VERSION ""

NS_ :

BS_:

BU_: WRCS SRS LECM1 ECUspare6 CIOM CCM

BO_ 2566356800 CIOM_Cab_25S: 13 CIOM
 SG_ PHTimerTGWEvCmd_Timer3Recur_ISig : 28|4@1+ (1,0) [0|0] ""  CCM
 SG_ PHTimerTGWEvCmd_PhTimer1_cmd_ISi : 5|3@1+ (1,0) [0|0] ""  CCM
 SG_ PHTimerTGWEvCmd_Timer2Minutes_IS : 72|8@1+ (1,0) [0|255] "min"  CCM
 SG_ PHTimerTGWEvCmd_Timer2Hours_ISig : 48|8@1+ (1,0) [0|255] "h"  CCM
 SG_ PHTimerTGWEvCmd_Timer1Hours_ISig : 56|8@1+ (1,0) [0|255] "h"  CCM
 SG_ PHTimerTGWEvCmd_Timer3StartDay_I : 40|4@1+ (1,0) [0|0] ""  CCM
 SG_ PHTimerTGWEvCmd_Timer1Temp_ISig_ : 8|5@1+ (1,0) [0|0] ""  CCM
 SG_ PHTimerTGWEvCmd_Timer1Minutes_IS : 80|8@1+ (1,0) [0|255] "min"  CCM
 SG_ PHTimerTGWEvCmd_Timer2StartDay_I : 36|4@1+ (1,0) [0|0] ""  CCM
 SG_ PHTimerTGWEvCmd_PhTimer2_cmd_ISi : 21|3@1+ (1,0) [0|0] ""  CCM
 SG_ PHTimerTGWEvCmd_Timer2Temp_ISig_ : 16|5@1+ (1,0) [0|0] ""  CCM
 SG_ PHTimerTGWEvCmd_Timer1Duration_I : 96|7@1+ (1,0) [0|127] "min"  CCM
 SG_ PHTimerTGWEvCmd_Timer3Minutes_IS : 64|8@1+ (1,0) [0|255] "min"  CCM
 SG_ PHTimerTGWEvCmd_Timer1StartDay_I : 32|4@1+ (1,0) [0|0] ""  CCM
 SG_ PHTimerTGWEvCmd_Timer1Recur_ISig : 24|4@1+ (1,0) [0|0] ""  CCM
 SG_ PHTimerTGWEvCmd_Timer2Recur_ISig : 44|4@1+ (1,0) [0|0] ""  CCM
 SG_ PHTimerTGWEvCmd_PhTimer3_cmd_ISi : 13|3@1+ (1,0) [0|0] ""  CCM
 SG_ PHTimerTGWEvCmd_Timer3Temp_ISig_ : 0|5@1+ (1,0) [0|0] ""  CCM
 SG_ PHTimerTGWEvCmd_Timer3Hours_ISig : 88|8@1+ (1,0) [0|255] "h"  CCM

BO_ 2516128064 CIOM_Cab_24P: 8 CIOM
 SG_ Trailer1LiftAxles_LiftAxle2Id_IS : 4|4@1+ (1,0) [0|15] "ID"  WRCS
 SG_ Trailer4LiftAxles_LiftAxle1Pos_I : 44|2@1+ (1,0) [0|0] ""  WRCS
 SG_ Trailer2LiftAxles_LiftAxle1Pos_I : 20|2@1+ (1,0) [0|0] ""  WRCS
 SG_ Trailer2LiftAxles_LiftAxle2Id_IS : 16|4@1+ (1,0) [0|15] "ID"  WRCS
 SG_ Trailer2LiftAxles_LiftAxle2Pos_I : 22|2@1+ (1,0) [0|0] ""  WRCS
 SG_ Trailer4LiftAxles_LiftAxle2Pos_I : 46|2@1+ (1,0) [0|0] ""  WRCS
 SG_ Trailer5LiftAxles_LiftAxle2Id_IS : 52|4@1+ (1,0) [0|15] "ID"  WRCS
 SG_ Trailer4LiftAxles_LiftAxle1Id_IS : 36|4@1+ (1,0) [0|15] "ID"  WRCS
 SG_ Trailer3LiftAxles_LiftAxle2Id_IS : 28|4@1+ (1,0) [0|15] "ID"  WRCS
 SG_ Trailer2LiftAxles_LiftAxle1Id_IS : 12|4@1+ (1,0) [0|15] "ID"  WRCS
 SG_ Trailer5LiftAxles_LiftAxle1Pos_I : 56|2@1+ (1,0) [0|0] ""  WRCS
 SG_ Trailer1LiftAxles_LiftAxle1Id_IS : 0|4@1+ (1,0) [0|15] "ID"  WRCS
 SG_ Trailer3LiftAxles_LiftAxle1Pos_I : 32|2@1+ (1,0) [0|0] ""  WRCS
 SG_ Trailer5LiftAxles_LiftAxle1Id_IS : 48|4@1+ (1,0) [0|15] "ID"  WRCS
 SG_ Trailer1LiftAxles_LiftAxle2Pos_I : 10|2@1+ (1,0) [0|0] ""  WRCS
 SG_ Trailer5LiftAxles_LiftAxle2Pos_I : 58|2@1+ (1,0) [0|0] ""  WRCS
 SG_ Trailer3LiftAxles_LiftAxle1Id_IS : 24|4@1+ (1,0) [0|15] "ID"  WRCS
 SG_ Trailer1LiftAxles_LiftAxle1Pos_I : 8|2@1+ (1,0) [0|0] ""  WRCS
 SG_ Trailer3LiftAxles_LiftAxle2Pos_I : 34|2@1+ (1,0) [0|0] ""  WRCS
 SG_ Trailer4LiftAxles_LiftAxle2Id_IS : 40|4@1+ (1,0) [0|15] "ID"  WRCS

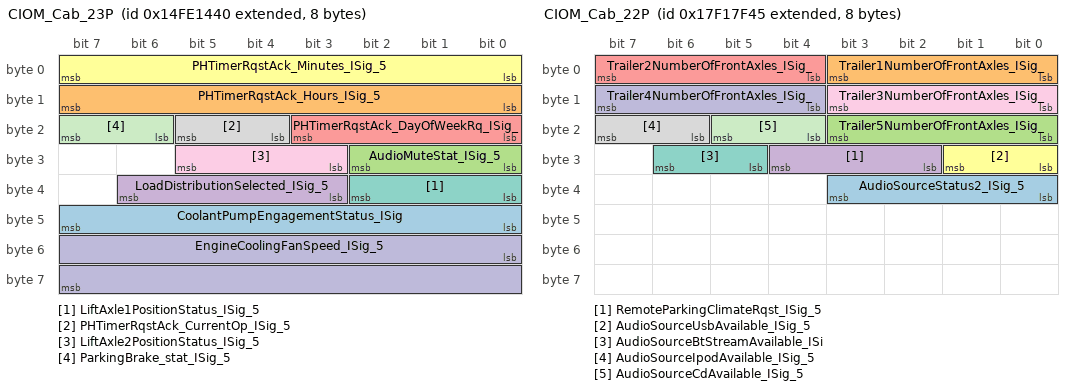
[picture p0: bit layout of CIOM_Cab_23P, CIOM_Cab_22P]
BO_ 2499679296 CIOM_Cab_23P: 8 CIOM
 SG_ CoolantPumpEngagementStatus_ISig : 40|8@1+ (0.4,0) [0|102] "Percent"  CCM
 SG_ PHTimerRqstAck_Hours_ISig_5 : 8|8@1+ (1,0) [0|255] "h"  CCM
 SG_ AudioMuteStat_ISig_5 : 24|3@1+ (1,0) [0|0] ""  LECM1
 SG_ LoadDistributionSelected_ISig_5 : 35|4@1+ (1,0) [0|0] ""  WRCS
 SG_ PHTimerRqstAck_DayOfWeekRq_ISig_ : 16|4@1+ (1,0) [0|0] ""  CCM
 SG_ PHTimerRqstAck_Minutes_ISig_5 : 0|8@1+ (1,0) [0|255] "min"  CCM
 SG_ LiftAxle1PositionStatus_ISig_5 : 32|3@1+ (1,0) [0|0] ""  WRCS
 SG_ PHTimerRqstAck_CurrentOp_ISig_5 : 20|2@1+ (1,0) [0|0] ""  CCM
 SG_ LiftAxle2PositionStatus_ISig_5 : 27|3@1+ (1,0) [0|0] ""  WRCS
 SG_ EngineCoolingFanSpeed_ISig_5 : 48|16@1+ (1,0) [0|65535] "rpm"  CCM
 SG_ ParkingBrake_stat_ISig_5 : 22|2@1+ (1,0) [0|0] ""  WRCS

BO_ 2549186373 CIOM_Cab_22P: 8 CIOM
 SG_ AudioSourceStatus2_ISig_5 : 32|4@1+ (1,0) [0|0] ""  LECM1
 SG_ Trailer1NumberOfFrontAxles_ISig_ : 0|4@1+ (1,0) [0|15] "NotApplicable"  WRCS
 SG_ Trailer5NumberOfFrontAxles_ISig_ : 16|4@1+ (1,0) [0|15] "NotApplicable"  WRCS
 SG_ RemoteParkingClimateRqst_ISig_5 : 26|3@1+ (1,0) [0|0] ""  CCM
 SG_ Trailer2NumberOfFrontAxles_ISig_ : 4|4@1+ (1,0) [0|15] "NotApplicable"  WRCS
 SG_ AudioSourceUsbAvailable_ISig_5 : 24|2@1+ (1,0) [0|0] ""  LECM1
 SG_ AudioSourceBtStreamAvailable_ISi : 29|2@1+ (1,0) [0|0] ""  LECM1
 SG_ AudioSourceIpodAvailable_ISig_5 : 22|2@1+ (1,0) [0|0] ""  LECM1
 SG_ Trailer3NumberOfFrontAxles_ISig_ : 8|4@1+ (1,0) [0|15] "NotApplicable"  WRCS
 SG_ Trailer4NumberOfFrontAxles_ISig_ : 12|4@1+ (1,0) [0|15] "NotApplicable"  WRCS
 SG_ AudioSourceCdAvailable_ISig_5 : 20|2@1+ (1,0) [0|0] ""  LECM1

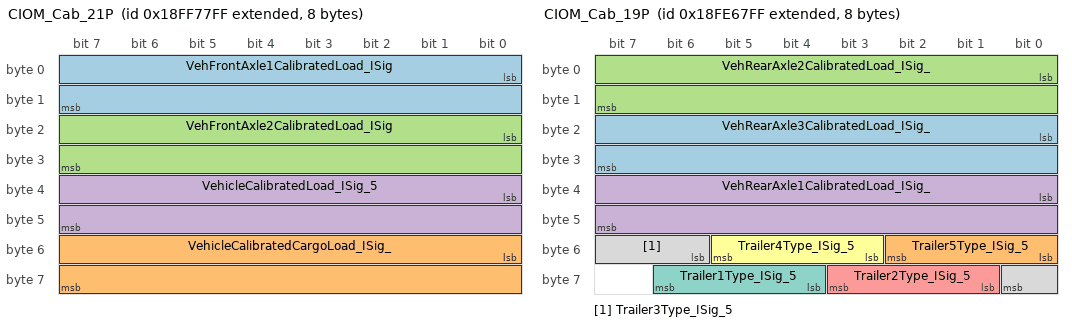
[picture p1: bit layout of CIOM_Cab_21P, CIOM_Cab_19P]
BO_ 2566879231 CIOM_Cab_21P: 8 CIOM
 SG_ VehFrontAxle1CalibratedLoad_ISig : 0|16@1+ (0.5,0) [0|32767.5] "kg"  WRCS
 SG_ VehicleCalibratedCargoLoad_ISig_ : 48|16@1+ (2,0) [0|131070] "kg"  WRCS
 SG_ VehFrontAxle2CalibratedLoad_ISig : 16|16@1+ (0.5,0) [0|32767.5] "kg"  WRCS
 SG_ VehicleCalibratedLoad_ISig_5 : 32|16@1+ (2,0) [0|131070] "kg"  WRCS

BO_ 2566864832 CIOM_Cab_20S_FCM: 8 LECM1
 SG_ CIOM_Cab_20S_FCS : 0|64@1+ (1,0) [0|0] ""  CIOM

BO_ 2566864831 CIOM_Cab_20S: 36 CIOM
 SG_ DisplayText_stat_ISig_5 : 0|288@1+ (1,0) [0|0] ""  LECM1

BO_ 2566809599 CIOM_Cab_19P: 8 CIOM
 SG_ VehRearAxle3CalibratedLoad_ISig_ : 16|16@1+ (0.5,0) [0|32767.5] "kg"  WRCS
 SG_ Trailer5Type_ISig_5 : 48|3@1+ (1,0) [0|0] ""  WRCS
 SG_ VehRearAxle2CalibratedLoad_ISig_ : 0|16@1+ (0.5,0) [0|32767.5] "kg"  WRCS
 SG_ VehRearAxle1CalibratedLoad_ISig_ : 32|16@1+ (0.5,0) [0|32767.5] "kg"  WRCS
 SG_ Trailer2Type_ISig_5 : 57|3@1+ (1,0) [0|0] ""  WRCS
 SG_ Trailer4Type_ISig_5 : 51|3@1+ (1,0) [0|0] ""  WRCS
 SG_ Trailer1Type_ISig_5 : 60|3@1+ (1,0) [0|0] ""  WRCS
 SG_ Trailer3Type_ISig_5 : 54|3@1+ (1,0) [0|0] ""  WRCS

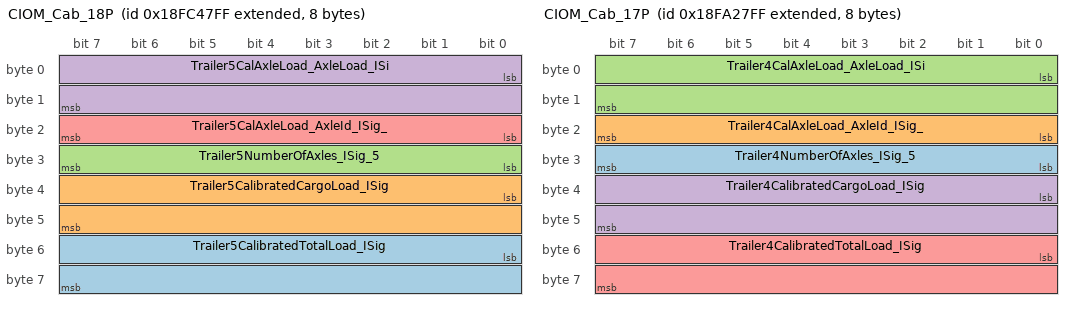
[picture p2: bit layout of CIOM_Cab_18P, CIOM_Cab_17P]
BO_ 2566670335 CIOM_Cab_18P: 8 CIOM
 SG_ Trailer5CalibratedTotalLoad_ISig : 48|16@1+ (2,0) [0|131070] "kg"  WRCS
 SG_ Trailer5CalibratedCargoLoad_ISig : 32|16@1+ (2,0) [0|131070] "kg"  WRCS
 SG_ Trailer5NumberOfAxles_ISig_5 : 24|8@1+ (1,0) [0|255] "NotApplicable"  WRCS
 SG_ Trailer5CalAxleLoad_AxleLoad_ISi : 0|16@1+ (0.5,0) [0|32767.5] "kg"  WRCS
 SG_ Trailer5CalAxleLoad_AxleId_ISig_ : 16|8@1+ (1,0) [0|255] "NotApplicable"  WRCS

BO_ 2566531071 CIOM_Cab_17P: 8 CIOM
 SG_ Trailer4NumberOfAxles_ISig_5 : 24|8@1+ (1,0) [0|255] "NotApplicable"  WRCS
 SG_ Trailer4CalAxleLoad_AxleId_ISig_ : 16|8@1+ (1,0) [0|255] "NotApplicable"  WRCS
 SG_ Trailer4CalAxleLoad_AxleLoad_ISi : 0|16@1+ (0.5,0) [0|32767.5] "kg"  WRCS
 SG_ Trailer4CalibratedCargoLoad_ISig : 32|16@1+ (2,0) [0|131070] "kg"  WRCS
 SG_ Trailer4CalibratedTotalLoad_ISig : 48|16@1+ (2,0) [0|131070] "kg"  WRCS

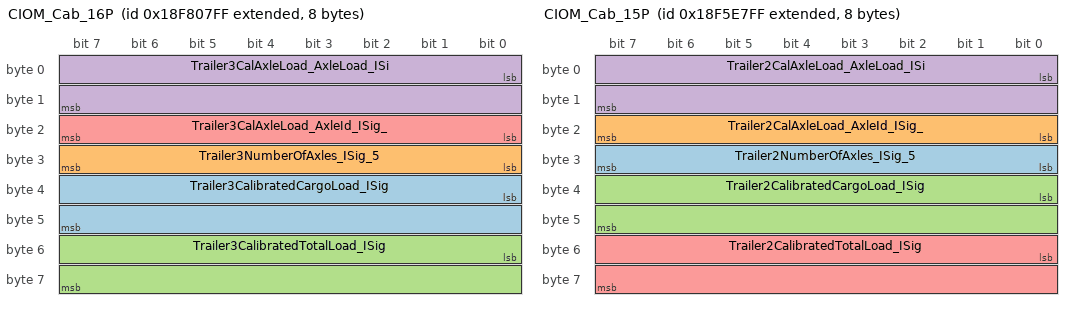
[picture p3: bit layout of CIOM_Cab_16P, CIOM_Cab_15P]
BO_ 2566391807 CIOM_Cab_16P: 8 CIOM
 SG_ Trailer3CalibratedCargoLoad_ISig : 32|16@1+ (2,0) [0|131070] "kg"  WRCS
 SG_ Trailer3NumberOfAxles_ISig_5 : 24|8@1+ (1,0) [0|255] "NotApplicable"  WRCS
 SG_ Trailer3CalibratedTotalLoad_ISig : 48|16@1+ (2,0) [0|131070] "kg"  WRCS
 SG_ Trailer3CalAxleLoad_AxleLoad_ISi : 0|16@1+ (0.5,0) [0|32767.5] "kg"  WRCS
 SG_ Trailer3CalAxleLoad_AxleId_ISig_ : 16|8@1+ (1,0) [0|255] "NotApplicable"  WRCS

BO_ 2566252543 CIOM_Cab_15P: 8 CIOM
 SG_ Trailer2NumberOfAxles_ISig_5 : 24|8@1+ (1,0) [0|255] "NotApplicable"  WRCS
 SG_ Trailer2CalAxleLoad_AxleId_ISig_ : 16|8@1+ (1,0) [0|255] "NotApplicable"  WRCS
 SG_ Trailer2CalibratedCargoLoad_ISig : 32|16@1+ (2,0) [0|131070] "kg"  WRCS
 SG_ Trailer2CalAxleLoad_AxleLoad_ISi : 0|16@1+ (0.5,0) [0|32767.5] "kg"  WRCS
 SG_ Trailer2CalibratedTotalLoad_ISig : 48|16@1+ (2,0) [0|131070] "kg"  WRCS

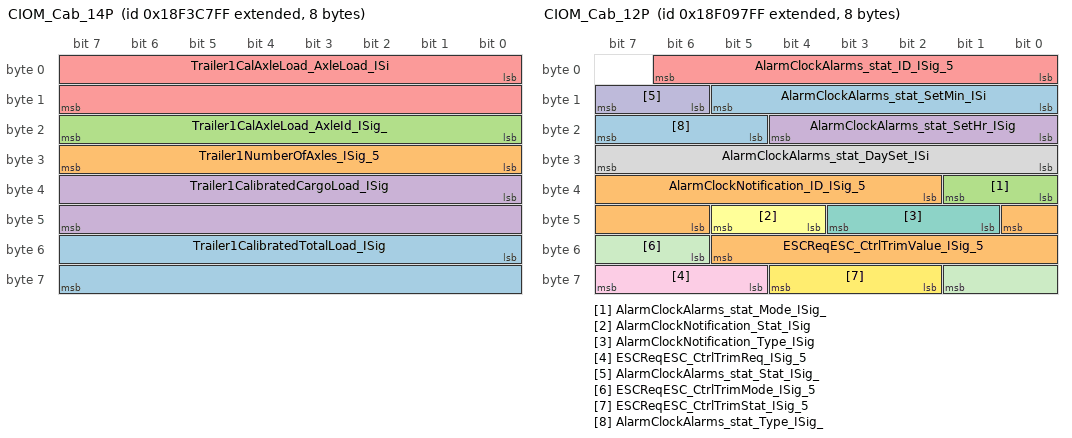
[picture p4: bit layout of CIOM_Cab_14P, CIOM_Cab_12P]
BO_ 2566113279 CIOM_Cab_14P: 8 CIOM
 SG_ Trailer1CalibratedTotalLoad_ISig : 48|16@1+ (2,0) [0|131070] "kg"  WRCS
 SG_ Trailer1NumberOfAxles_ISig_5 : 24|8@1+ (1,0) [0|255] "NotApplicable"  WRCS
 SG_ Trailer1CalAxleLoad_AxleId_ISig_ : 16|8@1+ (1,0) [0|255] "NotApplicable"  WRCS
 SG_ Trailer1CalibratedCargoLoad_ISig : 32|16@1+ (2,0) [0|131070] "kg"  WRCS
 SG_ Trailer1CalAxleLoad_AxleLoad_ISi : 0|16@1+ (0.5,0) [0|32767.5] "kg"  WRCS

BO_ 2565974016 CIOM_Cab_13S_FCM: 8 WRCS
 SG_ CIOM_Cab_13S_FCS : 0|64@1+ (1,0) [0|0] ""  CIOM

BO_ 2565974015 CIOM_Cab_13S: 128 CIOM
 SG_ FdEquipmentFreeText_ISig_5 : 0|1024@1+ (1,0) [0|0] ""  WRCS

BO_ 2565904383 CIOM_Cab_12P: 8 CIOM
 SG_ AlarmClockAlarms_stat_SetMin_ISi : 8|6@1+ (1,0) [0|63] "min"  LECM1
 SG_ ESCReqESC_CtrlTrimValue_ISig_5 : 46|8@1+ (10,0) [0|2550] ""  WRCS
 SG_ AlarmClockAlarms_stat_Mode_ISig_ : 32|2@1+ (1,0) [0|0] ""  LECM1
 SG_ AlarmClockAlarms_stat_SetHr_ISig : 16|5@1+ (1,0) [0|31] "h"  LECM1
 SG_ AlarmClockAlarms_stat_ID_ISig_5 : 0|7@1+ (1,0) [0|0] ""  LECM1
 SG_ AlarmClockNotification_Stat_ISig : 44|2@1+ (1,0) [0|0] ""  LECM1
 SG_ AlarmClockNotification_Type_ISig : 41|3@1+ (1,0) [0|0] ""  LECM1
 SG_ AlarmClockAlarms_stat_DaySet_ISi : 24|8@1+ (1,0) [0|255] ""  LECM1
 SG_ ESCReqESC_CtrlTrimReq_ISig_5 : 61|3@1+ (1,0) [0|0] ""  WRCS
 SG_ AlarmClockAlarms_stat_Stat_ISig_ : 14|2@1+ (1,0) [0|0] ""  LECM1
 SG_ ESCReqESC_CtrlTrimMode_ISig_5 : 54|4@1+ (1,0) [0|0] ""  WRCS
 SG_ ESCReqESC_CtrlTrimStat_ISig_5 : 58|3@1+ (1,0) [0|0] ""  WRCS
 SG_ AlarmClockAlarms_stat_Type_ISig_ : 21|3@1+ (1,0) [0|0] ""  LECM1
 SG_ AlarmClockNotification_ID_ISig_5 : 34|7@1+ (1,0) [0|0] ""  LECM1

BO_ 2565834752 CIOM_Cab_11S_FCM: 8 SRS
 SG_ CIOM_Cab_11S_FCS : 0|64@1+ (1,0) [0|0] ""  CIOM

BO_ 2565834751 CIOM_Cab_11S: 11 CIOM
 SG_ ECUVIN_stat : 0|88@1+ (1,0) [0|0] ""  SRS

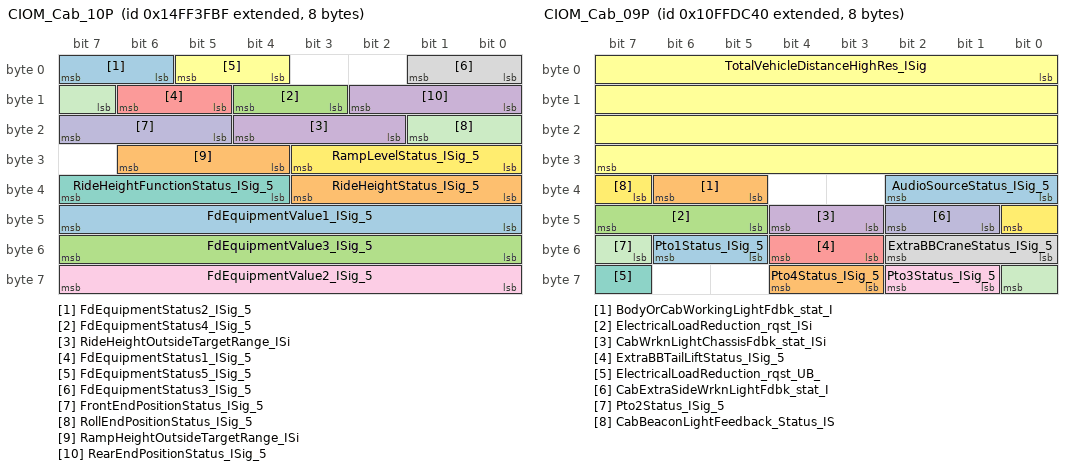
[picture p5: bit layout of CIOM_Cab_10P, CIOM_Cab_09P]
BO_ 2499755967 CIOM_Cab_10P: 8 CIOM
 SG_ FdEquipmentStatus2_ISig_5 : 6|2@1+ (1,0) [0|0] ""  WRCS
 SG_ RideHeightStatus_ISig_5 : 32|4@1+ (1,0) [0|0] ""  WRCS
 SG_ FdEquipmentStatus4_ISig_5 : 11|2@1+ (1,0) [0|0] ""  WRCS
 SG_ RideHeightOutsideTargetRange_ISi : 18|3@1+ (1,0) [0|0] ""  WRCS
 SG_ FdEquipmentStatus1_ISig_5 : 13|2@1+ (1,0) [0|0] ""  WRCS
 SG_ FdEquipmentStatus5_ISig_5 : 4|2@1+ (1,0) [0|0] ""  WRCS
 SG_ RideHeightFunctionStatus_ISig_5 : 36|4@1+ (1,0) [0|0] ""  WRCS
 SG_ FdEquipmentStatus3_ISig_5 : 0|2@1+ (1,0) [0|0] ""  WRCS
 SG_ FdEquipmentValue2_ISig_5 : 56|8@1+ (0.5,0) [0|127.5] "Percent"  WRCS
 SG_ FrontEndPositionStatus_ISig_5 : 21|3@1+ (1,0) [0|0] ""  WRCS
 SG_ RollEndPositionStatus_ISig_5 : 15|3@1+ (1,0) [0|0] ""  WRCS
 SG_ RampLevelStatus_ISig_5 : 24|4@1+ (1,0) [0|0] ""  WRCS
 SG_ FdEquipmentValue1_ISig_5 : 40|8@1+ (0.5,0) [0|127.5] "Percent"  WRCS
 SG_ RampHeightOutsideTargetRange_ISi : 28|3@1+ (1,0) [0|0] ""  WRCS
 SG_ FdEquipmentValue3_ISig_5 : 48|8@1+ (0.5,0) [0|127.5] "Percent"  WRCS
 SG_ RearEndPositionStatus_ISig_5 : 8|3@1+ (1,0) [0|0] ""  WRCS

BO_ 2432687168 CIOM_Cab_09P: 8 CIOM
 SG_ Pto1Status_ISig_5 : 53|2@1+ (1,0) [0|0] ""  WRCS
 SG_ BodyOrCabWorkingLightFdbk_stat_I : 37|2@1+ (1,0) [0|0] ""  WRCS
 SG_ ElectricalLoadReduction_rqst_ISi : 45|3@1+ (1,0) [0|0] ""  CCM,WRCS
 SG_ CabWrknLightChassisFdbk_stat_ISi : 43|2@1+ (1,0) [0|0] ""  WRCS
 SG_ ExtraBBTailLiftStatus_ISig_5 : 51|2@1+ (1,0) [0|0] ""  WRCS
 SG_ TotalVehicleDistanceHighRes_ISig : 0|32@1+ (5,0) [0|21474836475] "m"  SRS,LECM1,WRCS,CCM
 SG_ ElectricalLoadReduction_rqst_UB_ : 63|1@1+ (1,0) [0|0] ""  CCM,WRCS
 SG_ ExtraBBCraneStatus_ISig_5 : 48|3@1+ (1,0) [0|0] ""  WRCS
 SG_ Pto3Status_ISig_5 : 57|2@1+ (1,0) [0|0] ""  WRCS
 SG_ CabExtraSideWrknLightFdbk_stat_I : 41|2@1+ (1,0) [0|0] ""  WRCS
 SG_ Pto2Status_ISig_5 : 55|2@1+ (1,0) [0|0] ""  WRCS
 SG_ CabBeaconLightFeedback_Status_IS : 39|2@1+ (1,0) [0|0] ""  WRCS
 SG_ AudioSourceStatus_ISig_5 : 32|3@1+ (1,0) [0|0] ""  LECM1
 SG_ Pto4Status_ISig_5 : 59|2@1+ (1,0) [0|0] ""  WRCS

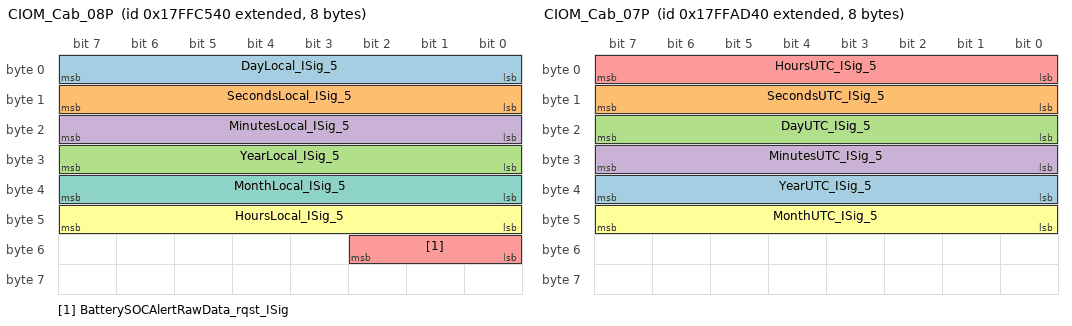
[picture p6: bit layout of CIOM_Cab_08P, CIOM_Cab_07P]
BO_ 2550121792 CIOM_Cab_08P: 8 CIOM
 SG_ DayLocal_ISig_5 : 0|8@1+ (0.25,0) [0|63.75] "Days"  CCM
 SG_ SecondsLocal_ISig_5 : 8|8@1+ (0.25,0) [0|63.75] "s"  CCM
 SG_ YearLocal_ISig_5 : 24|8@1+ (1,1985) [1985|2240] "Years"  CCM
 SG_ MinutesLocal_ISig_5 : 16|8@1+ (1,0) [0|255] "min"  CCM,LECM1
 SG_ BatterySOCAlertRawData_rqst_ISig : 48|3@1+ (1,0) [0|0] ""  CCM
 SG_ HoursLocal_ISig_5 : 40|8@1+ (1,0) [0|255] "h"  CCM,LECM1
 SG_ MonthLocal_ISig_5 : 32|8@1+ (1,0) [0|255] "Months"  CCM

BO_ 2550115648 CIOM_Cab_07P: 8 CIOM
 SG_ YearUTC_ISig_5 : 32|8@1+ (1,1985) [1985|2240] "Years"  LECM1,WRCS,SRS,CCM
 SG_ SecondsUTC_ISig_5 : 8|8@1+ (0.25,0) [0|63.75] "s"  LECM1,WRCS,CCM,SRS
 SG_ DayUTC_ISig_5 : 16|8@1+ (0.25,0) [0|63.75] "Days"  WRCS,SRS,LECM1,CCM
 SG_ MinutesUTC_ISig_5 : 24|8@1+ (1,0) [0|255] "min"  LECM1,CCM,WRCS,SRS
 SG_ HoursUTC_ISig_5 : 0|8@1+ (1,0) [0|255] "h"  LECM1,WRCS,SRS,CCM
 SG_ MonthUTC_ISig_5 : 40|8@1+ (1,0) [0|255] "Months"  WRCS,SRS,CCM,LECM1

BO_ 2432669248 CIOM_Cab_06P: 8 CIOM
 SG_ AuxSwitchBbLoad2_Status_ISig_5 : 22|2@1+ (1,0) [0|0] ""  WRCS
 SG_ DoorLock_stat_ISig_5 : 24|4@1+ (1,0) [0|0] ""  LECM1,WRCS
 SG_ MirrorHeatNormalModeInd_cmd_2_IS : 61|2@1+ (1,0) [0|0] ""  CCM
 SG_ PSWindowPosition_ISig_5 : 8|3@1+ (1,0) [0|0] ""  CCM
 SG_ AuxSwitchBbLoad1_Status_ISig_5 : 14|2@1+ (1,0) [0|0] ""  WRCS
 SG_ ReducedLoadMode_stat_ISig_5 : 0|2@1+ (1,0) [0|0] ""  CCM
 SG_ TrailersConnected_ISig_5 : 58|3@1+ (1,0) [0|7] "Count"  WRCS
 SG_ DriverDoorAjar_stat_ISig_5 : 4|3@1+ (1,0) [0|0] ""  CCM
 SG_ AuxSwitchBbLoad6_Status_ISig_5 : 56|2@1+ (1,0) [0|0] ""  WRCS
 SG_ BunkBacklightCmd_ISig_5 : 32|5@1+ (1,0) [0|0] ""  LECM1
 SG_ AuxSwitchBbLoad4_Status_ISig_5 : 46|2@1+ (1,0) [0|0] ""  WRCS
 SG_ DSWindowPosition_ISig_5 : 11|3@1+ (1,0) [0|0] ""  CCM
 SG_ SelectedLanguage_stat_ISig_5 : 40|6@1+ (1,0) [0|0] ""  LECM1,WRCS
 SG_ PassengerDoorAjar_stat_ISig_5 : 19|3@1+ (1,0) [0|0] ""  CCM
 SG_ BunkB1ParkHeaterTempSw_stat : 16|3@1+ (1,0) [0|0] ""  CCM
 SG_ AuxSwitchBbLoad5_Status_ISig_5 : 54|2@1+ (1,0) [0|0] ""  WRCS
 SG_ AudioVolumeIndicationCmd_ISig_5 : 48|6@1+ (1,0) [0|63] "Step"  LECM1
 SG_ AuxSwitchBbLoad3_Status_ISig_5 : 37|2@1+ (1,0) [0|0] ""  WRCS
 SG_ BunkH2TempInc_ButtonStatus : 2|2@1+ (1,0) [0|0] ""  CCM
 SG_ DayOfWeek_stat_ISig_5 : 28|4@1+ (1,0) [0|0] ""  CCM,LECM1

CM_ SG_ 2566356800 PHTimerTGWEvCmd_Timer2Minutes_IS "254 Error ; 255 Not available";
CM_ SG_ 2566356800 PHTimerTGWEvCmd_Timer2Hours_ISig "254 Error ; 255 Not available";
CM_ SG_ 2566356800 PHTimerTGWEvCmd_Timer1Hours_ISig "254 Error ; 255 Not available";
CM_ SG_ 2566356800 PHTimerTGWEvCmd_Timer1Minutes_IS "254 Error ; 255 Not available";
CM_ SG_ 2566356800 PHTimerTGWEvCmd_Timer1Duration_I "126 Error ; 127 Not available";
CM_ SG_ 2566356800 PHTimerTGWEvCmd_Timer3Minutes_IS "254 Error ; 255 Not available";
CM_ SG_ 2566356800 PHTimerTGWEvCmd_Timer3Hours_ISig "254 Error ; 255 Not available";
CM_ SG_ 2566879231 VehFrontAxle1CalibratedLoad_ISig "65024 - 65279 Error ; 65280 - 65535 Not available";
CM_ SG_ 2566879231 VehicleCalibratedCargoLoad_ISig_ "65024 - 65279 Error ; 65280 - 65535 Not Available";
CM_ SG_ 2566879231 VehFrontAxle2CalibratedLoad_ISig "65024 - 65279 Error ; 65280 - 65535 Not available";
CM_ SG_ 2566879231 VehicleCalibratedLoad_ISig_5 "65024 - 65279 Error ; 65280 - 65535 Not Available";
CM_ SG_ 2566809599 VehRearAxle3CalibratedLoad_ISig_ "65024 - 65279 Error ; 65280 - 65535 Not available";
CM_ SG_ 2566809599 VehRearAxle2CalibratedLoad_ISig_ "65024 - 65279 Error ; 65280 - 65535 Not available";
CM_ SG_ 2566809599 VehRearAxle1CalibratedLoad_ISig_ "65024 - 65279 Error ; 65280 - 65535 Not available";
CM_ SG_ 2566670335 Trailer5CalibratedTotalLoad_ISig "65024 - 65279 Error ; 65280 - 65535 Not Available";
CM_ SG_ 2566670335 Trailer5CalibratedCargoLoad_ISig "65024 - 65279 Error ; 65280 - 65535 Not Available";
CM_ SG_ 2566670335 Trailer5NumberOfAxles_ISig_5 "254 Error ; 255 Not Available";
CM_ SG_ 2566670335 Trailer5CalAxleLoad_AxleLoad_ISi "65024 - 65279 Error ; 65280 - 65535 Not available";
CM_ SG_ 2566531071 Trailer4NumberOfAxles_ISig_5 "254 Error ; 255 Not Available";
CM_ SG_ 2566531071 Trailer4CalAxleLoad_AxleLoad_ISi "65024 - 65279 Error ; 65280 - 65535 Not available";
CM_ SG_ 2566531071 Trailer4CalibratedCargoLoad_ISig "65024 - 65279 Error ; 65280 - 65535 Not Available";
CM_ SG_ 2566531071 Trailer4CalibratedTotalLoad_ISig "65024 - 65279 Error ; 65280 - 65535 Not Available";
CM_ SG_ 2566391807 Trailer3CalibratedCargoLoad_ISig "65024 - 65279 Error ; 65280 - 65535 Not Available";
CM_ SG_ 2566391807 Trailer3NumberOfAxles_ISig_5 "254 Error ; 255 Not Available";
CM_ SG_ 2566391807 Trailer3CalibratedTotalLoad_ISig "65024 - 65279 Error ; 65280 - 65535 Not Available";
CM_ SG_ 2566391807 Trailer3CalAxleLoad_AxleLoad_ISi "65024 - 65279 Error ; 65280 - 65535 Not available";
CM_ SG_ 2566252543 Trailer2NumberOfAxles_ISig_5 "254 Error ; 255 Not Available";
CM_ SG_ 2566252543 Trailer2CalibratedCargoLoad_ISig "65024 - 65279 Error ; 65280 - 65535 Not Available";
CM_ SG_ 2566252543 Trailer2CalAxleLoad_AxleLoad_ISi "65024 - 65279 Error ; 65280 - 65535 Not available";
CM_ SG_ 2566252543 Trailer2CalibratedTotalLoad_ISig "65024 - 65279 Error ; 65280 - 65535 Not Available";
CM_ SG_ 2566113279 Trailer1CalibratedTotalLoad_ISig "65024 - 65279 Error ; 65280 - 65535 Not Available";
CM_ SG_ 2566113279 Trailer1NumberOfAxles_ISig_5 "254 Error ; 255 Not Available";
CM_ SG_ 2566113279 Trailer1CalibratedCargoLoad_ISig "65024 - 65279 Error ; 65280 - 65535 Not Available";
CM_ SG_ 2566113279 Trailer1CalAxleLoad_AxleLoad_ISi "65024 - 65279 Error ; 65280 - 65535 Not available";
CM_ SG_ 2565904383 AlarmClockAlarms_stat_SetMin_ISi "62 Error ; 63 Not Available";
CM_ SG_ 2565904383 ESCReqESC_CtrlTrimValue_ISig_5 "254 Error ; 255 Not available";
CM_ SG_ 2565904383 AlarmClockAlarms_stat_SetHr_ISig "30 Error ; 31 Not Available";
CM_ SG_ 2499755967 FdEquipmentValue2_ISig_5 "254 Error ; 255 Not available";
CM_ SG_ 2499755967 FdEquipmentValue1_ISig_5 "254 Error ; 255 Not available";
CM_ SG_ 2499755967 FdEquipmentValue3_ISig_5 "254 Error ; 255 Not available";
CM_ SG_ 2432687168 TotalVehicleDistanceHighRes_ISig "4261412864 - 4278190079 Error ; 4278190080 - 4294967295 Not available";
CM_ SG_ 2550121792 DayLocal_ISig_5 "254 Error ; 255 Not available";
CM_ SG_ 2550121792 SecondsLocal_ISig_5 "254 Error ; 255 Not available";
CM_ SG_ 2550121792 YearLocal_ISig_5 "254 Error ; 255 Not available";
CM_ SG_ 2550121792 MinutesLocal_ISig_5 "254 Error ; 255 Not available";
CM_ SG_ 2550121792 HoursLocal_ISig_5 "254 Error ; 255 Not available";
CM_ SG_ 2550121792 MonthLocal_ISig_5 "254 Error ; 255 Not available";
CM_ SG_ 2550115648 YearUTC_ISig_5 "254 Error ; 255 Not available";
CM_ SG_ 2550115648 SecondsUTC_ISig_5 "254 Error ; 255 Not available";
CM_ SG_ 2550115648 DayUTC_ISig_5 "254 Error ; 255 Not available";
CM_ SG_ 2550115648 MinutesUTC_ISig_5 "254 Error ; 255 Not available";
CM_ SG_ 2550115648 HoursUTC_ISig_5 "254 Error ; 255 Not available";
CM_ SG_ 2550115648 MonthUTC_ISig_5 "254 Error ; 255 Not available";
CM_ SG_ 2432669248 TrailersConnected_ISig_5 "6 Error ; 7 Not available";
BA_DEF_ BO_  "GenMsgStartDelayTime" INT 0 0;
BA_DEF_ BO_  "GenMsgDelayTime" INT 0 0;
BA_DEF_ BO_  "GenMsgCycleTime" INT 0 0;
BA_DEF_ BO_  "GenMsgSendType" ENUM  "Cyclic","NotUsed","NotUsed","NotUsed","NotUsed","NotUsed","NotUsed","IfActive","NoMsgSendType","NotUsed";
BA_DEF_ SG_  "GenSigStartValue" INT 0 0;
BA_DEF_ SG_  "GenSigCycleTimeActive" INT 0 0;
BA_DEF_ SG_  "GenSigCycleTime" INT 0 0;
BA_DEF_ SG_  "GenSigSendType" ENUM  "Cyclic","OnWrite","OnWriteWithRepetition","OnChange","OnChangeWithRepetition","IfActive","IfActiveWithRepetition","NoSigSendType","NotUsed","NotUsed","NotUsed","NotUsed","NotUsed";
BA_DEF_ BO_  "VFrameFormat" ENUM  "StandardCAN","ExtendedCAN","reserved","J1939PG";
BA_DEF_ SG_  "SigType" ENUM  "Default","Range","RangeSigned","ASCII","Discrete","Control","ReferencePGN","DTC","StringDelimiter","StringLength","StringLengthControl";
BA_DEF_ SG_  "SeToolVersion_SIGNAL" STRING ;
BA_DEF_ SG_  "SeToolUniqueID_SIGNAL" STRING ;
BA_DEF_ SG_  "SeToolOwnerSigGroup_SIGNAL" STRING ;
BA_DEF_ SG_  "SeToolOwnerSigGroupID_SIGNAL" STRING ;
BA_DEF_ SG_  "SeToolName_SIGNAL" STRING ;
BA_DEF_ SG_  "SeToolItemID_SIGNAL" STRING ;
BA_DEF_ SG_  "SeToolAncestorID_SIGNAL" STRING ;
BA_DEF_ BO_  "NmAsrMessage" ENUM  "No","Yes";
BA_DEF_ SG_  "NeedsUpdateBit" ENUM  "No","Yes";
BA_DEF_ SG_  "MmAnSignal" ENUM  "No","Yes";
BA_DEF_ SG_  "GenSigMaxLatency" INT 0 65535;
BA_DEF_ SG_  "GenSigILSupport" ENUM  "Yes","No";
BA_DEF_ BO_  "GenMsgRequestable" INT 0 1;
BA_DEF_ BO_  "GenMsgILSupport" ENUM  "No","Yes";
BA_DEF_ BO_  "DiagUUDTResponse" ENUM  "No","Yes";
BA_DEF_ BO_  "DiagState" ENUM  "No","Yes";
BA_DEF_ BO_  "DiagResponse" ENUM  "No","Yes";
BA_DEF_ BO_  "DiagRequest" ENUM  "No","Yes";
BA_DEF_ BO_  "DiagConnection" HEX 0 65535;
BA_DEF_ BO_  "CanTpSTmin" INT 0 255;
BA_DEF_ BO_  "CanTpFcFrameId" HEX 0 2147483647;
BA_DEF_ BO_  "CanTpBs" INT 0 255;
BA_DEF_ SG_  "SystemSignalLongSymbol" STRING ;
BA_DEF_REL_ BU_SG_REL_  "GenSigTimeoutTime" INT 0 65535;
BA_DEF_REL_ BU_SG_REL_  "GenSigFirstTimeoutTime" INT 0 65535;
BA_DEF_DEF_  "GenMsgStartDelayTime" 0;
BA_DEF_DEF_  "GenMsgDelayTime" 0;
BA_DEF_DEF_  "GenMsgCycleTime" 0;
BA_DEF_DEF_  "GenMsgSendType" "Cyclic";
BA_DEF_DEF_  "GenSigStartValue" 0;
BA_DEF_DEF_  "GenSigCycleTimeActive" 0;
BA_DEF_DEF_  "GenSigCycleTime" 0;
BA_DEF_DEF_  "GenSigSendType" "Cyclic";
BA_DEF_DEF_  "VFrameFormat" "ExtendedCAN";
BA_DEF_DEF_  "SigType" "Default";
BA_DEF_DEF_  "SeToolVersion_SIGNAL" "";
BA_DEF_DEF_  "SeToolUniqueID_SIGNAL" "";
BA_DEF_DEF_  "SeToolOwnerSigGroup_SIGNAL" "";
BA_DEF_DEF_  "SeToolOwnerSigGroupID_SIGNAL" "";
BA_DEF_DEF_  "SeToolName_SIGNAL" "";
BA_DEF_DEF_  "SeToolItemID_SIGNAL" "";
BA_DEF_DEF_  "SeToolAncestorID_SIGNAL" "";
BA_DEF_DEF_  "NmAsrMessage" "No";
BA_DEF_DEF_  "NeedsUpdateBit" "No";
BA_DEF_DEF_  "MmAnSignal" "No";
BA_DEF_DEF_  "GenSigMaxLatency" 0;
BA_DEF_DEF_  "GenSigILSupport" "Yes";
BA_DEF_DEF_  "GenMsgRequestable" 1;
BA_DEF_DEF_  "GenMsgILSupport" "Yes";
BA_DEF_DEF_  "DiagUUDTResponse" "No";
BA_DEF_DEF_  "DiagState" "No";
BA_DEF_DEF_  "DiagResponse" "No";
BA_DEF_DEF_  "DiagRequest" "No";
BA_DEF_DEF_  "DiagConnection" 0;
BA_DEF_DEF_  "CanTpSTmin" 0;
BA_DEF_DEF_  "CanTpFcFrameId" 2147483647;
BA_DEF_DEF_  "CanTpBs" 255;
BA_DEF_DEF_REL_ "GenSigTimeoutTime" 0;
BA_DEF_DEF_REL_ "GenSigFirstTimeoutTime" 0;
BA_DEF_DEF_  "SystemSignalLongSymbol" "";
BA_ "CanTpFcFrameId" BO_ 2566356800 418873153;
BA_ "GenMsgSendType" BO_ 2566356800 8;
BA_ "GenMsgDelayTime" BO_ 2566356800 130;
BA_ "GenMsgCycleTime" BO_ 2516128064 100;
BA_ "GenMsgCycleTime" BO_ 2499679296 50;
BA_ "GenMsgCycleTime" BO_ 2549186373 150;
BA_ "GenMsgStartDelayTime" BO_ 2549186373 15;
BA_ "GenMsgCycleTime" BO_ 2566879231 500;
BA_ "GenMsgStartDelayTime" BO_ 2566879231 155;
BA_ "GenMsgILSupport" BO_ 2566864832 0;
BA_ "GenMsgSendType" BO_ 2566864832 8;
BA_ "CanTpFcFrameId" BO_ 2566864831 419381184;
BA_ "GenMsgSendType" BO_ 2566864831 8;
BA_ "GenMsgDelayTime" BO_ 2566864831 200;
BA_ "GenMsgStartDelayTime" BO_ 2566864831 50;
BA_ "GenMsgCycleTime" BO_ 2566809599 500;
BA_ "GenMsgStartDelayTime" BO_ 2566809599 260;
BA_ "GenMsgCycleTime" BO_ 2566670335 500;
BA_ "GenMsgStartDelayTime" BO_ 2566670335 365;
BA_ "GenMsgCycleTime" BO_ 2566531071 500;
BA_ "GenMsgStartDelayTime" BO_ 2566531071 470;
BA_ "GenMsgCycleTime" BO_ 2566391807 500;
BA_ "GenMsgStartDelayTime" BO_ 2566391807 75;
BA_ "GenMsgCycleTime" BO_ 2566252543 500;
BA_ "GenMsgStartDelayTime" BO_ 2566252543 120;
BA_ "GenMsgCycleTime" BO_ 2566113279 500;
BA_ "GenMsgStartDelayTime" BO_ 2566113279 175;
BA_ "GenMsgILSupport" BO_ 2565974016 0;
BA_ "GenMsgSendType" BO_ 2565974016 8;
BA_ "CanTpFcFrameId" BO_ 2565974015 418490368;
BA_ "GenMsgSendType" BO_ 2565974015 8;
BA_ "GenMsgDelayTime" BO_ 2565974015 200;
BA_ "GenMsgStartDelayTime" BO_ 2565974015 50;
BA_ "GenMsgCycleTime" BO_ 2565904383 150;
BA_ "GenMsgStartDelayTime" BO_ 2565904383 75;
BA_ "CanTpSTmin" BO_ 2565834752 1;
BA_ "GenMsgILSupport" BO_ 2565834752 0;
BA_ "GenMsgSendType" BO_ 2565834752 8;
BA_ "CanTpFcFrameId" BO_ 2565834751 418351104;
BA_ "CanTpSTmin" BO_ 2565834751 5;
BA_ "GenMsgSendType" BO_ 2565834751 8;
BA_ "GenMsgDelayTime" BO_ 2565834751 100;
BA_ "GenMsgCycleTime" BO_ 2499755967 50;
BA_ "GenMsgStartDelayTime" BO_ 2499755967 5;
BA_ "GenMsgCycleTime" BO_ 2432687168 20;
BA_ "GenMsgStartDelayTime" BO_ 2432687168 5;
BA_ "GenMsgCycleTime" BO_ 2550121792 250;
BA_ "GenMsgStartDelayTime" BO_ 2550121792 25;
BA_ "GenMsgCycleTime" BO_ 2550115648 250;
BA_ "GenMsgStartDelayTime" BO_ 2550115648 50;
BA_ "GenMsgCycleTime" BO_ 2432669248 20;
BA_ "GenMsgStartDelayTime" BO_ 2432669248 10;
BA_ "GenSigSendType" SG_ 2566356800 PHTimerTGWEvCmd_Timer3Recur_ISig 1;
BA_ "GenSigStartValue" SG_ 2566356800 PHTimerTGWEvCmd_Timer3Recur_ISig 15;
BA_ "GenSigMaxLatency" SG_ 2566356800 PHTimerTGWEvCmd_Timer3Recur_ISig 150;
BA_ "SystemSignalLongSymbol" SG_ 2566356800 PHTimerTGWEvCmd_Timer3Recur_ISig "PHTimerTGWEvCmd_Timer3Recur_ISig_5";
BA_ "GenSigSendType" SG_ 2566356800 PHTimerTGWEvCmd_PhTimer1_cmd_ISi 1;
BA_ "GenSigStartValue" SG_ 2566356800 PHTimerTGWEvCmd_PhTimer1_cmd_ISi 7;
BA_ "GenSigMaxLatency" SG_ 2566356800 PHTimerTGWEvCmd_PhTimer1_cmd_ISi 150;
BA_ "SystemSignalLongSymbol" SG_ 2566356800 PHTimerTGWEvCmd_PhTimer1_cmd_ISi "PHTimerTGWEvCmd_PhTimer1_cmd_ISig_5";
BA_ "GenSigSendType" SG_ 2566356800 PHTimerTGWEvCmd_Timer2Minutes_IS 1;
BA_ "GenSigStartValue" SG_ 2566356800 PHTimerTGWEvCmd_Timer2Minutes_IS 255;
BA_ "GenSigMaxLatency" SG_ 2566356800 PHTimerTGWEvCmd_Timer2Minutes_IS 150;
BA_ "SystemSignalLongSymbol" SG_ 2566356800 PHTimerTGWEvCmd_Timer2Minutes_IS "PHTimerTGWEvCmd_Timer2Minutes_ISig_5";
BA_ "GenSigSendType" SG_ 2566356800 PHTimerTGWEvCmd_Timer2Hours_ISig 1;
BA_ "GenSigStartValue" SG_ 2566356800 PHTimerTGWEvCmd_Timer2Hours_ISig 255;
BA_ "GenSigMaxLatency" SG_ 2566356800 PHTimerTGWEvCmd_Timer2Hours_ISig 150;
BA_ "SystemSignalLongSymbol" SG_ 2566356800 PHTimerTGWEvCmd_Timer2Hours_ISig "PHTimerTGWEvCmd_Timer2Hours_ISig_5";
BA_ "GenSigSendType" SG_ 2566356800 PHTimerTGWEvCmd_Timer1Hours_ISig 1;
BA_ "GenSigStartValue" SG_ 2566356800 PHTimerTGWEvCmd_Timer1Hours_ISig 255;
BA_ "GenSigMaxLatency" SG_ 2566356800 PHTimerTGWEvCmd_Timer1Hours_ISig 150;
BA_ "SystemSignalLongSymbol" SG_ 2566356800 PHTimerTGWEvCmd_Timer1Hours_ISig "PHTimerTGWEvCmd_Timer1Hours_ISig_5";
BA_ "GenSigSendType" SG_ 2566356800 PHTimerTGWEvCmd_Timer3StartDay_I 1;
BA_ "GenSigStartValue" SG_ 2566356800 PHTimerTGWEvCmd_Timer3StartDay_I 15;
BA_ "GenSigMaxLatency" SG_ 2566356800 PHTimerTGWEvCmd_Timer3StartDay_I 150;
BA_ "SystemSignalLongSymbol" SG_ 2566356800 PHTimerTGWEvCmd_Timer3StartDay_I "PHTimerTGWEvCmd_Timer3StartDay_ISig_5";
BA_ "GenSigSendType" SG_ 2566356800 PHTimerTGWEvCmd_Timer1Temp_ISig_ 1;
BA_ "GenSigStartValue" SG_ 2566356800 PHTimerTGWEvCmd_Timer1Temp_ISig_ 31;
BA_ "GenSigMaxLatency" SG_ 2566356800 PHTimerTGWEvCmd_Timer1Temp_ISig_ 150;
BA_ "SystemSignalLongSymbol" SG_ 2566356800 PHTimerTGWEvCmd_Timer1Temp_ISig_ "PHTimerTGWEvCmd_Timer1Temp_ISig_5";
BA_ "GenSigSendType" SG_ 2566356800 PHTimerTGWEvCmd_Timer1Minutes_IS 1;
BA_ "GenSigStartValue" SG_ 2566356800 PHTimerTGWEvCmd_Timer1Minutes_IS 255;
BA_ "GenSigMaxLatency" SG_ 2566356800 PHTimerTGWEvCmd_Timer1Minutes_IS 150;
BA_ "SystemSignalLongSymbol" SG_ 2566356800 PHTimerTGWEvCmd_Timer1Minutes_IS "PHTimerTGWEvCmd_Timer1Minutes_ISig_5";
BA_ "GenSigSendType" SG_ 2566356800 PHTimerTGWEvCmd_Timer2StartDay_I 1;
BA_ "GenSigStartValue" SG_ 2566356800 PHTimerTGWEvCmd_Timer2StartDay_I 15;
BA_ "GenSigMaxLatency" SG_ 2566356800 PHTimerTGWEvCmd_Timer2StartDay_I 150;
BA_ "SystemSignalLongSymbol" SG_ 2566356800 PHTimerTGWEvCmd_Timer2StartDay_I "PHTimerTGWEvCmd_Timer2StartDay_ISig_5";
BA_ "GenSigSendType" SG_ 2566356800 PHTimerTGWEvCmd_PhTimer2_cmd_ISi 1;
BA_ "GenSigStartValue" SG_ 2566356800 PHTimerTGWEvCmd_PhTimer2_cmd_ISi 7;
BA_ "GenSigMaxLatency" SG_ 2566356800 PHTimerTGWEvCmd_PhTimer2_cmd_ISi 150;
BA_ "SystemSignalLongSymbol" SG_ 2566356800 PHTimerTGWEvCmd_PhTimer2_cmd_ISi "PHTimerTGWEvCmd_PhTimer2_cmd_ISig_5";
BA_ "GenSigSendType" SG_ 2566356800 PHTimerTGWEvCmd_Timer2Temp_ISig_ 1;
BA_ "GenSigStartValue" SG_ 2566356800 PHTimerTGWEvCmd_Timer2Temp_ISig_ 31;
BA_ "GenSigMaxLatency" SG_ 2566356800 PHTimerTGWEvCmd_Timer2Temp_ISig_ 150;
BA_ "SystemSignalLongSymbol" SG_ 2566356800 PHTimerTGWEvCmd_Timer2Temp_ISig_ "PHTimerTGWEvCmd_Timer2Temp_ISig_5";
BA_ "GenSigSendType" SG_ 2566356800 PHTimerTGWEvCmd_Timer1Duration_I 1;
BA_ "GenSigStartValue" SG_ 2566356800 PHTimerTGWEvCmd_Timer1Duration_I 127;
BA_ "GenSigMaxLatency" SG_ 2566356800 PHTimerTGWEvCmd_Timer1Duration_I 150;
BA_ "SystemSignalLongSymbol" SG_ 2566356800 PHTimerTGWEvCmd_Timer1Duration_I "PHTimerTGWEvCmd_Timer1Duration_ISig_5";
BA_ "GenSigSendType" SG_ 2566356800 PHTimerTGWEvCmd_Timer3Minutes_IS 1;
BA_ "GenSigStartValue" SG_ 2566356800 PHTimerTGWEvCmd_Timer3Minutes_IS 255;
BA_ "GenSigMaxLatency" SG_ 2566356800 PHTimerTGWEvCmd_Timer3Minutes_IS 150;
BA_ "SystemSignalLongSymbol" SG_ 2566356800 PHTimerTGWEvCmd_Timer3Minutes_IS "PHTimerTGWEvCmd_Timer3Minutes_ISig_5";
BA_ "GenSigSendType" SG_ 2566356800 PHTimerTGWEvCmd_Timer1StartDay_I 1;
BA_ "GenSigStartValue" SG_ 2566356800 PHTimerTGWEvCmd_Timer1StartDay_I 15;
BA_ "GenSigMaxLatency" SG_ 2566356800 PHTimerTGWEvCmd_Timer1StartDay_I 150;
BA_ "SystemSignalLongSymbol" SG_ 2566356800 PHTimerTGWEvCmd_Timer1StartDay_I "PHTimerTGWEvCmd_Timer1StartDay_ISig_5";
BA_ "GenSigSendType" SG_ 2566356800 PHTimerTGWEvCmd_Timer1Recur_ISig 1;
BA_ "GenSigStartValue" SG_ 2566356800 PHTimerTGWEvCmd_Timer1Recur_ISig 15;
BA_ "GenSigMaxLatency" SG_ 2566356800 PHTimerTGWEvCmd_Timer1Recur_ISig 150;
BA_ "SystemSignalLongSymbol" SG_ 2566356800 PHTimerTGWEvCmd_Timer1Recur_ISig "PHTimerTGWEvCmd_Timer1Recur_ISig_5";
BA_ "GenSigSendType" SG_ 2566356800 PHTimerTGWEvCmd_Timer2Recur_ISig 1;
BA_ "GenSigStartValue" SG_ 2566356800 PHTimerTGWEvCmd_Timer2Recur_ISig 15;
BA_ "GenSigMaxLatency" SG_ 2566356800 PHTimerTGWEvCmd_Timer2Recur_ISig 150;
BA_ "SystemSignalLongSymbol" SG_ 2566356800 PHTimerTGWEvCmd_Timer2Recur_ISig "PHTimerTGWEvCmd_Timer2Recur_ISig_5";
BA_ "GenSigSendType" SG_ 2566356800 PHTimerTGWEvCmd_PhTimer3_cmd_ISi 1;
BA_ "GenSigStartValue" SG_ 2566356800 PHTimerTGWEvCmd_PhTimer3_cmd_ISi 7;
BA_ "GenSigMaxLatency" SG_ 2566356800 PHTimerTGWEvCmd_PhTimer3_cmd_ISi 150;
BA_ "SystemSignalLongSymbol" SG_ 2566356800 PHTimerTGWEvCmd_PhTimer3_cmd_ISi "PHTimerTGWEvCmd_PhTimer3_cmd_ISig_5";
BA_ "GenSigSendType" SG_ 2566356800 PHTimerTGWEvCmd_Timer3Temp_ISig_ 1;
BA_ "GenSigStartValue" SG_ 2566356800 PHTimerTGWEvCmd_Timer3Temp_ISig_ 31;
BA_ "GenSigMaxLatency" SG_ 2566356800 PHTimerTGWEvCmd_Timer3Temp_ISig_ 150;
BA_ "SystemSignalLongSymbol" SG_ 2566356800 PHTimerTGWEvCmd_Timer3Temp_ISig_ "PHTimerTGWEvCmd_Timer3Temp_ISig_5";
BA_ "GenSigSendType" SG_ 2566356800 PHTimerTGWEvCmd_Timer3Hours_ISig 1;
BA_ "GenSigStartValue" SG_ 2566356800 PHTimerTGWEvCmd_Timer3Hours_ISig 255;
BA_ "GenSigMaxLatency" SG_ 2566356800 PHTimerTGWEvCmd_Timer3Hours_ISig 150;
BA_ "SystemSignalLongSymbol" SG_ 2566356800 PHTimerTGWEvCmd_Timer3Hours_ISig "PHTimerTGWEvCmd_Timer3Hours_ISig_5";
BA_ "GenSigCycleTime" SG_ 2516128064 Trailer1LiftAxles_LiftAxle2Id_IS 100;
BA_ "GenSigCycleTimeActive" SG_ 2516128064 Trailer1LiftAxles_LiftAxle2Id_IS 100;
BA_ "GenSigStartValue" SG_ 2516128064 Trailer1LiftAxles_LiftAxle2Id_IS 15;
BA_ "SystemSignalLongSymbol" SG_ 2516128064 Trailer1LiftAxles_LiftAxle2Id_IS "Trailer1LiftAxles_LiftAxle2Id_ISig_5";
BA_ "GenSigCycleTime" SG_ 2516128064 Trailer4LiftAxles_LiftAxle1Pos_I 100;
BA_ "GenSigCycleTimeActive" SG_ 2516128064 Trailer4LiftAxles_LiftAxle1Pos_I 100;
BA_ "GenSigStartValue" SG_ 2516128064 Trailer4LiftAxles_LiftAxle1Pos_I 3;
BA_ "SystemSignalLongSymbol" SG_ 2516128064 Trailer4LiftAxles_LiftAxle1Pos_I "Trailer4LiftAxles_LiftAxle1Pos_ISig_5";
BA_ "GenSigCycleTime" SG_ 2516128064 Trailer2LiftAxles_LiftAxle1Pos_I 100;
BA_ "GenSigCycleTimeActive" SG_ 2516128064 Trailer2LiftAxles_LiftAxle1Pos_I 100;
BA_ "GenSigStartValue" SG_ 2516128064 Trailer2LiftAxles_LiftAxle1Pos_I 3;
BA_ "SystemSignalLongSymbol" SG_ 2516128064 Trailer2LiftAxles_LiftAxle1Pos_I "Trailer2LiftAxles_LiftAxle1Pos_ISig_5";
BA_ "GenSigCycleTime" SG_ 2516128064 Trailer2LiftAxles_LiftAxle2Id_IS 100;
BA_ "GenSigCycleTimeActive" SG_ 2516128064 Trailer2LiftAxles_LiftAxle2Id_IS 100;
BA_ "GenSigStartValue" SG_ 2516128064 Trailer2LiftAxles_LiftAxle2Id_IS 15;
BA_ "SystemSignalLongSymbol" SG_ 2516128064 Trailer2LiftAxles_LiftAxle2Id_IS "Trailer2LiftAxles_LiftAxle2Id_ISig_5";
BA_ "GenSigCycleTime" SG_ 2516128064 Trailer2LiftAxles_LiftAxle2Pos_I 100;
BA_ "GenSigCycleTimeActive" SG_ 2516128064 Trailer2LiftAxles_LiftAxle2Pos_I 100;
BA_ "GenSigStartValue" SG_ 2516128064 Trailer2LiftAxles_LiftAxle2Pos_I 3;
BA_ "SystemSignalLongSymbol" SG_ 2516128064 Trailer2LiftAxles_LiftAxle2Pos_I "Trailer2LiftAxles_LiftAxle2Pos_ISig_5";
BA_ "GenSigCycleTime" SG_ 2516128064 Trailer4LiftAxles_LiftAxle2Pos_I 100;
BA_ "GenSigCycleTimeActive" SG_ 2516128064 Trailer4LiftAxles_LiftAxle2Pos_I 100;
BA_ "GenSigStartValue" SG_ 2516128064 Trailer4LiftAxles_LiftAxle2Pos_I 3;
BA_ "SystemSignalLongSymbol" SG_ 2516128064 Trailer4LiftAxles_LiftAxle2Pos_I "Trailer4LiftAxles_LiftAxle2Pos_ISig_5";
BA_ "GenSigCycleTime" SG_ 2516128064 Trailer5LiftAxles_LiftAxle2Id_IS 100;
BA_ "GenSigCycleTimeActive" SG_ 2516128064 Trailer5LiftAxles_LiftAxle2Id_IS 100;
BA_ "GenSigStartValue" SG_ 2516128064 Trailer5LiftAxles_LiftAxle2Id_IS 15;
BA_ "SystemSignalLongSymbol" SG_ 2516128064 Trailer5LiftAxles_LiftAxle2Id_IS "Trailer5LiftAxles_LiftAxle2Id_ISig_5";
BA_ "GenSigCycleTime" SG_ 2516128064 Trailer4LiftAxles_LiftAxle1Id_IS 100;
BA_ "GenSigCycleTimeActive" SG_ 2516128064 Trailer4LiftAxles_LiftAxle1Id_IS 100;
BA_ "GenSigStartValue" SG_ 2516128064 Trailer4LiftAxles_LiftAxle1Id_IS 15;
BA_ "SystemSignalLongSymbol" SG_ 2516128064 Trailer4LiftAxles_LiftAxle1Id_IS "Trailer4LiftAxles_LiftAxle1Id_ISig_5";
BA_ "GenSigCycleTime" SG_ 2516128064 Trailer3LiftAxles_LiftAxle2Id_IS 100;
BA_ "GenSigCycleTimeActive" SG_ 2516128064 Trailer3LiftAxles_LiftAxle2Id_IS 100;
BA_ "GenSigStartValue" SG_ 2516128064 Trailer3LiftAxles_LiftAxle2Id_IS 15;
BA_ "SystemSignalLongSymbol" SG_ 2516128064 Trailer3LiftAxles_LiftAxle2Id_IS "Trailer3LiftAxles_LiftAxle2Id_ISig_5";
BA_ "GenSigCycleTime" SG_ 2516128064 Trailer2LiftAxles_LiftAxle1Id_IS 100;
BA_ "GenSigCycleTimeActive" SG_ 2516128064 Trailer2LiftAxles_LiftAxle1Id_IS 100;
BA_ "GenSigStartValue" SG_ 2516128064 Trailer2LiftAxles_LiftAxle1Id_IS 15;
BA_ "SystemSignalLongSymbol" SG_ 2516128064 Trailer2LiftAxles_LiftAxle1Id_IS "Trailer2LiftAxles_LiftAxle1Id_ISig_5";
BA_ "GenSigCycleTime" SG_ 2516128064 Trailer5LiftAxles_LiftAxle1Pos_I 100;
BA_ "GenSigCycleTimeActive" SG_ 2516128064 Trailer5LiftAxles_LiftAxle1Pos_I 100;
BA_ "GenSigStartValue" SG_ 2516128064 Trailer5LiftAxles_LiftAxle1Pos_I 3;
BA_ "SystemSignalLongSymbol" SG_ 2516128064 Trailer5LiftAxles_LiftAxle1Pos_I "Trailer5LiftAxles_LiftAxle1Pos_ISig_5";
BA_ "GenSigCycleTime" SG_ 2516128064 Trailer1LiftAxles_LiftAxle1Id_IS 100;
BA_ "GenSigCycleTimeActive" SG_ 2516128064 Trailer1LiftAxles_LiftAxle1Id_IS 100;
BA_ "GenSigStartValue" SG_ 2516128064 Trailer1LiftAxles_LiftAxle1Id_IS 15;
BA_ "SystemSignalLongSymbol" SG_ 2516128064 Trailer1LiftAxles_LiftAxle1Id_IS "Trailer1LiftAxles_LiftAxle1Id_ISig_5";
BA_ "GenSigCycleTime" SG_ 2516128064 Trailer3LiftAxles_LiftAxle1Pos_I 100;
BA_ "GenSigCycleTimeActive" SG_ 2516128064 Trailer3LiftAxles_LiftAxle1Pos_I 100;
BA_ "GenSigStartValue" SG_ 2516128064 Trailer3LiftAxles_LiftAxle1Pos_I 3;
BA_ "SystemSignalLongSymbol" SG_ 2516128064 Trailer3LiftAxles_LiftAxle1Pos_I "Trailer3LiftAxles_LiftAxle1Pos_ISig_5";
BA_ "GenSigCycleTime" SG_ 2516128064 Trailer5LiftAxles_LiftAxle1Id_IS 100;
BA_ "GenSigCycleTimeActive" SG_ 2516128064 Trailer5LiftAxles_LiftAxle1Id_IS 100;
BA_ "GenSigStartValue" SG_ 2516128064 Trailer5LiftAxles_LiftAxle1Id_IS 15;
BA_ "SystemSignalLongSymbol" SG_ 2516128064 Trailer5LiftAxles_LiftAxle1Id_IS "Trailer5LiftAxles_LiftAxle1Id_ISig_5";
BA_ "GenSigCycleTime" SG_ 2516128064 Trailer1LiftAxles_LiftAxle2Pos_I 100;
BA_ "GenSigCycleTimeActive" SG_ 2516128064 Trailer1LiftAxles_LiftAxle2Pos_I 100;
BA_ "GenSigStartValue" SG_ 2516128064 Trailer1LiftAxles_LiftAxle2Pos_I 3;
BA_ "SystemSignalLongSymbol" SG_ 2516128064 Trailer1LiftAxles_LiftAxle2Pos_I "Trailer1LiftAxles_LiftAxle2Pos_ISig_5";
BA_ "GenSigCycleTime" SG_ 2516128064 Trailer5LiftAxles_LiftAxle2Pos_I 100;
BA_ "GenSigCycleTimeActive" SG_ 2516128064 Trailer5LiftAxles_LiftAxle2Pos_I 100;
BA_ "GenSigStartValue" SG_ 2516128064 Trailer5LiftAxles_LiftAxle2Pos_I 3;
BA_ "SystemSignalLongSymbol" SG_ 2516128064 Trailer5LiftAxles_LiftAxle2Pos_I "Trailer5LiftAxles_LiftAxle2Pos_ISig_5";
BA_ "GenSigCycleTime" SG_ 2516128064 Trailer3LiftAxles_LiftAxle1Id_IS 100;
BA_ "GenSigCycleTimeActive" SG_ 2516128064 Trailer3LiftAxles_LiftAxle1Id_IS 100;
BA_ "GenSigStartValue" SG_ 2516128064 Trailer3LiftAxles_LiftAxle1Id_IS 15;
BA_ "SystemSignalLongSymbol" SG_ 2516128064 Trailer3LiftAxles_LiftAxle1Id_IS "Trailer3LiftAxles_LiftAxle1Id_ISig_5";
BA_ "GenSigCycleTime" SG_ 2516128064 Trailer1LiftAxles_LiftAxle1Pos_I 100;
BA_ "GenSigCycleTimeActive" SG_ 2516128064 Trailer1LiftAxles_LiftAxle1Pos_I 100;
BA_ "GenSigStartValue" SG_ 2516128064 Trailer1LiftAxles_LiftAxle1Pos_I 3;
BA_ "SystemSignalLongSymbol" SG_ 2516128064 Trailer1LiftAxles_LiftAxle1Pos_I "Trailer1LiftAxles_LiftAxle1Pos_ISig_5";
BA_ "GenSigCycleTime" SG_ 2516128064 Trailer3LiftAxles_LiftAxle2Pos_I 100;
BA_ "GenSigCycleTimeActive" SG_ 2516128064 Trailer3LiftAxles_LiftAxle2Pos_I 100;
BA_ "GenSigStartValue" SG_ 2516128064 Trailer3LiftAxles_LiftAxle2Pos_I 3;
BA_ "SystemSignalLongSymbol" SG_ 2516128064 Trailer3LiftAxles_LiftAxle2Pos_I "Trailer3LiftAxles_LiftAxle2Pos_ISig_5";
BA_ "GenSigCycleTime" SG_ 2516128064 Trailer4LiftAxles_LiftAxle2Id_IS 100;
BA_ "GenSigCycleTimeActive" SG_ 2516128064 Trailer4LiftAxles_LiftAxle2Id_IS 100;
BA_ "GenSigStartValue" SG_ 2516128064 Trailer4LiftAxles_LiftAxle2Id_IS 15;
BA_ "SystemSignalLongSymbol" SG_ 2516128064 Trailer4LiftAxles_LiftAxle2Id_IS "Trailer4LiftAxles_LiftAxle2Id_ISig_5";
BA_ "GenSigCycleTime" SG_ 2499679296 CoolantPumpEngagementStatus_ISig 100;
BA_ "GenSigCycleTimeActive" SG_ 2499679296 CoolantPumpEngagementStatus_ISig 100;
BA_ "GenSigStartValue" SG_ 2499679296 CoolantPumpEngagementStatus_ISig 255;
BA_ "SystemSignalLongSymbol" SG_ 2499679296 CoolantPumpEngagementStatus_ISig "CoolantPumpEngagementStatus_ISig_5";
BA_ "GenSigCycleTime" SG_ 2499679296 PHTimerRqstAck_Hours_ISig_5 100;
BA_ "GenSigCycleTimeActive" SG_ 2499679296 PHTimerRqstAck_Hours_ISig_5 100;
BA_ "GenSigStartValue" SG_ 2499679296 PHTimerRqstAck_Hours_ISig_5 255;
BA_ "GenSigCycleTime" SG_ 2499679296 AudioMuteStat_ISig_5 100;
BA_ "GenSigCycleTimeActive" SG_ 2499679296 AudioMuteStat_ISig_5 100;
BA_ "GenSigStartValue" SG_ 2499679296 AudioMuteStat_ISig_5 7;
BA_ "SeToolAncestorID_SIGNAL" SG_ 2499679296 AudioMuteStat_ISig_5 "x0000001D043278F0";
BA_ "SeToolItemID_SIGNAL" SG_ 2499679296 AudioMuteStat_ISig_5 "x0000001D043278F0";
BA_ "SeToolName_SIGNAL" SG_ 2499679296 AudioMuteStat_ISig_5 "AudioMuteStat";
BA_ "SeToolVersion_SIGNAL" SG_ 2499679296 AudioMuteStat_ISig_5 "1";
BA_ "GenSigCycleTime" SG_ 2499679296 LoadDistributionSelected_ISig_5 100;
BA_ "GenSigCycleTimeActive" SG_ 2499679296 LoadDistributionSelected_ISig_5 100;
BA_ "GenSigStartValue" SG_ 2499679296 LoadDistributionSelected_ISig_5 15;
BA_ "GenSigCycleTime" SG_ 2499679296 PHTimerRqstAck_DayOfWeekRq_ISig_ 100;
BA_ "GenSigCycleTimeActive" SG_ 2499679296 PHTimerRqstAck_DayOfWeekRq_ISig_ 100;
BA_ "GenSigStartValue" SG_ 2499679296 PHTimerRqstAck_DayOfWeekRq_ISig_ 15;
BA_ "SystemSignalLongSymbol" SG_ 2499679296 PHTimerRqstAck_DayOfWeekRq_ISig_ "PHTimerRqstAck_DayOfWeekRq_ISig_5";
BA_ "GenSigCycleTime" SG_ 2499679296 PHTimerRqstAck_Minutes_ISig_5 100;
BA_ "GenSigCycleTimeActive" SG_ 2499679296 PHTimerRqstAck_Minutes_ISig_5 100;
BA_ "GenSigStartValue" SG_ 2499679296 PHTimerRqstAck_Minutes_ISig_5 255;
BA_ "GenSigCycleTime" SG_ 2499679296 LiftAxle1PositionStatus_ISig_5 100;
BA_ "GenSigCycleTimeActive" SG_ 2499679296 LiftAxle1PositionStatus_ISig_5 100;
BA_ "GenSigStartValue" SG_ 2499679296 LiftAxle1PositionStatus_ISig_5 7;
BA_ "SeToolAncestorID_SIGNAL" SG_ 2499679296 LiftAxle1PositionStatus_ISig_5 "x0000001D04131A08";
BA_ "SeToolItemID_SIGNAL" SG_ 2499679296 LiftAxle1PositionStatus_ISig_5 "x0000001D0423C412";
BA_ "SeToolName_SIGNAL" SG_ 2499679296 LiftAxle1PositionStatus_ISig_5 "LiftAxle1PositionStatus";
BA_ "SeToolVersion_SIGNAL" SG_ 2499679296 LiftAxle1PositionStatus_ISig_5 "2";
BA_ "GenSigCycleTime" SG_ 2499679296 PHTimerRqstAck_CurrentOp_ISig_5 100;
BA_ "GenSigCycleTimeActive" SG_ 2499679296 PHTimerRqstAck_CurrentOp_ISig_5 100;
BA_ "GenSigStartValue" SG_ 2499679296 PHTimerRqstAck_CurrentOp_ISig_5 3;
BA_ "GenSigCycleTime" SG_ 2499679296 LiftAxle2PositionStatus_ISig_5 100;
BA_ "GenSigCycleTimeActive" SG_ 2499679296 LiftAxle2PositionStatus_ISig_5 100;
BA_ "GenSigStartValue" SG_ 2499679296 LiftAxle2PositionStatus_ISig_5 7;
BA_ "SeToolAncestorID_SIGNAL" SG_ 2499679296 LiftAxle2PositionStatus_ISig_5 "x0000001D04131A0A";
BA_ "SeToolItemID_SIGNAL" SG_ 2499679296 LiftAxle2PositionStatus_ISig_5 "x0000001D04295880";
BA_ "SeToolName_SIGNAL" SG_ 2499679296 LiftAxle2PositionStatus_ISig_5 "LiftAxle2PositionStatus";
BA_ "SeToolVersion_SIGNAL" SG_ 2499679296 LiftAxle2PositionStatus_ISig_5 "3";
BA_ "GenSigCycleTime" SG_ 2499679296 EngineCoolingFanSpeed_ISig_5 100;
BA_ "GenSigCycleTimeActive" SG_ 2499679296 EngineCoolingFanSpeed_ISig_5 100;
BA_ "GenSigStartValue" SG_ 2499679296 EngineCoolingFanSpeed_ISig_5 65535;
BA_ "GenSigCycleTime" SG_ 2499679296 ParkingBrake_stat_ISig_5 100;
BA_ "GenSigCycleTimeActive" SG_ 2499679296 ParkingBrake_stat_ISig_5 100;
BA_ "GenSigStartValue" SG_ 2499679296 ParkingBrake_stat_ISig_5 3;
BA_ "GenSigCycleTime" SG_ 2549186373 AudioSourceStatus2_ISig_5 100;
BA_ "GenSigCycleTimeActive" SG_ 2549186373 AudioSourceStatus2_ISig_5 100;
BA_ "GenSigStartValue" SG_ 2549186373 AudioSourceStatus2_ISig_5 15;
BA_ "GenSigCycleTime" SG_ 2549186373 Trailer1NumberOfFrontAxles_ISig_ 100;
BA_ "GenSigCycleTimeActive" SG_ 2549186373 Trailer1NumberOfFrontAxles_ISig_ 100;
BA_ "GenSigStartValue" SG_ 2549186373 Trailer1NumberOfFrontAxles_ISig_ 15;
BA_ "SystemSignalLongSymbol" SG_ 2549186373 Trailer1NumberOfFrontAxles_ISig_ "Trailer1NumberOfFrontAxles_ISig_5";
BA_ "GenSigCycleTime" SG_ 2549186373 Trailer5NumberOfFrontAxles_ISig_ 100;
BA_ "GenSigCycleTimeActive" SG_ 2549186373 Trailer5NumberOfFrontAxles_ISig_ 100;
BA_ "GenSigStartValue" SG_ 2549186373 Trailer5NumberOfFrontAxles_ISig_ 15;
BA_ "SystemSignalLongSymbol" SG_ 2549186373 Trailer5NumberOfFrontAxles_ISig_ "Trailer5NumberOfFrontAxles_ISig_5";
BA_ "GenSigCycleTime" SG_ 2549186373 RemoteParkingClimateRqst_ISig_5 100;
BA_ "GenSigCycleTimeActive" SG_ 2549186373 RemoteParkingClimateRqst_ISig_5 100;
BA_ "GenSigStartValue" SG_ 2549186373 RemoteParkingClimateRqst_ISig_5 7;
BA_ "GenSigCycleTime" SG_ 2549186373 Trailer2NumberOfFrontAxles_ISig_ 100;
BA_ "GenSigCycleTimeActive" SG_ 2549186373 Trailer2NumberOfFrontAxles_ISig_ 100;
BA_ "GenSigStartValue" SG_ 2549186373 Trailer2NumberOfFrontAxles_ISig_ 15;
BA_ "SystemSignalLongSymbol" SG_ 2549186373 Trailer2NumberOfFrontAxles_ISig_ "Trailer2NumberOfFrontAxles_ISig_5";
BA_ "GenSigCycleTime" SG_ 2549186373 AudioSourceUsbAvailable_ISig_5 100;
BA_ "GenSigCycleTimeActive" SG_ 2549186373 AudioSourceUsbAvailable_ISig_5 100;
BA_ "GenSigStartValue" SG_ 2549186373 AudioSourceUsbAvailable_ISig_5 3;
BA_ "GenSigCycleTime" SG_ 2549186373 AudioSourceBtStreamAvailable_ISi 100;
BA_ "GenSigCycleTimeActive" SG_ 2549186373 AudioSourceBtStreamAvailable_ISi 100;
BA_ "GenSigStartValue" SG_ 2549186373 AudioSourceBtStreamAvailable_ISi 3;
BA_ "SystemSignalLongSymbol" SG_ 2549186373 AudioSourceBtStreamAvailable_ISi "AudioSourceBtStreamAvailable_ISig_5";
BA_ "GenSigCycleTime" SG_ 2549186373 AudioSourceIpodAvailable_ISig_5 100;
BA_ "GenSigCycleTimeActive" SG_ 2549186373 AudioSourceIpodAvailable_ISig_5 100;
BA_ "GenSigStartValue" SG_ 2549186373 AudioSourceIpodAvailable_ISig_5 3;
BA_ "GenSigCycleTime" SG_ 2549186373 Trailer3NumberOfFrontAxles_ISig_ 100;
BA_ "GenSigCycleTimeActive" SG_ 2549186373 Trailer3NumberOfFrontAxles_ISig_ 100;
BA_ "GenSigStartValue" SG_ 2549186373 Trailer3NumberOfFrontAxles_ISig_ 15;
BA_ "SystemSignalLongSymbol" SG_ 2549186373 Trailer3NumberOfFrontAxles_ISig_ "Trailer3NumberOfFrontAxles_ISig_5";
BA_ "GenSigCycleTime" SG_ 2549186373 Trailer4NumberOfFrontAxles_ISig_ 100;
BA_ "GenSigCycleTimeActive" SG_ 2549186373 Trailer4NumberOfFrontAxles_ISig_ 100;
BA_ "GenSigStartValue" SG_ 2549186373 Trailer4NumberOfFrontAxles_ISig_ 15;
BA_ "SystemSignalLongSymbol" SG_ 2549186373 Trailer4NumberOfFrontAxles_ISig_ "Trailer4NumberOfFrontAxles_ISig_5";
BA_ "GenSigCycleTime" SG_ 2549186373 AudioSourceCdAvailable_ISig_5 100;
BA_ "GenSigCycleTimeActive" SG_ 2549186373 AudioSourceCdAvailable_ISig_5 100;
BA_ "GenSigStartValue" SG_ 2549186373 AudioSourceCdAvailable_ISig_5 3;
BA_ "GenSigCycleTime" SG_ 2566879231 VehFrontAxle1CalibratedLoad_ISig 100;
BA_ "GenSigCycleTimeActive" SG_ 2566879231 VehFrontAxle1CalibratedLoad_ISig 100;
BA_ "GenSigStartValue" SG_ 2566879231 VehFrontAxle1CalibratedLoad_ISig 65535;
BA_ "GenSigMaxLatency" SG_ 2566879231 VehFrontAxle1CalibratedLoad_ISig 590;
BA_ "SystemSignalLongSymbol" SG_ 2566879231 VehFrontAxle1CalibratedLoad_ISig "VehFrontAxle1CalibratedLoad_ISig_5";
BA_ "GenSigCycleTime" SG_ 2566879231 VehicleCalibratedCargoLoad_ISig_ 100;
BA_ "GenSigCycleTimeActive" SG_ 2566879231 VehicleCalibratedCargoLoad_ISig_ 100;
BA_ "GenSigStartValue" SG_ 2566879231 VehicleCalibratedCargoLoad_ISig_ 65535;
BA_ "GenSigMaxLatency" SG_ 2566879231 VehicleCalibratedCargoLoad_ISig_ 590;
BA_ "SystemSignalLongSymbol" SG_ 2566879231 VehicleCalibratedCargoLoad_ISig_ "VehicleCalibratedCargoLoad_ISig_5";
BA_ "GenSigCycleTime" SG_ 2566879231 VehFrontAxle2CalibratedLoad_ISig 100;
BA_ "GenSigCycleTimeActive" SG_ 2566879231 VehFrontAxle2CalibratedLoad_ISig 100;
BA_ "GenSigStartValue" SG_ 2566879231 VehFrontAxle2CalibratedLoad_ISig 65535;
BA_ "GenSigMaxLatency" SG_ 2566879231 VehFrontAxle2CalibratedLoad_ISig 590;
BA_ "SystemSignalLongSymbol" SG_ 2566879231 VehFrontAxle2CalibratedLoad_ISig "VehFrontAxle2CalibratedLoad_ISig_5";
BA_ "GenSigCycleTime" SG_ 2566879231 VehicleCalibratedLoad_ISig_5 100;
BA_ "GenSigCycleTimeActive" SG_ 2566879231 VehicleCalibratedLoad_ISig_5 100;
BA_ "GenSigStartValue" SG_ 2566879231 VehicleCalibratedLoad_ISig_5 65535;
BA_ "GenSigMaxLatency" SG_ 2566879231 VehicleCalibratedLoad_ISig_5 590;
BA_ "GenSigSendType" SG_ 2566864832 CIOM_Cab_20S_FCS 7;
BA_ "GenSigSendType" SG_ 2566864831 DisplayText_stat_ISig_5 1;
BA_ "GenSigCycleTime" SG_ 2566864831 DisplayText_stat_ISig_5 100;
BA_ "GenSigCycleTimeActive" SG_ 2566864831 DisplayText_stat_ISig_5 100;
BA_ "GenSigMaxLatency" SG_ 2566864831 DisplayText_stat_ISig_5 26;
BA_ "GenSigCycleTime" SG_ 2566809599 VehRearAxle3CalibratedLoad_ISig_ 100;
BA_ "GenSigCycleTimeActive" SG_ 2566809599 VehRearAxle3CalibratedLoad_ISig_ 100;
BA_ "GenSigStartValue" SG_ 2566809599 VehRearAxle3CalibratedLoad_ISig_ 65535;
BA_ "GenSigMaxLatency" SG_ 2566809599 VehRearAxle3CalibratedLoad_ISig_ 580;
BA_ "SystemSignalLongSymbol" SG_ 2566809599 VehRearAxle3CalibratedLoad_ISig_ "VehRearAxle3CalibratedLoad_ISig_5";
BA_ "GenSigCycleTime" SG_ 2566809599 Trailer5Type_ISig_5 100;
BA_ "GenSigCycleTimeActive" SG_ 2566809599 Trailer5Type_ISig_5 100;
BA_ "GenSigStartValue" SG_ 2566809599 Trailer5Type_ISig_5 7;
BA_ "GenSigMaxLatency" SG_ 2566809599 Trailer5Type_ISig_5 550;
BA_ "GenSigCycleTime" SG_ 2566809599 VehRearAxle2CalibratedLoad_ISig_ 100;
BA_ "GenSigCycleTimeActive" SG_ 2566809599 VehRearAxle2CalibratedLoad_ISig_ 100;
BA_ "GenSigStartValue" SG_ 2566809599 VehRearAxle2CalibratedLoad_ISig_ 65535;
BA_ "GenSigMaxLatency" SG_ 2566809599 VehRearAxle2CalibratedLoad_ISig_ 580;
BA_ "SystemSignalLongSymbol" SG_ 2566809599 VehRearAxle2CalibratedLoad_ISig_ "VehRearAxle2CalibratedLoad_ISig_5";
BA_ "GenSigCycleTime" SG_ 2566809599 VehRearAxle1CalibratedLoad_ISig_ 100;
BA_ "GenSigCycleTimeActive" SG_ 2566809599 VehRearAxle1CalibratedLoad_ISig_ 100;
BA_ "GenSigStartValue" SG_ 2566809599 VehRearAxle1CalibratedLoad_ISig_ 65535;
BA_ "GenSigMaxLatency" SG_ 2566809599 VehRearAxle1CalibratedLoad_ISig_ 580;
BA_ "SystemSignalLongSymbol" SG_ 2566809599 VehRearAxle1CalibratedLoad_ISig_ "VehRearAxle1CalibratedLoad_ISig_5";
BA_ "GenSigCycleTime" SG_ 2566809599 Trailer2Type_ISig_5 100;
BA_ "GenSigCycleTimeActive" SG_ 2566809599 Trailer2Type_ISig_5 100;
BA_ "GenSigStartValue" SG_ 2566809599 Trailer2Type_ISig_5 7;
BA_ "GenSigMaxLatency" SG_ 2566809599 Trailer2Type_ISig_5 520;
BA_ "GenSigCycleTime" SG_ 2566809599 Trailer4Type_ISig_5 100;
BA_ "GenSigCycleTimeActive" SG_ 2566809599 Trailer4Type_ISig_5 100;
BA_ "GenSigStartValue" SG_ 2566809599 Trailer4Type_ISig_5 7;
BA_ "GenSigMaxLatency" SG_ 2566809599 Trailer4Type_ISig_5 540;
BA_ "GenSigCycleTime" SG_ 2566809599 Trailer1Type_ISig_5 100;
BA_ "GenSigCycleTimeActive" SG_ 2566809599 Trailer1Type_ISig_5 100;
BA_ "GenSigStartValue" SG_ 2566809599 Trailer1Type_ISig_5 7;
BA_ "GenSigMaxLatency" SG_ 2566809599 Trailer1Type_ISig_5 510;
BA_ "GenSigCycleTime" SG_ 2566809599 Trailer3Type_ISig_5 100;
BA_ "GenSigCycleTimeActive" SG_ 2566809599 Trailer3Type_ISig_5 100;
BA_ "GenSigStartValue" SG_ 2566809599 Trailer3Type_ISig_5 7;
BA_ "GenSigMaxLatency" SG_ 2566809599 Trailer3Type_ISig_5 530;
BA_ "GenSigCycleTime" SG_ 2566670335 Trailer5CalibratedTotalLoad_ISig 100;
BA_ "GenSigCycleTimeActive" SG_ 2566670335 Trailer5CalibratedTotalLoad_ISig 100;
BA_ "GenSigStartValue" SG_ 2566670335 Trailer5CalibratedTotalLoad_ISig 65535;
BA_ "GenSigMaxLatency" SG_ 2566670335 Trailer5CalibratedTotalLoad_ISig 550;
BA_ "SystemSignalLongSymbol" SG_ 2566670335 Trailer5CalibratedTotalLoad_ISig "Trailer5CalibratedTotalLoad_ISig_5";
BA_ "GenSigCycleTime" SG_ 2566670335 Trailer5CalibratedCargoLoad_ISig 100;
BA_ "GenSigCycleTimeActive" SG_ 2566670335 Trailer5CalibratedCargoLoad_ISig 100;
BA_ "GenSigStartValue" SG_ 2566670335 Trailer5CalibratedCargoLoad_ISig 65535;
BA_ "GenSigMaxLatency" SG_ 2566670335 Trailer5CalibratedCargoLoad_ISig 550;
BA_ "SystemSignalLongSymbol" SG_ 2566670335 Trailer5CalibratedCargoLoad_ISig "Trailer5CalibratedCargoLoad_ISig_5";
BA_ "GenSigCycleTime" SG_ 2566670335 Trailer5NumberOfAxles_ISig_5 100;
BA_ "GenSigCycleTimeActive" SG_ 2566670335 Trailer5NumberOfAxles_ISig_5 100;
BA_ "GenSigStartValue" SG_ 2566670335 Trailer5NumberOfAxles_ISig_5 255;
BA_ "GenSigMaxLatency" SG_ 2566670335 Trailer5NumberOfAxles_ISig_5 550;
BA_ "GenSigCycleTime" SG_ 2566670335 Trailer5CalAxleLoad_AxleLoad_ISi 100;
BA_ "GenSigCycleTimeActive" SG_ 2566670335 Trailer5CalAxleLoad_AxleLoad_ISi 100;
BA_ "GenSigStartValue" SG_ 2566670335 Trailer5CalAxleLoad_AxleLoad_ISi 65535;
BA_ "GenSigMaxLatency" SG_ 2566670335 Trailer5CalAxleLoad_AxleLoad_ISi 550;
BA_ "SystemSignalLongSymbol" SG_ 2566670335 Trailer5CalAxleLoad_AxleLoad_ISi "Trailer5CalAxleLoad_AxleLoad_ISig_5";
BA_ "GenSigCycleTime" SG_ 2566670335 Trailer5CalAxleLoad_AxleId_ISig_ 100;
BA_ "GenSigCycleTimeActive" SG_ 2566670335 Trailer5CalAxleLoad_AxleId_ISig_ 100;
BA_ "GenSigMaxLatency" SG_ 2566670335 Trailer5CalAxleLoad_AxleId_ISig_ 550;
BA_ "SystemSignalLongSymbol" SG_ 2566670335 Trailer5CalAxleLoad_AxleId_ISig_ "Trailer5CalAxleLoad_AxleId_ISig_5";
BA_ "GenSigCycleTime" SG_ 2566531071 Trailer4NumberOfAxles_ISig_5 100;
BA_ "GenSigCycleTimeActive" SG_ 2566531071 Trailer4NumberOfAxles_ISig_5 100;
BA_ "GenSigStartValue" SG_ 2566531071 Trailer4NumberOfAxles_ISig_5 255;
BA_ "GenSigMaxLatency" SG_ 2566531071 Trailer4NumberOfAxles_ISig_5 540;
BA_ "GenSigCycleTime" SG_ 2566531071 Trailer4CalAxleLoad_AxleId_ISig_ 100;
BA_ "GenSigCycleTimeActive" SG_ 2566531071 Trailer4CalAxleLoad_AxleId_ISig_ 100;
BA_ "GenSigMaxLatency" SG_ 2566531071 Trailer4CalAxleLoad_AxleId_ISig_ 540;
BA_ "SystemSignalLongSymbol" SG_ 2566531071 Trailer4CalAxleLoad_AxleId_ISig_ "Trailer4CalAxleLoad_AxleId_ISig_5";
BA_ "GenSigCycleTime" SG_ 2566531071 Trailer4CalAxleLoad_AxleLoad_ISi 100;
BA_ "GenSigCycleTimeActive" SG_ 2566531071 Trailer4CalAxleLoad_AxleLoad_ISi 100;
BA_ "GenSigStartValue" SG_ 2566531071 Trailer4CalAxleLoad_AxleLoad_ISi 65535;
BA_ "GenSigMaxLatency" SG_ 2566531071 Trailer4CalAxleLoad_AxleLoad_ISi 540;
BA_ "SystemSignalLongSymbol" SG_ 2566531071 Trailer4CalAxleLoad_AxleLoad_ISi "Trailer4CalAxleLoad_AxleLoad_ISig_5";
BA_ "GenSigCycleTime" SG_ 2566531071 Trailer4CalibratedCargoLoad_ISig 100;
BA_ "GenSigCycleTimeActive" SG_ 2566531071 Trailer4CalibratedCargoLoad_ISig 100;
BA_ "GenSigStartValue" SG_ 2566531071 Trailer4CalibratedCargoLoad_ISig 65535;
BA_ "GenSigMaxLatency" SG_ 2566531071 Trailer4CalibratedCargoLoad_ISig 540;
BA_ "SystemSignalLongSymbol" SG_ 2566531071 Trailer4CalibratedCargoLoad_ISig "Trailer4CalibratedCargoLoad_ISig_5";
BA_ "GenSigCycleTime" SG_ 2566531071 Trailer4CalibratedTotalLoad_ISig 100;
BA_ "GenSigCycleTimeActive" SG_ 2566531071 Trailer4CalibratedTotalLoad_ISig 100;
BA_ "GenSigStartValue" SG_ 2566531071 Trailer4CalibratedTotalLoad_ISig 65535;
BA_ "GenSigMaxLatency" SG_ 2566531071 Trailer4CalibratedTotalLoad_ISig 540;
BA_ "SystemSignalLongSymbol" SG_ 2566531071 Trailer4CalibratedTotalLoad_ISig "Trailer4CalibratedTotalLoad_ISig_5";
BA_ "GenSigCycleTime" SG_ 2566391807 Trailer3CalibratedCargoLoad_ISig 100;
BA_ "GenSigCycleTimeActive" SG_ 2566391807 Trailer3CalibratedCargoLoad_ISig 100;
BA_ "GenSigStartValue" SG_ 2566391807 Trailer3CalibratedCargoLoad_ISig 65535;
BA_ "GenSigMaxLatency" SG_ 2566391807 Trailer3CalibratedCargoLoad_ISig 530;
BA_ "SystemSignalLongSymbol" SG_ 2566391807 Trailer3CalibratedCargoLoad_ISig "Trailer3CalibratedCargoLoad_ISig_5";
BA_ "GenSigCycleTime" SG_ 2566391807 Trailer3NumberOfAxles_ISig_5 100;
BA_ "GenSigCycleTimeActive" SG_ 2566391807 Trailer3NumberOfAxles_ISig_5 100;
BA_ "GenSigStartValue" SG_ 2566391807 Trailer3NumberOfAxles_ISig_5 255;
BA_ "GenSigMaxLatency" SG_ 2566391807 Trailer3NumberOfAxles_ISig_5 530;
BA_ "GenSigCycleTime" SG_ 2566391807 Trailer3CalibratedTotalLoad_ISig 100;
BA_ "GenSigCycleTimeActive" SG_ 2566391807 Trailer3CalibratedTotalLoad_ISig 100;
BA_ "GenSigStartValue" SG_ 2566391807 Trailer3CalibratedTotalLoad_ISig 65535;
BA_ "GenSigMaxLatency" SG_ 2566391807 Trailer3CalibratedTotalLoad_ISig 530;
BA_ "SystemSignalLongSymbol" SG_ 2566391807 Trailer3CalibratedTotalLoad_ISig "Trailer3CalibratedTotalLoad_ISig_5";
BA_ "GenSigCycleTime" SG_ 2566391807 Trailer3CalAxleLoad_AxleLoad_ISi 100;
BA_ "GenSigCycleTimeActive" SG_ 2566391807 Trailer3CalAxleLoad_AxleLoad_ISi 100;
BA_ "GenSigStartValue" SG_ 2566391807 Trailer3CalAxleLoad_AxleLoad_ISi 65535;
BA_ "GenSigMaxLatency" SG_ 2566391807 Trailer3CalAxleLoad_AxleLoad_ISi 530;
BA_ "SystemSignalLongSymbol" SG_ 2566391807 Trailer3CalAxleLoad_AxleLoad_ISi "Trailer3CalAxleLoad_AxleLoad_ISig_5";
BA_ "GenSigCycleTime" SG_ 2566391807 Trailer3CalAxleLoad_AxleId_ISig_ 100;
BA_ "GenSigCycleTimeActive" SG_ 2566391807 Trailer3CalAxleLoad_AxleId_ISig_ 100;
BA_ "GenSigMaxLatency" SG_ 2566391807 Trailer3CalAxleLoad_AxleId_ISig_ 530;
BA_ "SystemSignalLongSymbol" SG_ 2566391807 Trailer3CalAxleLoad_AxleId_ISig_ "Trailer3CalAxleLoad_AxleId_ISig_5";
BA_ "GenSigCycleTime" SG_ 2566252543 Trailer2NumberOfAxles_ISig_5 100;
BA_ "GenSigCycleTimeActive" SG_ 2566252543 Trailer2NumberOfAxles_ISig_5 100;
BA_ "GenSigStartValue" SG_ 2566252543 Trailer2NumberOfAxles_ISig_5 255;
BA_ "GenSigMaxLatency" SG_ 2566252543 Trailer2NumberOfAxles_ISig_5 520;
BA_ "GenSigCycleTime" SG_ 2566252543 Trailer2CalAxleLoad_AxleId_ISig_ 100;
BA_ "GenSigCycleTimeActive" SG_ 2566252543 Trailer2CalAxleLoad_AxleId_ISig_ 100;
BA_ "GenSigMaxLatency" SG_ 2566252543 Trailer2CalAxleLoad_AxleId_ISig_ 520;
BA_ "SystemSignalLongSymbol" SG_ 2566252543 Trailer2CalAxleLoad_AxleId_ISig_ "Trailer2CalAxleLoad_AxleId_ISig_5";
BA_ "GenSigCycleTime" SG_ 2566252543 Trailer2CalibratedCargoLoad_ISig 100;
BA_ "GenSigCycleTimeActive" SG_ 2566252543 Trailer2CalibratedCargoLoad_ISig 100;
BA_ "GenSigStartValue" SG_ 2566252543 Trailer2CalibratedCargoLoad_ISig 65535;
BA_ "GenSigMaxLatency" SG_ 2566252543 Trailer2CalibratedCargoLoad_ISig 520;
BA_ "SystemSignalLongSymbol" SG_ 2566252543 Trailer2CalibratedCargoLoad_ISig "Trailer2CalibratedCargoLoad_ISig_5";
BA_ "GenSigCycleTime" SG_ 2566252543 Trailer2CalAxleLoad_AxleLoad_ISi 100;
BA_ "GenSigCycleTimeActive" SG_ 2566252543 Trailer2CalAxleLoad_AxleLoad_ISi 100;
BA_ "GenSigStartValue" SG_ 2566252543 Trailer2CalAxleLoad_AxleLoad_ISi 65535;
BA_ "GenSigMaxLatency" SG_ 2566252543 Trailer2CalAxleLoad_AxleLoad_ISi 520;
BA_ "SystemSignalLongSymbol" SG_ 2566252543 Trailer2CalAxleLoad_AxleLoad_ISi "Trailer2CalAxleLoad_AxleLoad_ISig_5";
BA_ "GenSigCycleTime" SG_ 2566252543 Trailer2CalibratedTotalLoad_ISig 100;
BA_ "GenSigCycleTimeActive" SG_ 2566252543 Trailer2CalibratedTotalLoad_ISig 100;
BA_ "GenSigStartValue" SG_ 2566252543 Trailer2CalibratedTotalLoad_ISig 65535;
BA_ "GenSigMaxLatency" SG_ 2566252543 Trailer2CalibratedTotalLoad_ISig 520;
BA_ "SystemSignalLongSymbol" SG_ 2566252543 Trailer2CalibratedTotalLoad_ISig "Trailer2CalibratedTotalLoad_ISig_5";
BA_ "GenSigCycleTime" SG_ 2566113279 Trailer1CalibratedTotalLoad_ISig 100;
BA_ "GenSigCycleTimeActive" SG_ 2566113279 Trailer1CalibratedTotalLoad_ISig 100;
BA_ "GenSigStartValue" SG_ 2566113279 Trailer1CalibratedTotalLoad_ISig 65535;
BA_ "GenSigMaxLatency" SG_ 2566113279 Trailer1CalibratedTotalLoad_ISig 510;
BA_ "SystemSignalLongSymbol" SG_ 2566113279 Trailer1CalibratedTotalLoad_ISig "Trailer1CalibratedTotalLoad_ISig_5";
BA_ "GenSigCycleTime" SG_ 2566113279 Trailer1NumberOfAxles_ISig_5 100;
BA_ "GenSigCycleTimeActive" SG_ 2566113279 Trailer1NumberOfAxles_ISig_5 100;
BA_ "GenSigStartValue" SG_ 2566113279 Trailer1NumberOfAxles_ISig_5 255;
BA_ "GenSigMaxLatency" SG_ 2566113279 Trailer1NumberOfAxles_ISig_5 510;
BA_ "GenSigCycleTime" SG_ 2566113279 Trailer1CalAxleLoad_AxleId_ISig_ 100;
BA_ "GenSigCycleTimeActive" SG_ 2566113279 Trailer1CalAxleLoad_AxleId_ISig_ 100;
BA_ "GenSigMaxLatency" SG_ 2566113279 Trailer1CalAxleLoad_AxleId_ISig_ 510;
BA_ "SystemSignalLongSymbol" SG_ 2566113279 Trailer1CalAxleLoad_AxleId_ISig_ "Trailer1CalAxleLoad_AxleId_ISig_5";
BA_ "GenSigCycleTime" SG_ 2566113279 Trailer1CalibratedCargoLoad_ISig 100;
BA_ "GenSigCycleTimeActive" SG_ 2566113279 Trailer1CalibratedCargoLoad_ISig 100;
BA_ "GenSigStartValue" SG_ 2566113279 Trailer1CalibratedCargoLoad_ISig 65535;
BA_ "GenSigMaxLatency" SG_ 2566113279 Trailer1CalibratedCargoLoad_ISig 510;
BA_ "SystemSignalLongSymbol" SG_ 2566113279 Trailer1CalibratedCargoLoad_ISig "Trailer1CalibratedCargoLoad_ISig_5";
BA_ "GenSigCycleTime" SG_ 2566113279 Trailer1CalAxleLoad_AxleLoad_ISi 100;
BA_ "GenSigCycleTimeActive" SG_ 2566113279 Trailer1CalAxleLoad_AxleLoad_ISi 100;
BA_ "GenSigStartValue" SG_ 2566113279 Trailer1CalAxleLoad_AxleLoad_ISi 65535;
BA_ "GenSigMaxLatency" SG_ 2566113279 Trailer1CalAxleLoad_AxleLoad_ISi 510;
BA_ "SystemSignalLongSymbol" SG_ 2566113279 Trailer1CalAxleLoad_AxleLoad_ISi "Trailer1CalAxleLoad_AxleLoad_ISig_5";
BA_ "GenSigSendType" SG_ 2565974016 CIOM_Cab_13S_FCS 7;
BA_ "GenSigSendType" SG_ 2565974015 FdEquipmentFreeText_ISig_5 1;
BA_ "GenSigCycleTime" SG_ 2565974015 FdEquipmentFreeText_ISig_5 100;
BA_ "GenSigCycleTimeActive" SG_ 2565974015 FdEquipmentFreeText_ISig_5 100;
BA_ "GenSigMaxLatency" SG_ 2565974015 FdEquipmentFreeText_ISig_5 200;
BA_ "SeToolAncestorID_SIGNAL" SG_ 2565974015 FdEquipmentFreeText_ISig_5 "x0000001D04171318";
BA_ "SeToolItemID_SIGNAL" SG_ 2565974015 FdEquipmentFreeText_ISig_5 "x0000001D04171318";
BA_ "SeToolName_SIGNAL" SG_ 2565974015 FdEquipmentFreeText_ISig_5 "FdEquipmentFreeText";
BA_ "SeToolVersion_SIGNAL" SG_ 2565974015 FdEquipmentFreeText_ISig_5 "1";
BA_ "GenSigCycleTime" SG_ 2565904383 AlarmClockAlarms_stat_SetMin_ISi 100;
BA_ "GenSigCycleTimeActive" SG_ 2565904383 AlarmClockAlarms_stat_SetMin_ISi 100;
BA_ "GenSigStartValue" SG_ 2565904383 AlarmClockAlarms_stat_SetMin_ISi 63;
BA_ "GenSigMaxLatency" SG_ 2565904383 AlarmClockAlarms_stat_SetMin_ISi 140;
BA_ "SystemSignalLongSymbol" SG_ 2565904383 AlarmClockAlarms_stat_SetMin_ISi "AlarmClockAlarms_stat_SetMin_ISig_5";
BA_ "GenSigCycleTime" SG_ 2565904383 ESCReqESC_CtrlTrimValue_ISig_5 100;
BA_ "GenSigCycleTimeActive" SG_ 2565904383 ESCReqESC_CtrlTrimValue_ISig_5 100;
BA_ "GenSigStartValue" SG_ 2565904383 ESCReqESC_CtrlTrimValue_ISig_5 255;
BA_ "GenSigMaxLatency" SG_ 2565904383 ESCReqESC_CtrlTrimValue_ISig_5 140;
BA_ "SeToolAncestorID_SIGNAL" SG_ 2565904383 ESCReqESC_CtrlTrimValue_ISig_5 "x0000001D042A7114";
BA_ "SeToolItemID_SIGNAL" SG_ 2565904383 ESCReqESC_CtrlTrimValue_ISig_5 "x0000001D042A7114";
BA_ "SeToolName_SIGNAL" SG_ 2565904383 ESCReqESC_CtrlTrimValue_ISig_5 "CtrlTrimValue";
BA_ "SeToolOwnerSigGroupID_SIGNAL" SG_ 2565904383 ESCReqESC_CtrlTrimValue_ISig_5 "x0000001D043D5DD2";
BA_ "SeToolOwnerSigGroup_SIGNAL" SG_ 2565904383 ESCReqESC_CtrlTrimValue_ISig_5 "ESCReqESC";
BA_ "SeToolVersion_SIGNAL" SG_ 2565904383 ESCReqESC_CtrlTrimValue_ISig_5 "1";
BA_ "GenSigCycleTime" SG_ 2565904383 AlarmClockAlarms_stat_Mode_ISig_ 100;
BA_ "GenSigCycleTimeActive" SG_ 2565904383 AlarmClockAlarms_stat_Mode_ISig_ 100;
BA_ "GenSigMaxLatency" SG_ 2565904383 AlarmClockAlarms_stat_Mode_ISig_ 140;
BA_ "SystemSignalLongSymbol" SG_ 2565904383 AlarmClockAlarms_stat_Mode_ISig_ "AlarmClockAlarms_stat_Mode_ISig_5";
BA_ "GenSigCycleTime" SG_ 2565904383 AlarmClockAlarms_stat_SetHr_ISig 100;
BA_ "GenSigCycleTimeActive" SG_ 2565904383 AlarmClockAlarms_stat_SetHr_ISig 100;
BA_ "GenSigStartValue" SG_ 2565904383 AlarmClockAlarms_stat_SetHr_ISig 31;
BA_ "GenSigMaxLatency" SG_ 2565904383 AlarmClockAlarms_stat_SetHr_ISig 140;
BA_ "SystemSignalLongSymbol" SG_ 2565904383 AlarmClockAlarms_stat_SetHr_ISig "AlarmClockAlarms_stat_SetHr_ISig_5";
BA_ "GenSigCycleTime" SG_ 2565904383 AlarmClockAlarms_stat_ID_ISig_5 100;
BA_ "GenSigCycleTimeActive" SG_ 2565904383 AlarmClockAlarms_stat_ID_ISig_5 100;
BA_ "GenSigStartValue" SG_ 2565904383 AlarmClockAlarms_stat_ID_ISig_5 127;
BA_ "GenSigMaxLatency" SG_ 2565904383 AlarmClockAlarms_stat_ID_ISig_5 140;
BA_ "GenSigCycleTime" SG_ 2565904383 AlarmClockNotification_Stat_ISig 100;
BA_ "GenSigCycleTimeActive" SG_ 2565904383 AlarmClockNotification_Stat_ISig 100;
BA_ "GenSigMaxLatency" SG_ 2565904383 AlarmClockNotification_Stat_ISig 140;
BA_ "SystemSignalLongSymbol" SG_ 2565904383 AlarmClockNotification_Stat_ISig "AlarmClockNotification_Stat_ISig_5";
BA_ "GenSigCycleTime" SG_ 2565904383 AlarmClockNotification_Type_ISig 100;
BA_ "GenSigCycleTimeActive" SG_ 2565904383 AlarmClockNotification_Type_ISig 100;
BA_ "GenSigStartValue" SG_ 2565904383 AlarmClockNotification_Type_ISig 7;
BA_ "GenSigMaxLatency" SG_ 2565904383 AlarmClockNotification_Type_ISig 140;
BA_ "SystemSignalLongSymbol" SG_ 2565904383 AlarmClockNotification_Type_ISig "AlarmClockNotification_Type_ISig_5";
BA_ "GenSigCycleTime" SG_ 2565904383 AlarmClockAlarms_stat_DaySet_ISi 100;
BA_ "GenSigCycleTimeActive" SG_ 2565904383 AlarmClockAlarms_stat_DaySet_ISi 100;
BA_ "GenSigMaxLatency" SG_ 2565904383 AlarmClockAlarms_stat_DaySet_ISi 140;
BA_ "SystemSignalLongSymbol" SG_ 2565904383 AlarmClockAlarms_stat_DaySet_ISi "AlarmClockAlarms_stat_DaySet_ISig_5";
BA_ "GenSigCycleTime" SG_ 2565904383 ESCReqESC_CtrlTrimReq_ISig_5 100;
BA_ "GenSigCycleTimeActive" SG_ 2565904383 ESCReqESC_CtrlTrimReq_ISig_5 100;
BA_ "GenSigStartValue" SG_ 2565904383 ESCReqESC_CtrlTrimReq_ISig_5 7;
BA_ "GenSigMaxLatency" SG_ 2565904383 ESCReqESC_CtrlTrimReq_ISig_5 140;
BA_ "SeToolAncestorID_SIGNAL" SG_ 2565904383 ESCReqESC_CtrlTrimReq_ISig_5 "x0000001D042A710B";
BA_ "SeToolItemID_SIGNAL" SG_ 2565904383 ESCReqESC_CtrlTrimReq_ISig_5 "x0000001D042A710B";
BA_ "SeToolName_SIGNAL" SG_ 2565904383 ESCReqESC_CtrlTrimReq_ISig_5 "CtrlTrimReq";
BA_ "SeToolOwnerSigGroupID_SIGNAL" SG_ 2565904383 ESCReqESC_CtrlTrimReq_ISig_5 "x0000001D043D5DD2";
BA_ "SeToolOwnerSigGroup_SIGNAL" SG_ 2565904383 ESCReqESC_CtrlTrimReq_ISig_5 "ESCReqESC";
BA_ "SeToolVersion_SIGNAL" SG_ 2565904383 ESCReqESC_CtrlTrimReq_ISig_5 "1";
BA_ "GenSigCycleTime" SG_ 2565904383 AlarmClockAlarms_stat_Stat_ISig_ 100;
BA_ "GenSigCycleTimeActive" SG_ 2565904383 AlarmClockAlarms_stat_Stat_ISig_ 100;
BA_ "GenSigMaxLatency" SG_ 2565904383 AlarmClockAlarms_stat_Stat_ISig_ 140;
BA_ "SystemSignalLongSymbol" SG_ 2565904383 AlarmClockAlarms_stat_Stat_ISig_ "AlarmClockAlarms_stat_Stat_ISig_5";
BA_ "GenSigCycleTime" SG_ 2565904383 ESCReqESC_CtrlTrimMode_ISig_5 100;
BA_ "GenSigCycleTimeActive" SG_ 2565904383 ESCReqESC_CtrlTrimMode_ISig_5 100;
BA_ "GenSigStartValue" SG_ 2565904383 ESCReqESC_CtrlTrimMode_ISig_5 15;
BA_ "GenSigMaxLatency" SG_ 2565904383 ESCReqESC_CtrlTrimMode_ISig_5 140;
BA_ "SeToolAncestorID_SIGNAL" SG_ 2565904383 ESCReqESC_CtrlTrimMode_ISig_5 "x0000001D042A710F";
BA_ "SeToolItemID_SIGNAL" SG_ 2565904383 ESCReqESC_CtrlTrimMode_ISig_5 "x0000001D042A710F";
BA_ "SeToolName_SIGNAL" SG_ 2565904383 ESCReqESC_CtrlTrimMode_ISig_5 "CtrlTrimMode";
BA_ "SeToolOwnerSigGroupID_SIGNAL" SG_ 2565904383 ESCReqESC_CtrlTrimMode_ISig_5 "x0000001D043D5DD2";
BA_ "SeToolOwnerSigGroup_SIGNAL" SG_ 2565904383 ESCReqESC_CtrlTrimMode_ISig_5 "ESCReqESC";
BA_ "SeToolVersion_SIGNAL" SG_ 2565904383 ESCReqESC_CtrlTrimMode_ISig_5 "1";
BA_ "GenSigCycleTime" SG_ 2565904383 ESCReqESC_CtrlTrimStat_ISig_5 100;
BA_ "GenSigCycleTimeActive" SG_ 2565904383 ESCReqESC_CtrlTrimStat_ISig_5 100;
BA_ "GenSigStartValue" SG_ 2565904383 ESCReqESC_CtrlTrimStat_ISig_5 7;
BA_ "GenSigMaxLatency" SG_ 2565904383 ESCReqESC_CtrlTrimStat_ISig_5 140;
BA_ "SeToolAncestorID_SIGNAL" SG_ 2565904383 ESCReqESC_CtrlTrimStat_ISig_5 "x0000001D042A710D";
BA_ "SeToolItemID_SIGNAL" SG_ 2565904383 ESCReqESC_CtrlTrimStat_ISig_5 "x0000001D042A710D";
BA_ "SeToolName_SIGNAL" SG_ 2565904383 ESCReqESC_CtrlTrimStat_ISig_5 "CtrlTrimStat";
BA_ "SeToolOwnerSigGroupID_SIGNAL" SG_ 2565904383 ESCReqESC_CtrlTrimStat_ISig_5 "x0000001D043D5DD2";
BA_ "SeToolOwnerSigGroup_SIGNAL" SG_ 2565904383 ESCReqESC_CtrlTrimStat_ISig_5 "ESCReqESC";
BA_ "SeToolVersion_SIGNAL" SG_ 2565904383 ESCReqESC_CtrlTrimStat_ISig_5 "1";
BA_ "GenSigCycleTime" SG_ 2565904383 AlarmClockAlarms_stat_Type_ISig_ 100;
BA_ "GenSigCycleTimeActive" SG_ 2565904383 AlarmClockAlarms_stat_Type_ISig_ 100;
BA_ "GenSigStartValue" SG_ 2565904383 AlarmClockAlarms_stat_Type_ISig_ 7;
BA_ "GenSigMaxLatency" SG_ 2565904383 AlarmClockAlarms_stat_Type_ISig_ 140;
BA_ "SystemSignalLongSymbol" SG_ 2565904383 AlarmClockAlarms_stat_Type_ISig_ "AlarmClockAlarms_stat_Type_ISig_5";
BA_ "GenSigCycleTime" SG_ 2565904383 AlarmClockNotification_ID_ISig_5 100;
BA_ "GenSigCycleTimeActive" SG_ 2565904383 AlarmClockNotification_ID_ISig_5 100;
BA_ "GenSigStartValue" SG_ 2565904383 AlarmClockNotification_ID_ISig_5 127;
BA_ "GenSigSendType" SG_ 2565834752 CIOM_Cab_11S_FCS 7;
BA_ "GenSigSendType" SG_ 2565834751 ECUVIN_stat 1;
BA_ "GenSigCycleTime" SG_ 2565834751 ECUVIN_stat 100;
BA_ "GenSigCycleTimeActive" SG_ 2565834751 ECUVIN_stat 100;
BA_ "GenSigMaxLatency" SG_ 2565834751 ECUVIN_stat 110;
BA_ "GenSigCycleTime" SG_ 2499755967 FdEquipmentStatus2_ISig_5 100;
BA_ "GenSigCycleTimeActive" SG_ 2499755967 FdEquipmentStatus2_ISig_5 100;
BA_ "GenSigStartValue" SG_ 2499755967 FdEquipmentStatus2_ISig_5 3;
BA_ "GenSigMaxLatency" SG_ 2499755967 FdEquipmentStatus2_ISig_5 60;
BA_ "SeToolAncestorID_SIGNAL" SG_ 2499755967 FdEquipmentStatus2_ISig_5 "x0000001D041709FC";
BA_ "SeToolItemID_SIGNAL" SG_ 2499755967 FdEquipmentStatus2_ISig_5 "x0000001D041709FC";
BA_ "SeToolName_SIGNAL" SG_ 2499755967 FdEquipmentStatus2_ISig_5 "FdEquipmentStatus2";
BA_ "SeToolVersion_SIGNAL" SG_ 2499755967 FdEquipmentStatus2_ISig_5 "1";
BA_ "GenSigCycleTime" SG_ 2499755967 RideHeightStatus_ISig_5 100;
BA_ "GenSigCycleTimeActive" SG_ 2499755967 RideHeightStatus_ISig_5 100;
BA_ "GenSigStartValue" SG_ 2499755967 RideHeightStatus_ISig_5 15;
BA_ "GenSigMaxLatency" SG_ 2499755967 RideHeightStatus_ISig_5 60;
BA_ "SeToolAncestorID_SIGNAL" SG_ 2499755967 RideHeightStatus_ISig_5 "x0000001D041304DF";
BA_ "SeToolItemID_SIGNAL" SG_ 2499755967 RideHeightStatus_ISig_5 "x0000001D0442415B";
BA_ "SeToolName_SIGNAL" SG_ 2499755967 RideHeightStatus_ISig_5 "RideHeightStatus";
BA_ "SeToolVersion_SIGNAL" SG_ 2499755967 RideHeightStatus_ISig_5 "3";
BA_ "GenSigCycleTime" SG_ 2499755967 FdEquipmentStatus4_ISig_5 100;
BA_ "GenSigCycleTimeActive" SG_ 2499755967 FdEquipmentStatus4_ISig_5 100;
BA_ "GenSigStartValue" SG_ 2499755967 FdEquipmentStatus4_ISig_5 3;
BA_ "GenSigMaxLatency" SG_ 2499755967 FdEquipmentStatus4_ISig_5 60;
BA_ "SeToolAncestorID_SIGNAL" SG_ 2499755967 FdEquipmentStatus4_ISig_5 "x0000001D04170A00";
BA_ "SeToolItemID_SIGNAL" SG_ 2499755967 FdEquipmentStatus4_ISig_5 "x0000001D04170A00";
BA_ "SeToolName_SIGNAL" SG_ 2499755967 FdEquipmentStatus4_ISig_5 "FdEquipmentStatus4";
BA_ "SeToolVersion_SIGNAL" SG_ 2499755967 FdEquipmentStatus4_ISig_5 "1";
BA_ "GenSigCycleTime" SG_ 2499755967 RideHeightOutsideTargetRange_ISi 100;
BA_ "GenSigCycleTimeActive" SG_ 2499755967 RideHeightOutsideTargetRange_ISi 100;
BA_ "GenSigStartValue" SG_ 2499755967 RideHeightOutsideTargetRange_ISi 7;
BA_ "GenSigMaxLatency" SG_ 2499755967 RideHeightOutsideTargetRange_ISi 60;
BA_ "SeToolAncestorID_SIGNAL" SG_ 2499755967 RideHeightOutsideTargetRange_ISi "x0000001D041F15D9";
BA_ "SeToolItemID_SIGNAL" SG_ 2499755967 RideHeightOutsideTargetRange_ISi "x0000001D041F15D9";
BA_ "SeToolName_SIGNAL" SG_ 2499755967 RideHeightOutsideTargetRange_ISi "RideHeightOutsideTargetRange";
BA_ "SeToolVersion_SIGNAL" SG_ 2499755967 RideHeightOutsideTargetRange_ISi "1";
BA_ "SystemSignalLongSymbol" SG_ 2499755967 RideHeightOutsideTargetRange_ISi "RideHeightOutsideTargetRange_ISig_5";
BA_ "GenSigCycleTime" SG_ 2499755967 FdEquipmentStatus1_ISig_5 100;
BA_ "GenSigCycleTimeActive" SG_ 2499755967 FdEquipmentStatus1_ISig_5 100;
BA_ "GenSigStartValue" SG_ 2499755967 FdEquipmentStatus1_ISig_5 3;
BA_ "GenSigMaxLatency" SG_ 2499755967 FdEquipmentStatus1_ISig_5 60;
BA_ "SeToolAncestorID_SIGNAL" SG_ 2499755967 FdEquipmentStatus1_ISig_5 "x0000001D041709FA";
BA_ "SeToolItemID_SIGNAL" SG_ 2499755967 FdEquipmentStatus1_ISig_5 "x0000001D041709FA";
BA_ "SeToolName_SIGNAL" SG_ 2499755967 FdEquipmentStatus1_ISig_5 "FdEquipmentStatus1";
BA_ "SeToolVersion_SIGNAL" SG_ 2499755967 FdEquipmentStatus1_ISig_5 "1";
BA_ "GenSigCycleTime" SG_ 2499755967 FdEquipmentStatus5_ISig_5 100;
BA_ "GenSigCycleTimeActive" SG_ 2499755967 FdEquipmentStatus5_ISig_5 100;
BA_ "GenSigStartValue" SG_ 2499755967 FdEquipmentStatus5_ISig_5 3;
BA_ "GenSigMaxLatency" SG_ 2499755967 FdEquipmentStatus5_ISig_5 60;
BA_ "SeToolAncestorID_SIGNAL" SG_ 2499755967 FdEquipmentStatus5_ISig_5 "x0000001D04170A02";
BA_ "SeToolItemID_SIGNAL" SG_ 2499755967 FdEquipmentStatus5_ISig_5 "x0000001D04170A02";
BA_ "SeToolName_SIGNAL" SG_ 2499755967 FdEquipmentStatus5_ISig_5 "FdEquipmentStatus5";
BA_ "SeToolVersion_SIGNAL" SG_ 2499755967 FdEquipmentStatus5_ISig_5 "1";
BA_ "GenSigCycleTime" SG_ 2499755967 RideHeightFunctionStatus_ISig_5 100;
BA_ "GenSigCycleTimeActive" SG_ 2499755967 RideHeightFunctionStatus_ISig_5 100;
BA_ "GenSigStartValue" SG_ 2499755967 RideHeightFunctionStatus_ISig_5 15;
BA_ "GenSigMaxLatency" SG_ 2499755967 RideHeightFunctionStatus_ISig_5 60;
BA_ "SeToolAncestorID_SIGNAL" SG_ 2499755967 RideHeightFunctionStatus_ISig_5 "x0000001D042186C7";
BA_ "SeToolItemID_SIGNAL" SG_ 2499755967 RideHeightFunctionStatus_ISig_5 "x0000001D043FB877";
BA_ "SeToolName_SIGNAL" SG_ 2499755967 RideHeightFunctionStatus_ISig_5 "RideHeightFunctionStatus";
BA_ "SeToolVersion_SIGNAL" SG_ 2499755967 RideHeightFunctionStatus_ISig_5 "2";
BA_ "GenSigCycleTime" SG_ 2499755967 FdEquipmentStatus3_ISig_5 100;
BA_ "GenSigCycleTimeActive" SG_ 2499755967 FdEquipmentStatus3_ISig_5 100;
BA_ "GenSigStartValue" SG_ 2499755967 FdEquipmentStatus3_ISig_5 3;
BA_ "GenSigMaxLatency" SG_ 2499755967 FdEquipmentStatus3_ISig_5 60;
BA_ "SeToolAncestorID_SIGNAL" SG_ 2499755967 FdEquipmentStatus3_ISig_5 "x0000001D041709FE";
BA_ "SeToolItemID_SIGNAL" SG_ 2499755967 FdEquipmentStatus3_ISig_5 "x0000001D041709FE";
BA_ "SeToolName_SIGNAL" SG_ 2499755967 FdEquipmentStatus3_ISig_5 "FdEquipmentStatus3";
BA_ "SeToolVersion_SIGNAL" SG_ 2499755967 FdEquipmentStatus3_ISig_5 "1";
BA_ "GenSigCycleTime" SG_ 2499755967 FdEquipmentValue2_ISig_5 100;
BA_ "GenSigCycleTimeActive" SG_ 2499755967 FdEquipmentValue2_ISig_5 100;
BA_ "GenSigStartValue" SG_ 2499755967 FdEquipmentValue2_ISig_5 255;
BA_ "GenSigMaxLatency" SG_ 2499755967 FdEquipmentValue2_ISig_5 60;
BA_ "SeToolAncestorID_SIGNAL" SG_ 2499755967 FdEquipmentValue2_ISig_5 "x0000001D04171241";
BA_ "SeToolItemID_SIGNAL" SG_ 2499755967 FdEquipmentValue2_ISig_5 "x0000001D04171241";
BA_ "SeToolName_SIGNAL" SG_ 2499755967 FdEquipmentValue2_ISig_5 "FdEquipmentValue2";
BA_ "SeToolVersion_SIGNAL" SG_ 2499755967 FdEquipmentValue2_ISig_5 "1";
BA_ "GenSigCycleTime" SG_ 2499755967 FrontEndPositionStatus_ISig_5 100;
BA_ "GenSigCycleTimeActive" SG_ 2499755967 FrontEndPositionStatus_ISig_5 100;
BA_ "GenSigStartValue" SG_ 2499755967 FrontEndPositionStatus_ISig_5 7;
BA_ "GenSigMaxLatency" SG_ 2499755967 FrontEndPositionStatus_ISig_5 60;
BA_ "GenSigCycleTime" SG_ 2499755967 RollEndPositionStatus_ISig_5 100;
BA_ "GenSigCycleTimeActive" SG_ 2499755967 RollEndPositionStatus_ISig_5 100;
BA_ "GenSigStartValue" SG_ 2499755967 RollEndPositionStatus_ISig_5 7;
BA_ "GenSigMaxLatency" SG_ 2499755967 RollEndPositionStatus_ISig_5 60;
BA_ "GenSigCycleTime" SG_ 2499755967 RampLevelStatus_ISig_5 100;
BA_ "GenSigCycleTimeActive" SG_ 2499755967 RampLevelStatus_ISig_5 100;
BA_ "GenSigStartValue" SG_ 2499755967 RampLevelStatus_ISig_5 15;
BA_ "GenSigMaxLatency" SG_ 2499755967 RampLevelStatus_ISig_5 60;
BA_ "GenSigCycleTime" SG_ 2499755967 FdEquipmentValue1_ISig_5 100;
BA_ "GenSigCycleTimeActive" SG_ 2499755967 FdEquipmentValue1_ISig_5 100;
BA_ "GenSigStartValue" SG_ 2499755967 FdEquipmentValue1_ISig_5 255;
BA_ "GenSigMaxLatency" SG_ 2499755967 FdEquipmentValue1_ISig_5 60;
BA_ "SeToolAncestorID_SIGNAL" SG_ 2499755967 FdEquipmentValue1_ISig_5 "x0000001D0417123F";
BA_ "SeToolItemID_SIGNAL" SG_ 2499755967 FdEquipmentValue1_ISig_5 "x0000001D0417123F";
BA_ "SeToolName_SIGNAL" SG_ 2499755967 FdEquipmentValue1_ISig_5 "FdEquipmentValue1";
BA_ "SeToolVersion_SIGNAL" SG_ 2499755967 FdEquipmentValue1_ISig_5 "1";
BA_ "GenSigCycleTime" SG_ 2499755967 RampHeightOutsideTargetRange_ISi 100;
BA_ "GenSigCycleTimeActive" SG_ 2499755967 RampHeightOutsideTargetRange_ISi 100;
BA_ "GenSigStartValue" SG_ 2499755967 RampHeightOutsideTargetRange_ISi 7;
BA_ "GenSigMaxLatency" SG_ 2499755967 RampHeightOutsideTargetRange_ISi 60;
BA_ "SystemSignalLongSymbol" SG_ 2499755967 RampHeightOutsideTargetRange_ISi "RampHeightOutsideTargetRange_ISig_5";
BA_ "GenSigCycleTime" SG_ 2499755967 FdEquipmentValue3_ISig_5 100;
BA_ "GenSigCycleTimeActive" SG_ 2499755967 FdEquipmentValue3_ISig_5 100;
BA_ "GenSigStartValue" SG_ 2499755967 FdEquipmentValue3_ISig_5 255;
BA_ "GenSigMaxLatency" SG_ 2499755967 FdEquipmentValue3_ISig_5 60;
BA_ "SeToolAncestorID_SIGNAL" SG_ 2499755967 FdEquipmentValue3_ISig_5 "x0000001D04171243";
BA_ "SeToolItemID_SIGNAL" SG_ 2499755967 FdEquipmentValue3_ISig_5 "x0000001D043A9096";
BA_ "SeToolName_SIGNAL" SG_ 2499755967 FdEquipmentValue3_ISig_5 "FdEquipmentValue3";
BA_ "SeToolVersion_SIGNAL" SG_ 2499755967 FdEquipmentValue3_ISig_5 "2";
BA_ "GenSigCycleTime" SG_ 2499755967 RearEndPositionStatus_ISig_5 100;
BA_ "GenSigCycleTimeActive" SG_ 2499755967 RearEndPositionStatus_ISig_5 100;
BA_ "GenSigStartValue" SG_ 2499755967 RearEndPositionStatus_ISig_5 7;
BA_ "GenSigMaxLatency" SG_ 2499755967 RearEndPositionStatus_ISig_5 60;
BA_ "GenSigCycleTime" SG_ 2432687168 Pto1Status_ISig_5 100;
BA_ "GenSigCycleTimeActive" SG_ 2432687168 Pto1Status_ISig_5 100;
BA_ "GenSigStartValue" SG_ 2432687168 Pto1Status_ISig_5 3;
BA_ "SeToolAncestorID_SIGNAL" SG_ 2432687168 Pto1Status_ISig_5 "x0000001D041534A3";
BA_ "SeToolItemID_SIGNAL" SG_ 2432687168 Pto1Status_ISig_5 "x0000001D04320FF9";
BA_ "SeToolName_SIGNAL" SG_ 2432687168 Pto1Status_ISig_5 "Pto1Status";
BA_ "SeToolVersion_SIGNAL" SG_ 2432687168 Pto1Status_ISig_5 "3";
BA_ "GenSigCycleTime" SG_ 2432687168 BodyOrCabWorkingLightFdbk_stat_I 100;
BA_ "GenSigCycleTimeActive" SG_ 2432687168 BodyOrCabWorkingLightFdbk_stat_I 100;
BA_ "GenSigStartValue" SG_ 2432687168 BodyOrCabWorkingLightFdbk_stat_I 3;
BA_ "SeToolAncestorID_SIGNAL" SG_ 2432687168 BodyOrCabWorkingLightFdbk_stat_I "x0000001D041B0A46";
BA_ "SeToolItemID_SIGNAL" SG_ 2432687168 BodyOrCabWorkingLightFdbk_stat_I "x0000001D041B0A46";
BA_ "SeToolName_SIGNAL" SG_ 2432687168 BodyOrCabWorkingLightFdbk_stat_I "CabBody/CabWorkingLightFeedback_Status";
BA_ "SeToolVersion_SIGNAL" SG_ 2432687168 BodyOrCabWorkingLightFdbk_stat_I "1";
BA_ "SystemSignalLongSymbol" SG_ 2432687168 BodyOrCabWorkingLightFdbk_stat_I "BodyOrCabWorkingLightFdbk_stat_ISig_5";
BA_ "GenSigCycleTime" SG_ 2432687168 ElectricalLoadReduction_rqst_ISi 100;
BA_ "GenSigCycleTimeActive" SG_ 2432687168 ElectricalLoadReduction_rqst_ISi 100;
BA_ "GenSigStartValue" SG_ 2432687168 ElectricalLoadReduction_rqst_ISi 7;
BA_ "NeedsUpdateBit" SG_ 2432687168 ElectricalLoadReduction_rqst_ISi 1;
BA_ "SystemSignalLongSymbol" SG_ 2432687168 ElectricalLoadReduction_rqst_ISi "ElectricalLoadReduction_rqst_ISig_5";
BA_ "GenSigCycleTime" SG_ 2432687168 CabWrknLightChassisFdbk_stat_ISi 100;
BA_ "GenSigCycleTimeActive" SG_ 2432687168 CabWrknLightChassisFdbk_stat_ISi 100;
BA_ "GenSigStartValue" SG_ 2432687168 CabWrknLightChassisFdbk_stat_ISi 3;
BA_ "SeToolAncestorID_SIGNAL" SG_ 2432687168 CabWrknLightChassisFdbk_stat_ISi "x0000001D041B0A49";
BA_ "SeToolItemID_SIGNAL" SG_ 2432687168 CabWrknLightChassisFdbk_stat_ISi "x0000001D041B0A49";
BA_ "SeToolName_SIGNAL" SG_ 2432687168 CabWrknLightChassisFdbk_stat_ISi "CabWorkingLightChassisFeedback_Status";
BA_ "SeToolVersion_SIGNAL" SG_ 2432687168 CabWrknLightChassisFdbk_stat_ISi "1";
BA_ "SystemSignalLongSymbol" SG_ 2432687168 CabWrknLightChassisFdbk_stat_ISi "CabWrknLightChassisFdbk_stat_ISig_5";
BA_ "GenSigCycleTime" SG_ 2432687168 ExtraBBTailLiftStatus_ISig_5 100;
BA_ "GenSigCycleTimeActive" SG_ 2432687168 ExtraBBTailLiftStatus_ISig_5 100;
BA_ "GenSigStartValue" SG_ 2432687168 ExtraBBTailLiftStatus_ISig_5 3;
BA_ "GenSigCycleTime" SG_ 2432687168 TotalVehicleDistanceHighRes_ISig 100;
BA_ "GenSigCycleTimeActive" SG_ 2432687168 TotalVehicleDistanceHighRes_ISig 100;
BA_ "GenSigStartValue" SG_ 2432687168 TotalVehicleDistanceHighRes_ISig 4294967295;
BA_ "GenSigMaxLatency" SG_ 2432687168 TotalVehicleDistanceHighRes_ISig 26;
BA_ "SeToolAncestorID_SIGNAL" SG_ 2432687168 TotalVehicleDistanceHighRes_ISig "x0000001D04109E2B";
BA_ "SeToolItemID_SIGNAL" SG_ 2432687168 TotalVehicleDistanceHighRes_ISig "x0000001D04109E2B";
BA_ "SeToolName_SIGNAL" SG_ 2432687168 TotalVehicleDistanceHighRes_ISig "HighResolutionTotalVehicleDistance";
BA_ "SeToolVersion_SIGNAL" SG_ 2432687168 TotalVehicleDistanceHighRes_ISig "1";
BA_ "SystemSignalLongSymbol" SG_ 2432687168 TotalVehicleDistanceHighRes_ISig "TotalVehicleDistanceHighRes_ISig_5";
BA_ "GenSigSendType" SG_ 2432687168 ElectricalLoadReduction_rqst_UB_ 7;
BA_ "SystemSignalLongSymbol" SG_ 2432687168 ElectricalLoadReduction_rqst_UB_ "ElectricalLoadReduction_rqst_UB_ISig_5";
BA_ "GenSigCycleTime" SG_ 2432687168 ExtraBBCraneStatus_ISig_5 100;
BA_ "GenSigCycleTimeActive" SG_ 2432687168 ExtraBBCraneStatus_ISig_5 100;
BA_ "GenSigStartValue" SG_ 2432687168 ExtraBBCraneStatus_ISig_5 7;
BA_ "GenSigCycleTime" SG_ 2432687168 Pto3Status_ISig_5 100;
BA_ "GenSigCycleTimeActive" SG_ 2432687168 Pto3Status_ISig_5 100;
BA_ "GenSigStartValue" SG_ 2432687168 Pto3Status_ISig_5 3;
BA_ "SeToolAncestorID_SIGNAL" SG_ 2432687168 Pto3Status_ISig_5 "x0000001D041534A7";
BA_ "SeToolItemID_SIGNAL" SG_ 2432687168 Pto3Status_ISig_5 "x0000001D04321034";
BA_ "SeToolName_SIGNAL" SG_ 2432687168 Pto3Status_ISig_5 "Pto3Status";
BA_ "SeToolVersion_SIGNAL" SG_ 2432687168 Pto3Status_ISig_5 "3";
BA_ "GenSigCycleTime" SG_ 2432687168 CabExtraSideWrknLightFdbk_stat_I 100;
BA_ "GenSigCycleTimeActive" SG_ 2432687168 CabExtraSideWrknLightFdbk_stat_I 100;
BA_ "GenSigStartValue" SG_ 2432687168 CabExtraSideWrknLightFdbk_stat_I 3;
BA_ "SeToolAncestorID_SIGNAL" SG_ 2432687168 CabExtraSideWrknLightFdbk_stat_I "x0000001D041B0A4B";
BA_ "SeToolItemID_SIGNAL" SG_ 2432687168 CabExtraSideWrknLightFdbk_stat_I "x0000001D041B0A4B";
BA_ "SeToolName_SIGNAL" SG_ 2432687168 CabExtraSideWrknLightFdbk_stat_I "CabExtraSideWorkingFeedback_Status";
BA_ "SeToolVersion_SIGNAL" SG_ 2432687168 CabExtraSideWrknLightFdbk_stat_I "1";
BA_ "SystemSignalLongSymbol" SG_ 2432687168 CabExtraSideWrknLightFdbk_stat_I "CabExtraSideWrknLightFdbk_stat_ISig_5";
BA_ "GenSigCycleTime" SG_ 2432687168 Pto2Status_ISig_5 100;
BA_ "GenSigCycleTimeActive" SG_ 2432687168 Pto2Status_ISig_5 100;
BA_ "GenSigStartValue" SG_ 2432687168 Pto2Status_ISig_5 3;
BA_ "SeToolAncestorID_SIGNAL" SG_ 2432687168 Pto2Status_ISig_5 "x0000001D041534A5";
BA_ "SeToolItemID_SIGNAL" SG_ 2432687168 Pto2Status_ISig_5 "x0000001D04321002";
BA_ "SeToolName_SIGNAL" SG_ 2432687168 Pto2Status_ISig_5 "Pto2Status";
BA_ "SeToolVersion_SIGNAL" SG_ 2432687168 Pto2Status_ISig_5 "3";
BA_ "GenSigCycleTime" SG_ 2432687168 CabBeaconLightFeedback_Status_IS 100;
BA_ "GenSigCycleTimeActive" SG_ 2432687168 CabBeaconLightFeedback_Status_IS 100;
BA_ "GenSigStartValue" SG_ 2432687168 CabBeaconLightFeedback_Status_IS 3;
BA_ "SeToolAncestorID_SIGNAL" SG_ 2432687168 CabBeaconLightFeedback_Status_IS "x0000001D041B0A09";
BA_ "SeToolItemID_SIGNAL" SG_ 2432687168 CabBeaconLightFeedback_Status_IS "x0000001D041B0A09";
BA_ "SeToolName_SIGNAL" SG_ 2432687168 CabBeaconLightFeedback_Status_IS "CabBeaconLightFeedback_Status";
BA_ "SeToolVersion_SIGNAL" SG_ 2432687168 CabBeaconLightFeedback_Status_IS "1";
BA_ "SystemSignalLongSymbol" SG_ 2432687168 CabBeaconLightFeedback_Status_IS "CabBeaconLightFeedback_Status_ISig_5";
BA_ "GenSigCycleTime" SG_ 2432687168 AudioSourceStatus_ISig_5 100;
BA_ "GenSigCycleTimeActive" SG_ 2432687168 AudioSourceStatus_ISig_5 100;
BA_ "GenSigStartValue" SG_ 2432687168 AudioSourceStatus_ISig_5 7;
BA_ "GenSigMaxLatency" SG_ 2432687168 AudioSourceStatus_ISig_5 26;
BA_ "GenSigCycleTime" SG_ 2432687168 Pto4Status_ISig_5 100;
BA_ "GenSigCycleTimeActive" SG_ 2432687168 Pto4Status_ISig_5 100;
BA_ "GenSigStartValue" SG_ 2432687168 Pto4Status_ISig_5 3;
BA_ "SeToolAncestorID_SIGNAL" SG_ 2432687168 Pto4Status_ISig_5 "x0000001D041534AC";
BA_ "SeToolItemID_SIGNAL" SG_ 2432687168 Pto4Status_ISig_5 "x0000001D04321056";
BA_ "SeToolName_SIGNAL" SG_ 2432687168 Pto4Status_ISig_5 "Pto4Status";
BA_ "SeToolVersion_SIGNAL" SG_ 2432687168 Pto4Status_ISig_5 "3";
BA_ "GenSigCycleTime" SG_ 2550121792 DayLocal_ISig_5 100;
BA_ "GenSigCycleTimeActive" SG_ 2550121792 DayLocal_ISig_5 100;
BA_ "GenSigStartValue" SG_ 2550121792 DayLocal_ISig_5 255;
BA_ "GenSigCycleTime" SG_ 2550121792 SecondsLocal_ISig_5 100;
BA_ "GenSigCycleTimeActive" SG_ 2550121792 SecondsLocal_ISig_5 100;
BA_ "GenSigStartValue" SG_ 2550121792 SecondsLocal_ISig_5 255;
BA_ "GenSigCycleTime" SG_ 2550121792 YearLocal_ISig_5 100;
BA_ "GenSigCycleTimeActive" SG_ 2550121792 YearLocal_ISig_5 100;
BA_ "GenSigStartValue" SG_ 2550121792 YearLocal_ISig_5 255;
BA_ "GenSigCycleTime" SG_ 2550121792 MinutesLocal_ISig_5 100;
BA_ "GenSigCycleTimeActive" SG_ 2550121792 MinutesLocal_ISig_5 100;
BA_ "GenSigStartValue" SG_ 2550121792 MinutesLocal_ISig_5 255;
BA_ "GenSigCycleTime" SG_ 2550121792 BatterySOCAlertRawData_rqst_ISig 100;
BA_ "GenSigCycleTimeActive" SG_ 2550121792 BatterySOCAlertRawData_rqst_ISig 100;
BA_ "GenSigStartValue" SG_ 2550121792 BatterySOCAlertRawData_rqst_ISig 7;
BA_ "SystemSignalLongSymbol" SG_ 2550121792 BatterySOCAlertRawData_rqst_ISig "BatterySOCAlertRawData_rqst_ISig_5";
BA_ "GenSigCycleTime" SG_ 2550121792 HoursLocal_ISig_5 100;
BA_ "GenSigCycleTimeActive" SG_ 2550121792 HoursLocal_ISig_5 100;
BA_ "GenSigStartValue" SG_ 2550121792 HoursLocal_ISig_5 255;
BA_ "GenSigCycleTime" SG_ 2550121792 MonthLocal_ISig_5 100;
BA_ "GenSigCycleTimeActive" SG_ 2550121792 MonthLocal_ISig_5 100;
BA_ "GenSigStartValue" SG_ 2550121792 MonthLocal_ISig_5 255;
BA_ "GenSigCycleTime" SG_ 2550115648 YearUTC_ISig_5 100;
BA_ "GenSigCycleTimeActive" SG_ 2550115648 YearUTC_ISig_5 100;
BA_ "GenSigStartValue" SG_ 2550115648 YearUTC_ISig_5 255;
BA_ "SeToolAncestorID_SIGNAL" SG_ 2550115648 YearUTC_ISig_5 "x0000001D0412FACB";
BA_ "SeToolItemID_SIGNAL" SG_ 2550115648 YearUTC_ISig_5 "x0000001D041EBCEF";
BA_ "SeToolName_SIGNAL" SG_ 2550115648 YearUTC_ISig_5 "YearUTC";
BA_ "SeToolVersion_SIGNAL" SG_ 2550115648 YearUTC_ISig_5 "2";
BA_ "GenSigCycleTime" SG_ 2550115648 SecondsUTC_ISig_5 100;
BA_ "GenSigCycleTimeActive" SG_ 2550115648 SecondsUTC_ISig_5 100;
BA_ "GenSigStartValue" SG_ 2550115648 SecondsUTC_ISig_5 255;
BA_ "SeToolAncestorID_SIGNAL" SG_ 2550115648 SecondsUTC_ISig_5 "x0000001D0412FABE";
BA_ "SeToolItemID_SIGNAL" SG_ 2550115648 SecondsUTC_ISig_5 "x0000001D041EBD32";
BA_ "SeToolName_SIGNAL" SG_ 2550115648 SecondsUTC_ISig_5 "SecondsUTC";
BA_ "SeToolVersion_SIGNAL" SG_ 2550115648 SecondsUTC_ISig_5 "2";
BA_ "GenSigCycleTime" SG_ 2550115648 DayUTC_ISig_5 100;
BA_ "GenSigCycleTimeActive" SG_ 2550115648 DayUTC_ISig_5 100;
BA_ "GenSigStartValue" SG_ 2550115648 DayUTC_ISig_5 255;
BA_ "SeToolAncestorID_SIGNAL" SG_ 2550115648 DayUTC_ISig_5 "x0000001D0412FAC4";
BA_ "SeToolItemID_SIGNAL" SG_ 2550115648 DayUTC_ISig_5 "x0000001D041EBD81";
BA_ "SeToolName_SIGNAL" SG_ 2550115648 DayUTC_ISig_5 "DayUTC";
BA_ "SeToolVersion_SIGNAL" SG_ 2550115648 DayUTC_ISig_5 "2";
BA_ "GenSigCycleTime" SG_ 2550115648 MinutesUTC_ISig_5 100;
BA_ "GenSigCycleTimeActive" SG_ 2550115648 MinutesUTC_ISig_5 100;
BA_ "GenSigStartValue" SG_ 2550115648 MinutesUTC_ISig_5 255;
BA_ "SeToolAncestorID_SIGNAL" SG_ 2550115648 MinutesUTC_ISig_5 "x0000001D0412FAC0";
BA_ "SeToolItemID_SIGNAL" SG_ 2550115648 MinutesUTC_ISig_5 "x0000001D041EBD29";
BA_ "SeToolName_SIGNAL" SG_ 2550115648 MinutesUTC_ISig_5 "MinutesUTC";
BA_ "SeToolVersion_SIGNAL" SG_ 2550115648 MinutesUTC_ISig_5 "2";
BA_ "GenSigCycleTime" SG_ 2550115648 HoursUTC_ISig_5 100;
BA_ "GenSigCycleTimeActive" SG_ 2550115648 HoursUTC_ISig_5 100;
BA_ "GenSigStartValue" SG_ 2550115648 HoursUTC_ISig_5 255;
BA_ "SeToolAncestorID_SIGNAL" SG_ 2550115648 HoursUTC_ISig_5 "x0000001D0412FAC2";
BA_ "SeToolItemID_SIGNAL" SG_ 2550115648 HoursUTC_ISig_5 "x0000001D041EBD20";
BA_ "SeToolName_SIGNAL" SG_ 2550115648 HoursUTC_ISig_5 "HoursUTC";
BA_ "SeToolVersion_SIGNAL" SG_ 2550115648 HoursUTC_ISig_5 "2";
BA_ "GenSigCycleTime" SG_ 2550115648 MonthUTC_ISig_5 100;
BA_ "GenSigCycleTimeActive" SG_ 2550115648 MonthUTC_ISig_5 100;
BA_ "GenSigStartValue" SG_ 2550115648 MonthUTC_ISig_5 255;
BA_ "SeToolAncestorID_SIGNAL" SG_ 2550115648 MonthUTC_ISig_5 "x0000001D0412FAC9";
BA_ "SeToolItemID_SIGNAL" SG_ 2550115648 MonthUTC_ISig_5 "x0000001D041EBD16";
BA_ "SeToolName_SIGNAL" SG_ 2550115648 MonthUTC_ISig_5 "MonthUTC";
BA_ "SeToolVersion_SIGNAL" SG_ 2550115648 MonthUTC_ISig_5 "2";
BA_ "GenSigCycleTime" SG_ 2432669248 AuxSwitchBbLoad2_Status_ISig_5 100;
BA_ "GenSigCycleTimeActive" SG_ 2432669248 AuxSwitchBbLoad2_Status_ISig_5 100;
BA_ "GenSigStartValue" SG_ 2432669248 AuxSwitchBbLoad2_Status_ISig_5 3;
BA_ "GenSigCycleTime" SG_ 2432669248 DoorLock_stat_ISig_5 100;
BA_ "GenSigCycleTimeActive" SG_ 2432669248 DoorLock_stat_ISig_5 100;
BA_ "GenSigStartValue" SG_ 2432669248 DoorLock_stat_ISig_5 15;
BA_ "GenSigMaxLatency" SG_ 2432669248 DoorLock_stat_ISig_5 26;
BA_ "GenSigCycleTime" SG_ 2432669248 MirrorHeatNormalModeInd_cmd_2_IS 100;
BA_ "GenSigCycleTimeActive" SG_ 2432669248 MirrorHeatNormalModeInd_cmd_2_IS 100;
BA_ "SystemSignalLongSymbol" SG_ 2432669248 MirrorHeatNormalModeInd_cmd_2_IS "MirrorHeatNormalModeInd_cmd_2_ISig_5";
BA_ "GenSigCycleTime" SG_ 2432669248 PSWindowPosition_ISig_5 100;
BA_ "GenSigCycleTimeActive" SG_ 2432669248 PSWindowPosition_ISig_5 100;
BA_ "GenSigStartValue" SG_ 2432669248 PSWindowPosition_ISig_5 7;
BA_ "GenSigMaxLatency" SG_ 2432669248 PSWindowPosition_ISig_5 26;
BA_ "GenSigCycleTime" SG_ 2432669248 AuxSwitchBbLoad1_Status_ISig_5 100;
BA_ "GenSigCycleTimeActive" SG_ 2432669248 AuxSwitchBbLoad1_Status_ISig_5 100;
BA_ "GenSigStartValue" SG_ 2432669248 AuxSwitchBbLoad1_Status_ISig_5 3;
BA_ "GenSigCycleTime" SG_ 2432669248 ReducedLoadMode_stat_ISig_5 100;
BA_ "GenSigCycleTimeActive" SG_ 2432669248 ReducedLoadMode_stat_ISig_5 100;
BA_ "GenSigStartValue" SG_ 2432669248 ReducedLoadMode_stat_ISig_5 3;
BA_ "GenSigCycleTime" SG_ 2432669248 TrailersConnected_ISig_5 100;
BA_ "GenSigCycleTimeActive" SG_ 2432669248 TrailersConnected_ISig_5 100;
BA_ "GenSigStartValue" SG_ 2432669248 TrailersConnected_ISig_5 7;
BA_ "GenSigCycleTime" SG_ 2432669248 DriverDoorAjar_stat_ISig_5 100;
BA_ "GenSigCycleTimeActive" SG_ 2432669248 DriverDoorAjar_stat_ISig_5 100;
BA_ "GenSigStartValue" SG_ 2432669248 DriverDoorAjar_stat_ISig_5 7;
BA_ "GenSigMaxLatency" SG_ 2432669248 DriverDoorAjar_stat_ISig_5 26;
BA_ "GenSigCycleTime" SG_ 2432669248 AuxSwitchBbLoad6_Status_ISig_5 100;
BA_ "GenSigCycleTimeActive" SG_ 2432669248 AuxSwitchBbLoad6_Status_ISig_5 100;
BA_ "GenSigStartValue" SG_ 2432669248 AuxSwitchBbLoad6_Status_ISig_5 3;
BA_ "GenSigCycleTime" SG_ 2432669248 BunkBacklightCmd_ISig_5 100;
BA_ "GenSigCycleTimeActive" SG_ 2432669248 BunkBacklightCmd_ISig_5 100;
BA_ "GenSigMaxLatency" SG_ 2432669248 BunkBacklightCmd_ISig_5 26;
BA_ "GenSigCycleTime" SG_ 2432669248 AuxSwitchBbLoad4_Status_ISig_5 100;
BA_ "GenSigCycleTimeActive" SG_ 2432669248 AuxSwitchBbLoad4_Status_ISig_5 100;
BA_ "GenSigStartValue" SG_ 2432669248 AuxSwitchBbLoad4_Status_ISig_5 3;
BA_ "GenSigCycleTime" SG_ 2432669248 DSWindowPosition_ISig_5 100;
BA_ "GenSigCycleTimeActive" SG_ 2432669248 DSWindowPosition_ISig_5 100;
BA_ "GenSigStartValue" SG_ 2432669248 DSWindowPosition_ISig_5 7;
BA_ "GenSigMaxLatency" SG_ 2432669248 DSWindowPosition_ISig_5 26;
BA_ "GenSigCycleTime" SG_ 2432669248 SelectedLanguage_stat_ISig_5 100;
BA_ "GenSigCycleTimeActive" SG_ 2432669248 SelectedLanguage_stat_ISig_5 100;
BA_ "GenSigStartValue" SG_ 2432669248 SelectedLanguage_stat_ISig_5 63;
BA_ "GenSigMaxLatency" SG_ 2432669248 SelectedLanguage_stat_ISig_5 26;
BA_ "GenSigCycleTime" SG_ 2432669248 PassengerDoorAjar_stat_ISig_5 100;
BA_ "GenSigCycleTimeActive" SG_ 2432669248 PassengerDoorAjar_stat_ISig_5 100;
BA_ "GenSigStartValue" SG_ 2432669248 PassengerDoorAjar_stat_ISig_5 7;
BA_ "GenSigMaxLatency" SG_ 2432669248 PassengerDoorAjar_stat_ISig_5 26;
BA_ "GenSigCycleTime" SG_ 2432669248 BunkB1ParkHeaterTempSw_stat 100;
BA_ "GenSigCycleTimeActive" SG_ 2432669248 BunkB1ParkHeaterTempSw_stat 100;
BA_ "GenSigStartValue" SG_ 2432669248 BunkB1ParkHeaterTempSw_stat 7;
BA_ "GenSigMaxLatency" SG_ 2432669248 BunkB1ParkHeaterTempSw_stat 26;
BA_ "GenSigCycleTime" SG_ 2432669248 AuxSwitchBbLoad5_Status_ISig_5 100;
BA_ "GenSigCycleTimeActive" SG_ 2432669248 AuxSwitchBbLoad5_Status_ISig_5 100;
BA_ "GenSigStartValue" SG_ 2432669248 AuxSwitchBbLoad5_Status_ISig_5 3;
BA_ "GenSigCycleTime" SG_ 2432669248 AudioVolumeIndicationCmd_ISig_5 100;
BA_ "GenSigCycleTimeActive" SG_ 2432669248 AudioVolumeIndicationCmd_ISig_5 100;
BA_ "GenSigMaxLatency" SG_ 2432669248 AudioVolumeIndicationCmd_ISig_5 26;
BA_ "GenSigCycleTime" SG_ 2432669248 AuxSwitchBbLoad3_Status_ISig_5 100;
BA_ "GenSigCycleTimeActive" SG_ 2432669248 AuxSwitchBbLoad3_Status_ISig_5 100;
BA_ "GenSigStartValue" SG_ 2432669248 AuxSwitchBbLoad3_Status_ISig_5 3;
BA_ "GenSigCycleTime" SG_ 2432669248 BunkH2TempInc_ButtonStatus 100;
BA_ "GenSigCycleTimeActive" SG_ 2432669248 BunkH2TempInc_ButtonStatus 100;
BA_ "GenSigStartValue" SG_ 2432669248 BunkH2TempInc_ButtonStatus 3;
BA_ "GenSigMaxLatency" SG_ 2432669248 BunkH2TempInc_ButtonStatus 26;
BA_ "GenSigCycleTime" SG_ 2432669248 DayOfWeek_stat_ISig_5 100;
BA_ "GenSigCycleTimeActive" SG_ 2432669248 DayOfWeek_stat_ISig_5 100;
BA_ "GenSigStartValue" SG_ 2432669248 DayOfWeek_stat_ISig_5 15;
BA_ "GenSigMaxLatency" SG_ 2432669248 DayOfWeek_stat_ISig_5 26;
BA_REL_ "GenSigFirstTimeoutTime" BU_SG_REL_ WRCS SG_ 2516128064 Trailer1LiftAxles_LiftAxle2Id_IS 2400;
BA_REL_ "GenSigTimeoutTime" BU_SG_REL_ WRCS SG_ 2516128064 Trailer1LiftAxles_LiftAxle2Id_IS 600;
BA_REL_ "GenSigFirstTimeoutTime" BU_SG_REL_ WRCS SG_ 2516128064 Trailer4LiftAxles_LiftAxle1Pos_I 2400;
BA_REL_ "GenSigTimeoutTime" BU_SG_REL_ WRCS SG_ 2516128064 Trailer4LiftAxles_LiftAxle1Pos_I 600;
BA_REL_ "GenSigFirstTimeoutTime" BU_SG_REL_ WRCS SG_ 2516128064 Trailer2LiftAxles_LiftAxle1Pos_I 2400;
BA_REL_ "GenSigTimeoutTime" BU_SG_REL_ WRCS SG_ 2516128064 Trailer2LiftAxles_LiftAxle1Pos_I 600;
BA_REL_ "GenSigFirstTimeoutTime" BU_SG_REL_ WRCS SG_ 2516128064 Trailer2LiftAxles_LiftAxle2Id_IS 2400;
BA_REL_ "GenSigTimeoutTime" BU_SG_REL_ WRCS SG_ 2516128064 Trailer2LiftAxles_LiftAxle2Id_IS 600;
BA_REL_ "GenSigFirstTimeoutTime" BU_SG_REL_ WRCS SG_ 2516128064 Trailer2LiftAxles_LiftAxle2Pos_I 2400;
BA_REL_ "GenSigTimeoutTime" BU_SG_REL_ WRCS SG_ 2516128064 Trailer2LiftAxles_LiftAxle2Pos_I 600;
BA_REL_ "GenSigFirstTimeoutTime" BU_SG_REL_ WRCS SG_ 2516128064 Trailer4LiftAxles_LiftAxle2Pos_I 2400;
BA_REL_ "GenSigTimeoutTime" BU_SG_REL_ WRCS SG_ 2516128064 Trailer4LiftAxles_LiftAxle2Pos_I 600;
BA_REL_ "GenSigFirstTimeoutTime" BU_SG_REL_ WRCS SG_ 2516128064 Trailer5LiftAxles_LiftAxle2Id_IS 2400;
BA_REL_ "GenSigTimeoutTime" BU_SG_REL_ WRCS SG_ 2516128064 Trailer5LiftAxles_LiftAxle2Id_IS 600;
BA_REL_ "GenSigFirstTimeoutTime" BU_SG_REL_ WRCS SG_ 2516128064 Trailer4LiftAxles_LiftAxle1Id_IS 2400;
BA_REL_ "GenSigTimeoutTime" BU_SG_REL_ WRCS SG_ 2516128064 Trailer4LiftAxles_LiftAxle1Id_IS 600;
BA_REL_ "GenSigFirstTimeoutTime" BU_SG_REL_ WRCS SG_ 2516128064 Trailer3LiftAxles_LiftAxle2Id_IS 2400;
BA_REL_ "GenSigTimeoutTime" BU_SG_REL_ WRCS SG_ 2516128064 Trailer3LiftAxles_LiftAxle2Id_IS 600;
BA_REL_ "GenSigFirstTimeoutTime" BU_SG_REL_ WRCS SG_ 2516128064 Trailer2LiftAxles_LiftAxle1Id_IS 2400;
BA_REL_ "GenSigTimeoutTime" BU_SG_REL_ WRCS SG_ 2516128064 Trailer2LiftAxles_LiftAxle1Id_IS 600;
BA_REL_ "GenSigFirstTimeoutTime" BU_SG_REL_ WRCS SG_ 2516128064 Trailer5LiftAxles_LiftAxle1Pos_I 2400;
BA_REL_ "GenSigTimeoutTime" BU_SG_REL_ WRCS SG_ 2516128064 Trailer5LiftAxles_LiftAxle1Pos_I 600;
BA_REL_ "GenSigFirstTimeoutTime" BU_SG_REL_ WRCS SG_ 2516128064 Trailer1LiftAxles_LiftAxle1Id_IS 2400;
BA_REL_ "GenSigTimeoutTime" BU_SG_REL_ WRCS SG_ 2516128064 Trailer1LiftAxles_LiftAxle1Id_IS 600;
BA_REL_ "GenSigFirstTimeoutTime" BU_SG_REL_ WRCS SG_ 2516128064 Trailer3LiftAxles_LiftAxle1Pos_I 2400;
BA_REL_ "GenSigTimeoutTime" BU_SG_REL_ WRCS SG_ 2516128064 Trailer3LiftAxles_LiftAxle1Pos_I 600;
BA_REL_ "GenSigFirstTimeoutTime" BU_SG_REL_ WRCS SG_ 2516128064 Trailer5LiftAxles_LiftAxle1Id_IS 2400;
BA_REL_ "GenSigTimeoutTime" BU_SG_REL_ WRCS SG_ 2516128064 Trailer5LiftAxles_LiftAxle1Id_IS 600;
BA_REL_ "GenSigFirstTimeoutTime" BU_SG_REL_ WRCS SG_ 2516128064 Trailer1LiftAxles_LiftAxle2Pos_I 2400;
BA_REL_ "GenSigTimeoutTime" BU_SG_REL_ WRCS SG_ 2516128064 Trailer1LiftAxles_LiftAxle2Pos_I 600;
BA_REL_ "GenSigFirstTimeoutTime" BU_SG_REL_ WRCS SG_ 2516128064 Trailer5LiftAxles_LiftAxle2Pos_I 2400;
BA_REL_ "GenSigTimeoutTime" BU_SG_REL_ WRCS SG_ 2516128064 Trailer5LiftAxles_LiftAxle2Pos_I 600;
BA_REL_ "GenSigFirstTimeoutTime" BU_SG_REL_ WRCS SG_ 2516128064 Trailer3LiftAxles_LiftAxle1Id_IS 2400;
BA_REL_ "GenSigTimeoutTime" BU_SG_REL_ WRCS SG_ 2516128064 Trailer3LiftAxles_LiftAxle1Id_IS 600;
BA_REL_ "GenSigFirstTimeoutTime" BU_SG_REL_ WRCS SG_ 2516128064 Trailer1LiftAxles_LiftAxle1Pos_I 2400;
BA_REL_ "GenSigTimeoutTime" BU_SG_REL_ WRCS SG_ 2516128064 Trailer1LiftAxles_LiftAxle1Pos_I 600;
BA_REL_ "GenSigFirstTimeoutTime" BU_SG_REL_ WRCS SG_ 2516128064 Trailer3LiftAxles_LiftAxle2Pos_I 2400;
BA_REL_ "GenSigTimeoutTime" BU_SG_REL_ WRCS SG_ 2516128064 Trailer3LiftAxles_LiftAxle2Pos_I 600;
BA_REL_ "GenSigFirstTimeoutTime" BU_SG_REL_ WRCS SG_ 2516128064 Trailer4LiftAxles_LiftAxle2Id_IS 2400;
BA_REL_ "GenSigTimeoutTime" BU_SG_REL_ WRCS SG_ 2516128064 Trailer4LiftAxles_LiftAxle2Id_IS 600;
BA_REL_ "GenSigFirstTimeoutTime" BU_SG_REL_ CCM SG_ 2499679296 CoolantPumpEngagementStatus_ISig 3000;
BA_REL_ "GenSigTimeoutTime" BU_SG_REL_ CCM SG_ 2499679296 CoolantPumpEngagementStatus_ISig 300;
BA_REL_ "GenSigFirstTimeoutTime" BU_SG_REL_ CCM SG_ 2499679296 PHTimerRqstAck_Hours_ISig_5 3000;
BA_REL_ "GenSigTimeoutTime" BU_SG_REL_ CCM SG_ 2499679296 PHTimerRqstAck_Hours_ISig_5 300;
BA_REL_ "GenSigFirstTimeoutTime" BU_SG_REL_ LECM1 SG_ 2499679296 AudioMuteStat_ISig_5 3000;
BA_REL_ "GenSigTimeoutTime" BU_SG_REL_ LECM1 SG_ 2499679296 AudioMuteStat_ISig_5 300;
BA_REL_ "GenSigFirstTimeoutTime" BU_SG_REL_ WRCS SG_ 2499679296 LoadDistributionSelected_ISig_5 3000;
BA_REL_ "GenSigTimeoutTime" BU_SG_REL_ WRCS SG_ 2499679296 LoadDistributionSelected_ISig_5 300;
BA_REL_ "GenSigFirstTimeoutTime" BU_SG_REL_ CCM SG_ 2499679296 PHTimerRqstAck_DayOfWeekRq_ISig_ 3000;
BA_REL_ "GenSigTimeoutTime" BU_SG_REL_ CCM SG_ 2499679296 PHTimerRqstAck_DayOfWeekRq_ISig_ 300;
BA_REL_ "GenSigFirstTimeoutTime" BU_SG_REL_ CCM SG_ 2499679296 PHTimerRqstAck_Minutes_ISig_5 3000;
BA_REL_ "GenSigTimeoutTime" BU_SG_REL_ CCM SG_ 2499679296 PHTimerRqstAck_Minutes_ISig_5 300;
BA_REL_ "GenSigFirstTimeoutTime" BU_SG_REL_ WRCS SG_ 2499679296 LiftAxle1PositionStatus_ISig_5 3000;
BA_REL_ "GenSigTimeoutTime" BU_SG_REL_ WRCS SG_ 2499679296 LiftAxle1PositionStatus_ISig_5 300;
BA_REL_ "GenSigFirstTimeoutTime" BU_SG_REL_ CCM SG_ 2499679296 PHTimerRqstAck_CurrentOp_ISig_5 3000;
BA_REL_ "GenSigTimeoutTime" BU_SG_REL_ CCM SG_ 2499679296 PHTimerRqstAck_CurrentOp_ISig_5 300;
BA_REL_ "GenSigFirstTimeoutTime" BU_SG_REL_ WRCS SG_ 2499679296 LiftAxle2PositionStatus_ISig_5 3000;
BA_REL_ "GenSigTimeoutTime" BU_SG_REL_ WRCS SG_ 2499679296 LiftAxle2PositionStatus_ISig_5 300;
BA_REL_ "GenSigFirstTimeoutTime" BU_SG_REL_ CCM SG_ 2499679296 EngineCoolingFanSpeed_ISig_5 3000;
BA_REL_ "GenSigTimeoutTime" BU_SG_REL_ CCM SG_ 2499679296 EngineCoolingFanSpeed_ISig_5 300;
BA_REL_ "GenSigFirstTimeoutTime" BU_SG_REL_ WRCS SG_ 2499679296 ParkingBrake_stat_ISig_5 3000;
BA_REL_ "GenSigTimeoutTime" BU_SG_REL_ WRCS SG_ 2499679296 ParkingBrake_stat_ISig_5 300;
BA_REL_ "GenSigFirstTimeoutTime" BU_SG_REL_ LECM1 SG_ 2549186373 AudioSourceStatus2_ISig_5 3600;
BA_REL_ "GenSigTimeoutTime" BU_SG_REL_ LECM1 SG_ 2549186373 AudioSourceStatus2_ISig_5 900;
BA_REL_ "GenSigFirstTimeoutTime" BU_SG_REL_ WRCS SG_ 2549186373 Trailer1NumberOfFrontAxles_ISig_ 3600;
BA_REL_ "GenSigTimeoutTime" BU_SG_REL_ WRCS SG_ 2549186373 Trailer1NumberOfFrontAxles_ISig_ 900;
BA_REL_ "GenSigFirstTimeoutTime" BU_SG_REL_ WRCS SG_ 2549186373 Trailer5NumberOfFrontAxles_ISig_ 3600;
BA_REL_ "GenSigTimeoutTime" BU_SG_REL_ WRCS SG_ 2549186373 Trailer5NumberOfFrontAxles_ISig_ 900;
BA_REL_ "GenSigFirstTimeoutTime" BU_SG_REL_ CCM SG_ 2549186373 RemoteParkingClimateRqst_ISig_5 3000;
BA_REL_ "GenSigTimeoutTime" BU_SG_REL_ CCM SG_ 2549186373 RemoteParkingClimateRqst_ISig_5 900;
BA_REL_ "GenSigFirstTimeoutTime" BU_SG_REL_ WRCS SG_ 2549186373 Trailer2NumberOfFrontAxles_ISig_ 3600;
BA_REL_ "GenSigTimeoutTime" BU_SG_REL_ WRCS SG_ 2549186373 Trailer2NumberOfFrontAxles_ISig_ 900;
BA_REL_ "GenSigFirstTimeoutTime" BU_SG_REL_ LECM1 SG_ 2549186373 AudioSourceUsbAvailable_ISig_5 3600;
BA_REL_ "GenSigTimeoutTime" BU_SG_REL_ LECM1 SG_ 2549186373 AudioSourceUsbAvailable_ISig_5 900;
BA_REL_ "GenSigFirstTimeoutTime" BU_SG_REL_ LECM1 SG_ 2549186373 AudioSourceBtStreamAvailable_ISi 3600;
BA_REL_ "GenSigTimeoutTime" BU_SG_REL_ LECM1 SG_ 2549186373 AudioSourceBtStreamAvailable_ISi 900;
BA_REL_ "GenSigFirstTimeoutTime" BU_SG_REL_ LECM1 SG_ 2549186373 AudioSourceIpodAvailable_ISig_5 3600;
BA_REL_ "GenSigTimeoutTime" BU_SG_REL_ LECM1 SG_ 2549186373 AudioSourceIpodAvailable_ISig_5 900;
BA_REL_ "GenSigFirstTimeoutTime" BU_SG_REL_ WRCS SG_ 2549186373 Trailer3NumberOfFrontAxles_ISig_ 3600;
BA_REL_ "GenSigTimeoutTime" BU_SG_REL_ WRCS SG_ 2549186373 Trailer3NumberOfFrontAxles_ISig_ 900;
BA_REL_ "GenSigFirstTimeoutTime" BU_SG_REL_ WRCS SG_ 2549186373 Trailer4NumberOfFrontAxles_ISig_ 3600;
BA_REL_ "GenSigTimeoutTime" BU_SG_REL_ WRCS SG_ 2549186373 Trailer4NumberOfFrontAxles_ISig_ 900;
BA_REL_ "GenSigFirstTimeoutTime" BU_SG_REL_ LECM1 SG_ 2549186373 AudioSourceCdAvailable_ISig_5 3600;
BA_REL_ "GenSigTimeoutTime" BU_SG_REL_ LECM1 SG_ 2549186373 AudioSourceCdAvailable_ISig_5 900;
BA_REL_ "GenSigFirstTimeoutTime" BU_SG_REL_ WRCS SG_ 2566879231 VehFrontAxle1CalibratedLoad_ISig 12000;
BA_REL_ "GenSigTimeoutTime" BU_SG_REL_ WRCS SG_ 2566879231 VehFrontAxle1CalibratedLoad_ISig 3000;
BA_REL_ "GenSigFirstTimeoutTime" BU_SG_REL_ WRCS SG_ 2566879231 VehicleCalibratedCargoLoad_ISig_ 12000;
BA_REL_ "GenSigTimeoutTime" BU_SG_REL_ WRCS SG_ 2566879231 VehicleCalibratedCargoLoad_ISig_ 3000;
BA_REL_ "GenSigFirstTimeoutTime" BU_SG_REL_ WRCS SG_ 2566879231 VehFrontAxle2CalibratedLoad_ISig 12000;
BA_REL_ "GenSigTimeoutTime" BU_SG_REL_ WRCS SG_ 2566879231 VehFrontAxle2CalibratedLoad_ISig 3000;
BA_REL_ "GenSigFirstTimeoutTime" BU_SG_REL_ WRCS SG_ 2566879231 VehicleCalibratedLoad_ISig_5 12000;
BA_REL_ "GenSigTimeoutTime" BU_SG_REL_ WRCS SG_ 2566879231 VehicleCalibratedLoad_ISig_5 3000;
BA_REL_ "GenSigFirstTimeoutTime" BU_SG_REL_ WRCS SG_ 2566809599 VehRearAxle3CalibratedLoad_ISig_ 12000;
BA_REL_ "GenSigTimeoutTime" BU_SG_REL_ WRCS SG_ 2566809599 VehRearAxle3CalibratedLoad_ISig_ 3000;
BA_REL_ "GenSigFirstTimeoutTime" BU_SG_REL_ WRCS SG_ 2566809599 Trailer5Type_ISig_5 12000;
BA_REL_ "GenSigTimeoutTime" BU_SG_REL_ WRCS SG_ 2566809599 Trailer5Type_ISig_5 3000;
BA_REL_ "GenSigFirstTimeoutTime" BU_SG_REL_ WRCS SG_ 2566809599 VehRearAxle2CalibratedLoad_ISig_ 12000;
BA_REL_ "GenSigTimeoutTime" BU_SG_REL_ WRCS SG_ 2566809599 VehRearAxle2CalibratedLoad_ISig_ 3000;
BA_REL_ "GenSigFirstTimeoutTime" BU_SG_REL_ WRCS SG_ 2566809599 VehRearAxle1CalibratedLoad_ISig_ 12000;
BA_REL_ "GenSigTimeoutTime" BU_SG_REL_ WRCS SG_ 2566809599 VehRearAxle1CalibratedLoad_ISig_ 3000;
BA_REL_ "GenSigFirstTimeoutTime" BU_SG_REL_ WRCS SG_ 2566809599 Trailer2Type_ISig_5 12000;
BA_REL_ "GenSigTimeoutTime" BU_SG_REL_ WRCS SG_ 2566809599 Trailer2Type_ISig_5 3000;
BA_REL_ "GenSigFirstTimeoutTime" BU_SG_REL_ WRCS SG_ 2566809599 Trailer4Type_ISig_5 12000;
BA_REL_ "GenSigTimeoutTime" BU_SG_REL_ WRCS SG_ 2566809599 Trailer4Type_ISig_5 3000;
BA_REL_ "GenSigFirstTimeoutTime" BU_SG_REL_ WRCS SG_ 2566809599 Trailer1Type_ISig_5 12000;
BA_REL_ "GenSigTimeoutTime" BU_SG_REL_ WRCS SG_ 2566809599 Trailer1Type_ISig_5 3000;
BA_REL_ "GenSigFirstTimeoutTime" BU_SG_REL_ WRCS SG_ 2566809599 Trailer3Type_ISig_5 12000;
BA_REL_ "GenSigTimeoutTime" BU_SG_REL_ WRCS SG_ 2566809599 Trailer3Type_ISig_5 3000;
BA_REL_ "GenSigFirstTimeoutTime" BU_SG_REL_ WRCS SG_ 2566670335 Trailer5CalibratedTotalLoad_ISig 12000;
BA_REL_ "GenSigTimeoutTime" BU_SG_REL_ WRCS SG_ 2566670335 Trailer5CalibratedTotalLoad_ISig 3000;
BA_REL_ "GenSigFirstTimeoutTime" BU_SG_REL_ WRCS SG_ 2566670335 Trailer5CalibratedCargoLoad_ISig 12000;
BA_REL_ "GenSigTimeoutTime" BU_SG_REL_ WRCS SG_ 2566670335 Trailer5CalibratedCargoLoad_ISig 3000;
BA_REL_ "GenSigFirstTimeoutTime" BU_SG_REL_ WRCS SG_ 2566670335 Trailer5NumberOfAxles_ISig_5 12000;
BA_REL_ "GenSigTimeoutTime" BU_SG_REL_ WRCS SG_ 2566670335 Trailer5NumberOfAxles_ISig_5 3000;
BA_REL_ "GenSigFirstTimeoutTime" BU_SG_REL_ WRCS SG_ 2566670335 Trailer5CalAxleLoad_AxleLoad_ISi 12000;
BA_REL_ "GenSigTimeoutTime" BU_SG_REL_ WRCS SG_ 2566670335 Trailer5CalAxleLoad_AxleLoad_ISi 3000;
BA_REL_ "GenSigFirstTimeoutTime" BU_SG_REL_ WRCS SG_ 2566670335 Trailer5CalAxleLoad_AxleId_ISig_ 12000;
BA_REL_ "GenSigTimeoutTime" BU_SG_REL_ WRCS SG_ 2566670335 Trailer5CalAxleLoad_AxleId_ISig_ 3000;
BA_REL_ "GenSigFirstTimeoutTime" BU_SG_REL_ WRCS SG_ 2566531071 Trailer4NumberOfAxles_ISig_5 12000;
BA_REL_ "GenSigTimeoutTime" BU_SG_REL_ WRCS SG_ 2566531071 Trailer4NumberOfAxles_ISig_5 3000;
BA_REL_ "GenSigFirstTimeoutTime" BU_SG_REL_ WRCS SG_ 2566531071 Trailer4CalAxleLoad_AxleId_ISig_ 12000;
BA_REL_ "GenSigTimeoutTime" BU_SG_REL_ WRCS SG_ 2566531071 Trailer4CalAxleLoad_AxleId_ISig_ 3000;
BA_REL_ "GenSigFirstTimeoutTime" BU_SG_REL_ WRCS SG_ 2566531071 Trailer4CalAxleLoad_AxleLoad_ISi 12000;
BA_REL_ "GenSigTimeoutTime" BU_SG_REL_ WRCS SG_ 2566531071 Trailer4CalAxleLoad_AxleLoad_ISi 3000;
BA_REL_ "GenSigFirstTimeoutTime" BU_SG_REL_ WRCS SG_ 2566531071 Trailer4CalibratedCargoLoad_ISig 12000;
BA_REL_ "GenSigTimeoutTime" BU_SG_REL_ WRCS SG_ 2566531071 Trailer4CalibratedCargoLoad_ISig 3000;
BA_REL_ "GenSigFirstTimeoutTime" BU_SG_REL_ WRCS SG_ 2566531071 Trailer4CalibratedTotalLoad_ISig 12000;
BA_REL_ "GenSigTimeoutTime" BU_SG_REL_ WRCS SG_ 2566531071 Trailer4CalibratedTotalLoad_ISig 3000;
BA_REL_ "GenSigFirstTimeoutTime" BU_SG_REL_ WRCS SG_ 2566391807 Trailer3CalibratedCargoLoad_ISig 12000;
BA_REL_ "GenSigTimeoutTime" BU_SG_REL_ WRCS SG_ 2566391807 Trailer3CalibratedCargoLoad_ISig 3000;
BA_REL_ "GenSigFirstTimeoutTime" BU_SG_REL_ WRCS SG_ 2566391807 Trailer3NumberOfAxles_ISig_5 12000;
BA_REL_ "GenSigTimeoutTime" BU_SG_REL_ WRCS SG_ 2566391807 Trailer3NumberOfAxles_ISig_5 3000;
BA_REL_ "GenSigFirstTimeoutTime" BU_SG_REL_ WRCS SG_ 2566391807 Trailer3CalibratedTotalLoad_ISig 12000;
BA_REL_ "GenSigTimeoutTime" BU_SG_REL_ WRCS SG_ 2566391807 Trailer3CalibratedTotalLoad_ISig 3000;
BA_REL_ "GenSigFirstTimeoutTime" BU_SG_REL_ WRCS SG_ 2566391807 Trailer3CalAxleLoad_AxleLoad_ISi 12000;
BA_REL_ "GenSigTimeoutTime" BU_SG_REL_ WRCS SG_ 2566391807 Trailer3CalAxleLoad_AxleLoad_ISi 3000;
BA_REL_ "GenSigFirstTimeoutTime" BU_SG_REL_ WRCS SG_ 2566391807 Trailer3CalAxleLoad_AxleId_ISig_ 12000;
BA_REL_ "GenSigTimeoutTime" BU_SG_REL_ WRCS SG_ 2566391807 Trailer3CalAxleLoad_AxleId_ISig_ 3000;
BA_REL_ "GenSigFirstTimeoutTime" BU_SG_REL_ WRCS SG_ 2566252543 Trailer2NumberOfAxles_ISig_5 12000;
BA_REL_ "GenSigTimeoutTime" BU_SG_REL_ WRCS SG_ 2566252543 Trailer2NumberOfAxles_ISig_5 3000;
BA_REL_ "GenSigFirstTimeoutTime" BU_SG_REL_ WRCS SG_ 2566252543 Trailer2CalAxleLoad_AxleId_ISig_ 12000;
BA_REL_ "GenSigTimeoutTime" BU_SG_REL_ WRCS SG_ 2566252543 Trailer2CalAxleLoad_AxleId_ISig_ 3000;
BA_REL_ "GenSigFirstTimeoutTime" BU_SG_REL_ WRCS SG_ 2566252543 Trailer2CalibratedCargoLoad_ISig 12000;
BA_REL_ "GenSigTimeoutTime" BU_SG_REL_ WRCS SG_ 2566252543 Trailer2CalibratedCargoLoad_ISig 3000;
BA_REL_ "GenSigFirstTimeoutTime" BU_SG_REL_ WRCS SG_ 2566252543 Trailer2CalAxleLoad_AxleLoad_ISi 12000;
BA_REL_ "GenSigTimeoutTime" BU_SG_REL_ WRCS SG_ 2566252543 Trailer2CalAxleLoad_AxleLoad_ISi 3000;
BA_REL_ "GenSigFirstTimeoutTime" BU_SG_REL_ WRCS SG_ 2566252543 Trailer2CalibratedTotalLoad_ISig 12000;
BA_REL_ "GenSigTimeoutTime" BU_SG_REL_ WRCS SG_ 2566252543 Trailer2CalibratedTotalLoad_ISig 3000;
BA_REL_ "GenSigFirstTimeoutTime" BU_SG_REL_ WRCS SG_ 2566113279 Trailer1CalibratedTotalLoad_ISig 12000;
BA_REL_ "GenSigTimeoutTime" BU_SG_REL_ WRCS SG_ 2566113279 Trailer1CalibratedTotalLoad_ISig 3000;
BA_REL_ "GenSigFirstTimeoutTime" BU_SG_REL_ WRCS SG_ 2566113279 Trailer1NumberOfAxles_ISig_5 12000;
BA_REL_ "GenSigTimeoutTime" BU_SG_REL_ WRCS SG_ 2566113279 Trailer1NumberOfAxles_ISig_5 3000;
BA_REL_ "GenSigFirstTimeoutTime" BU_SG_REL_ WRCS SG_ 2566113279 Trailer1CalAxleLoad_AxleId_ISig_ 12000;
BA_REL_ "GenSigTimeoutTime" BU_SG_REL_ WRCS SG_ 2566113279 Trailer1CalAxleLoad_AxleId_ISig_ 3000;
BA_REL_ "GenSigFirstTimeoutTime" BU_SG_REL_ WRCS SG_ 2566113279 Trailer1CalibratedCargoLoad_ISig 12000;
BA_REL_ "GenSigTimeoutTime" BU_SG_REL_ WRCS SG_ 2566113279 Trailer1CalibratedCargoLoad_ISig 3000;
BA_REL_ "GenSigFirstTimeoutTime" BU_SG_REL_ WRCS SG_ 2566113279 Trailer1CalAxleLoad_AxleLoad_ISi 12000;
BA_REL_ "GenSigTimeoutTime" BU_SG_REL_ WRCS SG_ 2566113279 Trailer1CalAxleLoad_AxleLoad_ISi 3000;
BA_REL_ "GenSigFirstTimeoutTime" BU_SG_REL_ LECM1 SG_ 2565904383 AlarmClockAlarms_stat_SetMin_ISi 3600;
BA_REL_ "GenSigTimeoutTime" BU_SG_REL_ LECM1 SG_ 2565904383 AlarmClockAlarms_stat_SetMin_ISi 900;
BA_REL_ "GenSigFirstTimeoutTime" BU_SG_REL_ WRCS SG_ 2565904383 ESCReqESC_CtrlTrimValue_ISig_5 3600;
BA_REL_ "GenSigTimeoutTime" BU_SG_REL_ WRCS SG_ 2565904383 ESCReqESC_CtrlTrimValue_ISig_5 900;
BA_REL_ "GenSigFirstTimeoutTime" BU_SG_REL_ LECM1 SG_ 2565904383 AlarmClockAlarms_stat_Mode_ISig_ 3600;
BA_REL_ "GenSigTimeoutTime" BU_SG_REL_ LECM1 SG_ 2565904383 AlarmClockAlarms_stat_Mode_ISig_ 900;
BA_REL_ "GenSigFirstTimeoutTime" BU_SG_REL_ LECM1 SG_ 2565904383 AlarmClockAlarms_stat_SetHr_ISig 3600;
BA_REL_ "GenSigTimeoutTime" BU_SG_REL_ LECM1 SG_ 2565904383 AlarmClockAlarms_stat_SetHr_ISig 900;
BA_REL_ "GenSigFirstTimeoutTime" BU_SG_REL_ LECM1 SG_ 2565904383 AlarmClockAlarms_stat_ID_ISig_5 3600;
BA_REL_ "GenSigTimeoutTime" BU_SG_REL_ LECM1 SG_ 2565904383 AlarmClockAlarms_stat_ID_ISig_5 900;
BA_REL_ "GenSigFirstTimeoutTime" BU_SG_REL_ LECM1 SG_ 2565904383 AlarmClockNotification_Stat_ISig 3600;
BA_REL_ "GenSigTimeoutTime" BU_SG_REL_ LECM1 SG_ 2565904383 AlarmClockNotification_Stat_ISig 900;
BA_REL_ "GenSigFirstTimeoutTime" BU_SG_REL_ LECM1 SG_ 2565904383 AlarmClockNotification_Type_ISig 3600;
BA_REL_ "GenSigTimeoutTime" BU_SG_REL_ LECM1 SG_ 2565904383 AlarmClockNotification_Type_ISig 900;
BA_REL_ "GenSigFirstTimeoutTime" BU_SG_REL_ LECM1 SG_ 2565904383 AlarmClockAlarms_stat_DaySet_ISi 3600;
BA_REL_ "GenSigTimeoutTime" BU_SG_REL_ LECM1 SG_ 2565904383 AlarmClockAlarms_stat_DaySet_ISi 900;
BA_REL_ "GenSigFirstTimeoutTime" BU_SG_REL_ WRCS SG_ 2565904383 ESCReqESC_CtrlTrimReq_ISig_5 3600;
BA_REL_ "GenSigTimeoutTime" BU_SG_REL_ WRCS SG_ 2565904383 ESCReqESC_CtrlTrimReq_ISig_5 900;
BA_REL_ "GenSigFirstTimeoutTime" BU_SG_REL_ LECM1 SG_ 2565904383 AlarmClockAlarms_stat_Stat_ISig_ 3600;
BA_REL_ "GenSigTimeoutTime" BU_SG_REL_ LECM1 SG_ 2565904383 AlarmClockAlarms_stat_Stat_ISig_ 900;
BA_REL_ "GenSigFirstTimeoutTime" BU_SG_REL_ WRCS SG_ 2565904383 ESCReqESC_CtrlTrimMode_ISig_5 3600;
BA_REL_ "GenSigTimeoutTime" BU_SG_REL_ WRCS SG_ 2565904383 ESCReqESC_CtrlTrimMode_ISig_5 900;
BA_REL_ "GenSigFirstTimeoutTime" BU_SG_REL_ WRCS SG_ 2565904383 ESCReqESC_CtrlTrimStat_ISig_5 3600;
BA_REL_ "GenSigTimeoutTime" BU_SG_REL_ WRCS SG_ 2565904383 ESCReqESC_CtrlTrimStat_ISig_5 900;
BA_REL_ "GenSigFirstTimeoutTime" BU_SG_REL_ LECM1 SG_ 2565904383 AlarmClockAlarms_stat_Type_ISig_ 3600;
BA_REL_ "GenSigTimeoutTime" BU_SG_REL_ LECM1 SG_ 2565904383 AlarmClockAlarms_stat_Type_ISig_ 900;
BA_REL_ "GenSigFirstTimeoutTime" BU_SG_REL_ LECM1 SG_ 2565904383 AlarmClockNotification_ID_ISig_5 3600;
BA_REL_ "GenSigTimeoutTime" BU_SG_REL_ LECM1 SG_ 2565904383 AlarmClockNotification_ID_ISig_5 900;
BA_REL_ "GenSigFirstTimeoutTime" BU_SG_REL_ WRCS SG_ 2499755967 FdEquipmentStatus2_ISig_5 3000;
BA_REL_ "GenSigTimeoutTime" BU_SG_REL_ WRCS SG_ 2499755967 FdEquipmentStatus2_ISig_5 300;
BA_REL_ "GenSigFirstTimeoutTime" BU_SG_REL_ WRCS SG_ 2499755967 RideHeightStatus_ISig_5 3000;
BA_REL_ "GenSigTimeoutTime" BU_SG_REL_ WRCS SG_ 2499755967 RideHeightStatus_ISig_5 300;
BA_REL_ "GenSigFirstTimeoutTime" BU_SG_REL_ WRCS SG_ 2499755967 FdEquipmentStatus4_ISig_5 3000;
BA_REL_ "GenSigTimeoutTime" BU_SG_REL_ WRCS SG_ 2499755967 FdEquipmentStatus4_ISig_5 300;
BA_REL_ "GenSigFirstTimeoutTime" BU_SG_REL_ WRCS SG_ 2499755967 RideHeightOutsideTargetRange_ISi 3000;
BA_REL_ "GenSigTimeoutTime" BU_SG_REL_ WRCS SG_ 2499755967 RideHeightOutsideTargetRange_ISi 300;
BA_REL_ "GenSigFirstTimeoutTime" BU_SG_REL_ WRCS SG_ 2499755967 FdEquipmentStatus1_ISig_5 3000;
BA_REL_ "GenSigTimeoutTime" BU_SG_REL_ WRCS SG_ 2499755967 FdEquipmentStatus1_ISig_5 300;
BA_REL_ "GenSigFirstTimeoutTime" BU_SG_REL_ WRCS SG_ 2499755967 FdEquipmentStatus5_ISig_5 3000;
BA_REL_ "GenSigTimeoutTime" BU_SG_REL_ WRCS SG_ 2499755967 FdEquipmentStatus5_ISig_5 300;
BA_REL_ "GenSigFirstTimeoutTime" BU_SG_REL_ WRCS SG_ 2499755967 RideHeightFunctionStatus_ISig_5 3000;
BA_REL_ "GenSigTimeoutTime" BU_SG_REL_ WRCS SG_ 2499755967 RideHeightFunctionStatus_ISig_5 300;
BA_REL_ "GenSigFirstTimeoutTime" BU_SG_REL_ WRCS SG_ 2499755967 FdEquipmentStatus3_ISig_5 3000;
BA_REL_ "GenSigTimeoutTime" BU_SG_REL_ WRCS SG_ 2499755967 FdEquipmentStatus3_ISig_5 300;
BA_REL_ "GenSigFirstTimeoutTime" BU_SG_REL_ WRCS SG_ 2499755967 FdEquipmentValue2_ISig_5 3000;
BA_REL_ "GenSigTimeoutTime" BU_SG_REL_ WRCS SG_ 2499755967 FdEquipmentValue2_ISig_5 300;
BA_REL_ "GenSigFirstTimeoutTime" BU_SG_REL_ WRCS SG_ 2499755967 FrontEndPositionStatus_ISig_5 3000;
BA_REL_ "GenSigTimeoutTime" BU_SG_REL_ WRCS SG_ 2499755967 FrontEndPositionStatus_ISig_5 300;
BA_REL_ "GenSigFirstTimeoutTime" BU_SG_REL_ WRCS SG_ 2499755967 RollEndPositionStatus_ISig_5 3000;
BA_REL_ "GenSigTimeoutTime" BU_SG_REL_ WRCS SG_ 2499755967 RollEndPositionStatus_ISig_5 300;
BA_REL_ "GenSigFirstTimeoutTime" BU_SG_REL_ WRCS SG_ 2499755967 RampLevelStatus_ISig_5 3000;
BA_REL_ "GenSigTimeoutTime" BU_SG_REL_ WRCS SG_ 2499755967 RampLevelStatus_ISig_5 300;
BA_REL_ "GenSigFirstTimeoutTime" BU_SG_REL_ WRCS SG_ 2499755967 FdEquipmentValue1_ISig_5 3000;
BA_REL_ "GenSigTimeoutTime" BU_SG_REL_ WRCS SG_ 2499755967 FdEquipmentValue1_ISig_5 300;
BA_REL_ "GenSigFirstTimeoutTime" BU_SG_REL_ WRCS SG_ 2499755967 RampHeightOutsideTargetRange_ISi 3000;
BA_REL_ "GenSigTimeoutTime" BU_SG_REL_ WRCS SG_ 2499755967 RampHeightOutsideTargetRange_ISi 300;
BA_REL_ "GenSigFirstTimeoutTime" BU_SG_REL_ WRCS SG_ 2499755967 FdEquipmentValue3_ISig_5 3000;
BA_REL_ "GenSigTimeoutTime" BU_SG_REL_ WRCS SG_ 2499755967 FdEquipmentValue3_ISig_5 300;
BA_REL_ "GenSigFirstTimeoutTime" BU_SG_REL_ WRCS SG_ 2499755967 RearEndPositionStatus_ISig_5 3000;
BA_REL_ "GenSigTimeoutTime" BU_SG_REL_ WRCS SG_ 2499755967 RearEndPositionStatus_ISig_5 300;
BA_REL_ "GenSigFirstTimeoutTime" BU_SG_REL_ WRCS SG_ 2432687168 Pto1Status_ISig_5 3000;
BA_REL_ "GenSigTimeoutTime" BU_SG_REL_ WRCS SG_ 2432687168 Pto1Status_ISig_5 120;
BA_REL_ "GenSigFirstTimeoutTime" BU_SG_REL_ WRCS SG_ 2432687168 BodyOrCabWorkingLightFdbk_stat_I 3000;
BA_REL_ "GenSigTimeoutTime" BU_SG_REL_ WRCS SG_ 2432687168 BodyOrCabWorkingLightFdbk_stat_I 120;
BA_REL_ "GenSigFirstTimeoutTime" BU_SG_REL_ CCM SG_ 2432687168 ElectricalLoadReduction_rqst_ISi 3000;
BA_REL_ "GenSigTimeoutTime" BU_SG_REL_ CCM SG_ 2432687168 ElectricalLoadReduction_rqst_ISi 500;
BA_REL_ "GenSigFirstTimeoutTime" BU_SG_REL_ WRCS SG_ 2432687168 ElectricalLoadReduction_rqst_ISi 3000;
BA_REL_ "GenSigTimeoutTime" BU_SG_REL_ WRCS SG_ 2432687168 ElectricalLoadReduction_rqst_ISi 500;
BA_REL_ "GenSigFirstTimeoutTime" BU_SG_REL_ WRCS SG_ 2432687168 CabWrknLightChassisFdbk_stat_ISi 3000;
BA_REL_ "GenSigTimeoutTime" BU_SG_REL_ WRCS SG_ 2432687168 CabWrknLightChassisFdbk_stat_ISi 120;
BA_REL_ "GenSigFirstTimeoutTime" BU_SG_REL_ WRCS SG_ 2432687168 ExtraBBTailLiftStatus_ISig_5 3000;
BA_REL_ "GenSigTimeoutTime" BU_SG_REL_ WRCS SG_ 2432687168 ExtraBBTailLiftStatus_ISig_5 120;
BA_REL_ "GenSigFirstTimeoutTime" BU_SG_REL_ SRS SG_ 2432687168 TotalVehicleDistanceHighRes_ISig 3000;
BA_REL_ "GenSigTimeoutTime" BU_SG_REL_ SRS SG_ 2432687168 TotalVehicleDistanceHighRes_ISig 120;
BA_REL_ "GenSigFirstTimeoutTime" BU_SG_REL_ LECM1 SG_ 2432687168 TotalVehicleDistanceHighRes_ISig 3000;
BA_REL_ "GenSigTimeoutTime" BU_SG_REL_ LECM1 SG_ 2432687168 TotalVehicleDistanceHighRes_ISig 120;
BA_REL_ "GenSigFirstTimeoutTime" BU_SG_REL_ WRCS SG_ 2432687168 TotalVehicleDistanceHighRes_ISig 3000;
BA_REL_ "GenSigTimeoutTime" BU_SG_REL_ WRCS SG_ 2432687168 TotalVehicleDistanceHighRes_ISig 120;
BA_REL_ "GenSigFirstTimeoutTime" BU_SG_REL_ CCM SG_ 2432687168 TotalVehicleDistanceHighRes_ISig 3000;
BA_REL_ "GenSigTimeoutTime" BU_SG_REL_ CCM SG_ 2432687168 TotalVehicleDistanceHighRes_ISig 120;
BA_REL_ "GenSigFirstTimeoutTime" BU_SG_REL_ WRCS SG_ 2432687168 ExtraBBCraneStatus_ISig_5 3000;
BA_REL_ "GenSigTimeoutTime" BU_SG_REL_ WRCS SG_ 2432687168 ExtraBBCraneStatus_ISig_5 120;
BA_REL_ "GenSigFirstTimeoutTime" BU_SG_REL_ WRCS SG_ 2432687168 Pto3Status_ISig_5 3000;
BA_REL_ "GenSigTimeoutTime" BU_SG_REL_ WRCS SG_ 2432687168 Pto3Status_ISig_5 120;
BA_REL_ "GenSigFirstTimeoutTime" BU_SG_REL_ WRCS SG_ 2432687168 CabExtraSideWrknLightFdbk_stat_I 3000;
BA_REL_ "GenSigTimeoutTime" BU_SG_REL_ WRCS SG_ 2432687168 CabExtraSideWrknLightFdbk_stat_I 120;
BA_REL_ "GenSigFirstTimeoutTime" BU_SG_REL_ WRCS SG_ 2432687168 Pto2Status_ISig_5 3000;
BA_REL_ "GenSigTimeoutTime" BU_SG_REL_ WRCS SG_ 2432687168 Pto2Status_ISig_5 120;
BA_REL_ "GenSigFirstTimeoutTime" BU_SG_REL_ WRCS SG_ 2432687168 CabBeaconLightFeedback_Status_IS 3000;
BA_REL_ "GenSigTimeoutTime" BU_SG_REL_ WRCS SG_ 2432687168 CabBeaconLightFeedback_Status_IS 120;
BA_REL_ "GenSigFirstTimeoutTime" BU_SG_REL_ LECM1 SG_ 2432687168 AudioSourceStatus_ISig_5 3000;
BA_REL_ "GenSigTimeoutTime" BU_SG_REL_ LECM1 SG_ 2432687168 AudioSourceStatus_ISig_5 120;
BA_REL_ "GenSigFirstTimeoutTime" BU_SG_REL_ WRCS SG_ 2432687168 Pto4Status_ISig_5 3000;
BA_REL_ "GenSigTimeoutTime" BU_SG_REL_ WRCS SG_ 2432687168 Pto4Status_ISig_5 120;
BA_REL_ "GenSigFirstTimeoutTime" BU_SG_REL_ CCM SG_ 2550121792 DayLocal_ISig_5 6000;
BA_REL_ "GenSigTimeoutTime" BU_SG_REL_ CCM SG_ 2550121792 DayLocal_ISig_5 1500;
BA_REL_ "GenSigFirstTimeoutTime" BU_SG_REL_ CCM SG_ 2550121792 SecondsLocal_ISig_5 6000;
BA_REL_ "GenSigTimeoutTime" BU_SG_REL_ CCM SG_ 2550121792 SecondsLocal_ISig_5 1500;
BA_REL_ "GenSigFirstTimeoutTime" BU_SG_REL_ CCM SG_ 2550121792 YearLocal_ISig_5 6000;
BA_REL_ "GenSigTimeoutTime" BU_SG_REL_ CCM SG_ 2550121792 YearLocal_ISig_5 1500;
BA_REL_ "GenSigFirstTimeoutTime" BU_SG_REL_ CCM SG_ 2550121792 MinutesLocal_ISig_5 6000;
BA_REL_ "GenSigTimeoutTime" BU_SG_REL_ CCM SG_ 2550121792 MinutesLocal_ISig_5 1500;
BA_REL_ "GenSigFirstTimeoutTime" BU_SG_REL_ LECM1 SG_ 2550121792 MinutesLocal_ISig_5 6000;
BA_REL_ "GenSigTimeoutTime" BU_SG_REL_ LECM1 SG_ 2550121792 MinutesLocal_ISig_5 1500;
BA_REL_ "GenSigFirstTimeoutTime" BU_SG_REL_ CCM SG_ 2550121792 BatterySOCAlertRawData_rqst_ISig 6000;
BA_REL_ "GenSigTimeoutTime" BU_SG_REL_ CCM SG_ 2550121792 BatterySOCAlertRawData_rqst_ISig 1500;
BA_REL_ "GenSigFirstTimeoutTime" BU_SG_REL_ CCM SG_ 2550121792 HoursLocal_ISig_5 6000;
BA_REL_ "GenSigTimeoutTime" BU_SG_REL_ CCM SG_ 2550121792 HoursLocal_ISig_5 1500;
BA_REL_ "GenSigFirstTimeoutTime" BU_SG_REL_ LECM1 SG_ 2550121792 HoursLocal_ISig_5 6000;
BA_REL_ "GenSigTimeoutTime" BU_SG_REL_ LECM1 SG_ 2550121792 HoursLocal_ISig_5 1500;
BA_REL_ "GenSigFirstTimeoutTime" BU_SG_REL_ CCM SG_ 2550121792 MonthLocal_ISig_5 6000;
BA_REL_ "GenSigTimeoutTime" BU_SG_REL_ CCM SG_ 2550121792 MonthLocal_ISig_5 1500;
BA_REL_ "GenSigFirstTimeoutTime" BU_SG_REL_ LECM1 SG_ 2550115648 YearUTC_ISig_5 6000;
BA_REL_ "GenSigTimeoutTime" BU_SG_REL_ LECM1 SG_ 2550115648 YearUTC_ISig_5 1500;
BA_REL_ "GenSigFirstTimeoutTime" BU_SG_REL_ WRCS SG_ 2550115648 YearUTC_ISig_5 6000;
BA_REL_ "GenSigTimeoutTime" BU_SG_REL_ WRCS SG_ 2550115648 YearUTC_ISig_5 1500;
BA_REL_ "GenSigFirstTimeoutTime" BU_SG_REL_ SRS SG_ 2550115648 YearUTC_ISig_5 6000;
BA_REL_ "GenSigTimeoutTime" BU_SG_REL_ SRS SG_ 2550115648 YearUTC_ISig_5 1500;
BA_REL_ "GenSigFirstTimeoutTime" BU_SG_REL_ CCM SG_ 2550115648 YearUTC_ISig_5 6000;
BA_REL_ "GenSigTimeoutTime" BU_SG_REL_ CCM SG_ 2550115648 YearUTC_ISig_5 1500;
BA_REL_ "GenSigFirstTimeoutTime" BU_SG_REL_ LECM1 SG_ 2550115648 SecondsUTC_ISig_5 6000;
BA_REL_ "GenSigTimeoutTime" BU_SG_REL_ LECM1 SG_ 2550115648 SecondsUTC_ISig_5 1500;
BA_REL_ "GenSigFirstTimeoutTime" BU_SG_REL_ WRCS SG_ 2550115648 SecondsUTC_ISig_5 6000;
BA_REL_ "GenSigTimeoutTime" BU_SG_REL_ WRCS SG_ 2550115648 SecondsUTC_ISig_5 1500;
BA_REL_ "GenSigFirstTimeoutTime" BU_SG_REL_ CCM SG_ 2550115648 SecondsUTC_ISig_5 6000;
BA_REL_ "GenSigTimeoutTime" BU_SG_REL_ CCM SG_ 2550115648 SecondsUTC_ISig_5 1500;
BA_REL_ "GenSigFirstTimeoutTime" BU_SG_REL_ SRS SG_ 2550115648 SecondsUTC_ISig_5 6000;
BA_REL_ "GenSigTimeoutTime" BU_SG_REL_ SRS SG_ 2550115648 SecondsUTC_ISig_5 1500;
BA_REL_ "GenSigFirstTimeoutTime" BU_SG_REL_ WRCS SG_ 2550115648 DayUTC_ISig_5 6000;
BA_REL_ "GenSigTimeoutTime" BU_SG_REL_ WRCS SG_ 2550115648 DayUTC_ISig_5 1500;
BA_REL_ "GenSigFirstTimeoutTime" BU_SG_REL_ SRS SG_ 2550115648 DayUTC_ISig_5 6000;
BA_REL_ "GenSigTimeoutTime" BU_SG_REL_ SRS SG_ 2550115648 DayUTC_ISig_5 1500;
BA_REL_ "GenSigFirstTimeoutTime" BU_SG_REL_ LECM1 SG_ 2550115648 DayUTC_ISig_5 6000;
BA_REL_ "GenSigTimeoutTime" BU_SG_REL_ LECM1 SG_ 2550115648 DayUTC_ISig_5 1500;
BA_REL_ "GenSigFirstTimeoutTime" BU_SG_REL_ CCM SG_ 2550115648 DayUTC_ISig_5 6000;
BA_REL_ "GenSigTimeoutTime" BU_SG_REL_ CCM SG_ 2550115648 DayUTC_ISig_5 1500;
BA_REL_ "GenSigFirstTimeoutTime" BU_SG_REL_ LECM1 SG_ 2550115648 MinutesUTC_ISig_5 6000;
BA_REL_ "GenSigTimeoutTime" BU_SG_REL_ LECM1 SG_ 2550115648 MinutesUTC_ISig_5 1500;
BA_REL_ "GenSigFirstTimeoutTime" BU_SG_REL_ CCM SG_ 2550115648 MinutesUTC_ISig_5 6000;
BA_REL_ "GenSigTimeoutTime" BU_SG_REL_ CCM SG_ 2550115648 MinutesUTC_ISig_5 1500;
BA_REL_ "GenSigFirstTimeoutTime" BU_SG_REL_ WRCS SG_ 2550115648 MinutesUTC_ISig_5 6000;
BA_REL_ "GenSigTimeoutTime" BU_SG_REL_ WRCS SG_ 2550115648 MinutesUTC_ISig_5 1500;
BA_REL_ "GenSigFirstTimeoutTime" BU_SG_REL_ SRS SG_ 2550115648 MinutesUTC_ISig_5 6000;
BA_REL_ "GenSigTimeoutTime" BU_SG_REL_ SRS SG_ 2550115648 MinutesUTC_ISig_5 1500;
BA_REL_ "GenSigFirstTimeoutTime" BU_SG_REL_ LECM1 SG_ 2550115648 HoursUTC_ISig_5 6000;
BA_REL_ "GenSigTimeoutTime" BU_SG_REL_ LECM1 SG_ 2550115648 HoursUTC_ISig_5 1500;
BA_REL_ "GenSigFirstTimeoutTime" BU_SG_REL_ WRCS SG_ 2550115648 HoursUTC_ISig_5 6000;
BA_REL_ "GenSigTimeoutTime" BU_SG_REL_ WRCS SG_ 2550115648 HoursUTC_ISig_5 1500;
BA_REL_ "GenSigFirstTimeoutTime" BU_SG_REL_ SRS SG_ 2550115648 HoursUTC_ISig_5 6000;
BA_REL_ "GenSigTimeoutTime" BU_SG_REL_ SRS SG_ 2550115648 HoursUTC_ISig_5 1500;
BA_REL_ "GenSigFirstTimeoutTime" BU_SG_REL_ CCM SG_ 2550115648 HoursUTC_ISig_5 6000;
BA_REL_ "GenSigTimeoutTime" BU_SG_REL_ CCM SG_ 2550115648 HoursUTC_ISig_5 1500;
BA_REL_ "GenSigFirstTimeoutTime" BU_SG_REL_ WRCS SG_ 2550115648 MonthUTC_ISig_5 6000;
BA_REL_ "GenSigTimeoutTime" BU_SG_REL_ WRCS SG_ 2550115648 MonthUTC_ISig_5 1500;
BA_REL_ "GenSigFirstTimeoutTime" BU_SG_REL_ SRS SG_ 2550115648 MonthUTC_ISig_5 6000;
BA_REL_ "GenSigTimeoutTime" BU_SG_REL_ SRS SG_ 2550115648 MonthUTC_ISig_5 1500;
BA_REL_ "GenSigFirstTimeoutTime" BU_SG_REL_ CCM SG_ 2550115648 MonthUTC_ISig_5 6000;
BA_REL_ "GenSigTimeoutTime" BU_SG_REL_ CCM SG_ 2550115648 MonthUTC_ISig_5 1500;
BA_REL_ "GenSigFirstTimeoutTime" BU_SG_REL_ LECM1 SG_ 2550115648 MonthUTC_ISig_5 6000;
BA_REL_ "GenSigTimeoutTime" BU_SG_REL_ LECM1 SG_ 2550115648 MonthUTC_ISig_5 1500;
BA_REL_ "GenSigFirstTimeoutTime" BU_SG_REL_ WRCS SG_ 2432669248 AuxSwitchBbLoad2_Status_ISig_5 3000;
BA_REL_ "GenSigTimeoutTime" BU_SG_REL_ WRCS SG_ 2432669248 AuxSwitchBbLoad2_Status_ISig_5 120;
BA_REL_ "GenSigFirstTimeoutTime" BU_SG_REL_ LECM1 SG_ 2432669248 DoorLock_stat_ISig_5 3000;
BA_REL_ "GenSigTimeoutTime" BU_SG_REL_ LECM1 SG_ 2432669248 DoorLock_stat_ISig_5 120;
BA_REL_ "GenSigFirstTimeoutTime" BU_SG_REL_ WRCS SG_ 2432669248 DoorLock_stat_ISig_5 3000;
BA_REL_ "GenSigTimeoutTime" BU_SG_REL_ WRCS SG_ 2432669248 DoorLock_stat_ISig_5 120;
BA_REL_ "GenSigFirstTimeoutTime" BU_SG_REL_ CCM SG_ 2432669248 MirrorHeatNormalModeInd_cmd_2_IS 3000;
BA_REL_ "GenSigTimeoutTime" BU_SG_REL_ CCM SG_ 2432669248 MirrorHeatNormalModeInd_cmd_2_IS 120;
BA_REL_ "GenSigFirstTimeoutTime" BU_SG_REL_ CCM SG_ 2432669248 PSWindowPosition_ISig_5 3000;
BA_REL_ "GenSigTimeoutTime" BU_SG_REL_ CCM SG_ 2432669248 PSWindowPosition_ISig_5 120;
BA_REL_ "GenSigFirstTimeoutTime" BU_SG_REL_ WRCS SG_ 2432669248 AuxSwitchBbLoad1_Status_ISig_5 3000;
BA_REL_ "GenSigTimeoutTime" BU_SG_REL_ WRCS SG_ 2432669248 AuxSwitchBbLoad1_Status_ISig_5 120;
BA_REL_ "GenSigFirstTimeoutTime" BU_SG_REL_ CCM SG_ 2432669248 ReducedLoadMode_stat_ISig_5 3000;
BA_REL_ "GenSigTimeoutTime" BU_SG_REL_ CCM SG_ 2432669248 ReducedLoadMode_stat_ISig_5 120;
BA_REL_ "GenSigFirstTimeoutTime" BU_SG_REL_ WRCS SG_ 2432669248 TrailersConnected_ISig_5 3000;
BA_REL_ "GenSigTimeoutTime" BU_SG_REL_ WRCS SG_ 2432669248 TrailersConnected_ISig_5 120;
BA_REL_ "GenSigFirstTimeoutTime" BU_SG_REL_ CCM SG_ 2432669248 DriverDoorAjar_stat_ISig_5 3000;
BA_REL_ "GenSigTimeoutTime" BU_SG_REL_ CCM SG_ 2432669248 DriverDoorAjar_stat_ISig_5 120;
BA_REL_ "GenSigFirstTimeoutTime" BU_SG_REL_ WRCS SG_ 2432669248 AuxSwitchBbLoad6_Status_ISig_5 3000;
BA_REL_ "GenSigTimeoutTime" BU_SG_REL_ WRCS SG_ 2432669248 AuxSwitchBbLoad6_Status_ISig_5 120;
BA_REL_ "GenSigFirstTimeoutTime" BU_SG_REL_ LECM1 SG_ 2432669248 BunkBacklightCmd_ISig_5 3000;
BA_REL_ "GenSigTimeoutTime" BU_SG_REL_ LECM1 SG_ 2432669248 BunkBacklightCmd_ISig_5 120;
BA_REL_ "GenSigFirstTimeoutTime" BU_SG_REL_ WRCS SG_ 2432669248 AuxSwitchBbLoad4_Status_ISig_5 3000;
BA_REL_ "GenSigTimeoutTime" BU_SG_REL_ WRCS SG_ 2432669248 AuxSwitchBbLoad4_Status_ISig_5 120;
BA_REL_ "GenSigFirstTimeoutTime" BU_SG_REL_ CCM SG_ 2432669248 DSWindowPosition_ISig_5 3000;
BA_REL_ "GenSigTimeoutTime" BU_SG_REL_ CCM SG_ 2432669248 DSWindowPosition_ISig_5 120;
BA_REL_ "GenSigFirstTimeoutTime" BU_SG_REL_ LECM1 SG_ 2432669248 SelectedLanguage_stat_ISig_5 3000;
BA_REL_ "GenSigTimeoutTime" BU_SG_REL_ LECM1 SG_ 2432669248 SelectedLanguage_stat_ISig_5 120;
BA_REL_ "GenSigFirstTimeoutTime" BU_SG_REL_ WRCS SG_ 2432669248 SelectedLanguage_stat_ISig_5 3000;
BA_REL_ "GenSigTimeoutTime" BU_SG_REL_ WRCS SG_ 2432669248 SelectedLanguage_stat_ISig_5 120;
BA_REL_ "GenSigFirstTimeoutTime" BU_SG_REL_ CCM SG_ 2432669248 PassengerDoorAjar_stat_ISig_5 3000;
BA_REL_ "GenSigTimeoutTime" BU_SG_REL_ CCM SG_ 2432669248 PassengerDoorAjar_stat_ISig_5 120;
BA_REL_ "GenSigFirstTimeoutTime" BU_SG_REL_ CCM SG_ 2432669248 BunkB1ParkHeaterTempSw_stat 3000;
BA_REL_ "GenSigTimeoutTime" BU_SG_REL_ CCM SG_ 2432669248 BunkB1ParkHeaterTempSw_stat 120;
BA_REL_ "GenSigFirstTimeoutTime" BU_SG_REL_ WRCS SG_ 2432669248 AuxSwitchBbLoad5_Status_ISig_5 3000;
BA_REL_ "GenSigTimeoutTime" BU_SG_REL_ WRCS SG_ 2432669248 AuxSwitchBbLoad5_Status_ISig_5 120;
BA_REL_ "GenSigFirstTimeoutTime" BU_SG_REL_ LECM1 SG_ 2432669248 AudioVolumeIndicationCmd_ISig_5 3000;
BA_REL_ "GenSigTimeoutTime" BU_SG_REL_ LECM1 SG_ 2432669248 AudioVolumeIndicationCmd_ISig_5 120;
BA_REL_ "GenSigFirstTimeoutTime" BU_SG_REL_ WRCS SG_ 2432669248 AuxSwitchBbLoad3_Status_ISig_5 3000;
BA_REL_ "GenSigTimeoutTime" BU_SG_REL_ WRCS SG_ 2432669248 AuxSwitchBbLoad3_Status_ISig_5 120;
BA_REL_ "GenSigFirstTimeoutTime" BU_SG_REL_ CCM SG_ 2432669248 BunkH2TempInc_ButtonStatus 3000;
BA_REL_ "GenSigTimeoutTime" BU_SG_REL_ CCM SG_ 2432669248 BunkH2TempInc_ButtonStatus 120;
BA_REL_ "GenSigFirstTimeoutTime" BU_SG_REL_ CCM SG_ 2432669248 DayOfWeek_stat_ISig_5 3000;
BA_REL_ "GenSigTimeoutTime" BU_SG_REL_ CCM SG_ 2432669248 DayOfWeek_stat_ISig_5 120;
BA_REL_ "GenSigFirstTimeoutTime" BU_SG_REL_ LECM1 SG_ 2432669248 DayOfWeek_stat_ISig_5 3000;
BA_REL_ "GenSigTimeoutTime" BU_SG_REL_ LECM1 SG_ 2432669248 DayOfWeek_stat_ISig_5 120;
VAL_ 2566356800 PHTimerTGWEvCmd_Timer3Recur_ISig 15 "HeaterTimerRecurrence_NotAvailable" 14 "HeaterTimerRecurrence_Error" 13 "HeaterTimerRecurrence_Spare_3" 12 "HeaterTimerRecurrence_Spare_2" 11 "HeaterTimerRecurrence_Spare_1" 10 "HeaterTimerRecurrence_Sundays" 9 "HeaterTimerRecurrence_Saturdays" 8 "HeaterTimerRecurrence_Fridays" 7 "HeaterTimerRecurrence_Thursdays" 6 "HeaterTimerRecurrence_Wednesdays" 5 "HeaterTimerRecurrence_Tuesdays" 4 "HeaterTimerRecurrence_Mondays" 3 "HeaterTimerRecurrence_Weekends" 2 "HeaterTimerRecurrence_AllWeekdays" 1 "HeaterTimerRecurrence_Daily" 0 "HeaterTimerRecurrence_None" ;
VAL_ 2566356800 PHTimerTGWEvCmd_PhTimer1_cmd_ISi 7 "PhTimer_cmd_NotAvailable" 6 "PhTimer_cmd_Error" 5 "PhTimer_cmd_Spare_02" 4 "PhTimer_cmd_Spare_01" 3 "PhTimer_cmd_TimerDeleted" 2 "PhTimer_cmd_TimerDisable" 1 "PhTimer_cmd_TimerEnable" 0 "PhTimer_cmd_NoAction" ;
VAL_ 2566356800 PHTimerTGWEvCmd_Timer3StartDay_I 15 "HeaterTimerStartDay_NotAvailable" 14 "HeaterTimerStartDay_Error" 13 "HeaterTimerStartDay_Spare_05" 12 "HeaterTimerStartDay_Spare_04" 11 "HeaterTimerStartDay_Spare_03" 10 "HeaterTimerStartDay_Spare_02" 9 "HeaterTimerStartDay_Spare_01" 8 "HeaterTimerStartDay_Spare" 7 "HeaterTimerStartDay_Sunday" 6 "HeaterTimerStartDay_Saturday" 5 "HeaterTimerStartDay_Friday" 4 "HeaterTimerStartDay_Thursday" 3 "HeaterTimerStartDay_Wednesday" 2 "HeaterTimerStartDay_Tuesday" 1 "HeaterTimerStartDay_Monday" 0 "HeaterTimerStartDay_NotUsed" ;
VAL_ 2566356800 PHTimerTGWEvCmd_Timer1Temp_ISig_ 31 "TemperatureRqstIndication_cmd_NotAvailable" 30 "TemperatureRqstIndication_cmd_Error" 29 "TemperatureRqstIndication_cmd_Spare_01" 28 "TemperatureRqstIndication_cmd_Spare" 27 "TemperatureRqstIndication_cmd_Max" 26 "TemperatureRqstIndication_cmd_29C" 25 "TemperatureRqstIndication_cmd_28C" 24 "TemperatureRqstIndication_cmd_27C" 23 "TemperatureRqstIndication_cmd_26C" 22 "TemperatureRqstIndication_cmd_25_5C" 21 "TemperatureRqstIndication_cmd_25C" 20 "TemperatureRqstIndication_cmd_24_5C" 19 "TemperatureRqstIndication_cmd_24C" 18 "TemperatureRqstIndication_cmd_23_5C" 17 "TemperatureRqstIndication_cmd_23C" 16 "TemperatureRqstIndication_cmd_22_5C" 15 "TemperatureRqstIndication_cmd_22C" 14 "TemperatureRqstIndication_cmd_21_5C" 13 "TemperatureRqstIndication_cmd_21C" 12 "TemperatureRqstIndication_cmd_20_5C" 11 "TemperatureRqstIndication_cmd_20C" 10 "TemperatureRqstIndication_cmd_19_5C" 9 "TemperatureRqstIndication_cmd_19C" 8 "TemperatureRqstIndication_cmd_18_5C" 7 "TemperatureRqstIndication_cmd_18C" 6 "TemperatureRqstIndication_cmd_17_5C" 5 "TemperatureRqstIndication_cmd_17C" 4 "TemperatureRqstIndication_cmd_16_5C" 3 "TemperatureRqstIndication_cmd_16C" 2 "TemperatureRqstIndication_cmd_15C" 1 "TemperatureRqstIndication_cmd_Min" 0 "TemperatureRqstIndication_cmd_NoTempDisplayed" ;
VAL_ 2566356800 PHTimerTGWEvCmd_Timer2StartDay_I 15 "HeaterTimerStartDay_NotAvailable" 14 "HeaterTimerStartDay_Error" 13 "HeaterTimerStartDay_Spare_05" 12 "HeaterTimerStartDay_Spare_04" 11 "HeaterTimerStartDay_Spare_03" 10 "HeaterTimerStartDay_Spare_02" 9 "HeaterTimerStartDay_Spare_01" 8 "HeaterTimerStartDay_Spare" 7 "HeaterTimerStartDay_Sunday" 6 "HeaterTimerStartDay_Saturday" 5 "HeaterTimerStartDay_Friday" 4 "HeaterTimerStartDay_Thursday" 3 "HeaterTimerStartDay_Wednesday" 2 "HeaterTimerStartDay_Tuesday" 1 "HeaterTimerStartDay_Monday" 0 "HeaterTimerStartDay_NotUsed" ;
VAL_ 2566356800 PHTimerTGWEvCmd_PhTimer2_cmd_ISi 7 "PhTimer_cmd_NotAvailable" 6 "PhTimer_cmd_Error" 5 "PhTimer_cmd_Spare_02" 4 "PhTimer_cmd_Spare_01" 3 "PhTimer_cmd_TimerDeleted" 2 "PhTimer_cmd_TimerDisable" 1 "PhTimer_cmd_TimerEnable" 0 "PhTimer_cmd_NoAction" ;
VAL_ 2566356800 PHTimerTGWEvCmd_Timer2Temp_ISig_ 31 "TemperatureRqstIndication_cmd_NotAvailable" 30 "TemperatureRqstIndication_cmd_Error" 29 "TemperatureRqstIndication_cmd_Spare_01" 28 "TemperatureRqstIndication_cmd_Spare" 27 "TemperatureRqstIndication_cmd_Max" 26 "TemperatureRqstIndication_cmd_29C" 25 "TemperatureRqstIndication_cmd_28C" 24 "TemperatureRqstIndication_cmd_27C" 23 "TemperatureRqstIndication_cmd_26C" 22 "TemperatureRqstIndication_cmd_25_5C" 21 "TemperatureRqstIndication_cmd_25C" 20 "TemperatureRqstIndication_cmd_24_5C" 19 "TemperatureRqstIndication_cmd_24C" 18 "TemperatureRqstIndication_cmd_23_5C" 17 "TemperatureRqstIndication_cmd_23C" 16 "TemperatureRqstIndication_cmd_22_5C" 15 "TemperatureRqstIndication_cmd_22C" 14 "TemperatureRqstIndication_cmd_21_5C" 13 "TemperatureRqstIndication_cmd_21C" 12 "TemperatureRqstIndication_cmd_20_5C" 11 "TemperatureRqstIndication_cmd_20C" 10 "TemperatureRqstIndication_cmd_19_5C" 9 "TemperatureRqstIndication_cmd_19C" 8 "TemperatureRqstIndication_cmd_18_5C" 7 "TemperatureRqstIndication_cmd_18C" 6 "TemperatureRqstIndication_cmd_17_5C" 5 "TemperatureRqstIndication_cmd_17C" 4 "TemperatureRqstIndication_cmd_16_5C" 3 "TemperatureRqstIndication_cmd_16C" 2 "TemperatureRqstIndication_cmd_15C" 1 "TemperatureRqstIndication_cmd_Min" 0 "TemperatureRqstIndication_cmd_NoTempDisplayed" ;
VAL_ 2566356800 PHTimerTGWEvCmd_Timer1StartDay_I 15 "HeaterTimerStartDay_NotAvailable" 14 "HeaterTimerStartDay_Error" 13 "HeaterTimerStartDay_Spare_05" 12 "HeaterTimerStartDay_Spare_04" 11 "HeaterTimerStartDay_Spare_03" 10 "HeaterTimerStartDay_Spare_02" 9 "HeaterTimerStartDay_Spare_01" 8 "HeaterTimerStartDay_Spare" 7 "HeaterTimerStartDay_Sunday" 6 "HeaterTimerStartDay_Saturday" 5 "HeaterTimerStartDay_Friday" 4 "HeaterTimerStartDay_Thursday" 3 "HeaterTimerStartDay_Wednesday" 2 "HeaterTimerStartDay_Tuesday" 1 "HeaterTimerStartDay_Monday" 0 "HeaterTimerStartDay_NotUsed" ;
VAL_ 2566356800 PHTimerTGWEvCmd_Timer1Recur_ISig 15 "HeaterTimerRecurrence_NotAvailable" 14 "HeaterTimerRecurrence_Error" 13 "HeaterTimerRecurrence_Spare_3" 12 "HeaterTimerRecurrence_Spare_2" 11 "HeaterTimerRecurrence_Spare_1" 10 "HeaterTimerRecurrence_Sundays" 9 "HeaterTimerRecurrence_Saturdays" 8 "HeaterTimerRecurrence_Fridays" 7 "HeaterTimerRecurrence_Thursdays" 6 "HeaterTimerRecurrence_Wednesdays" 5 "HeaterTimerRecurrence_Tuesdays" 4 "HeaterTimerRecurrence_Mondays" 3 "HeaterTimerRecurrence_Weekends" 2 "HeaterTimerRecurrence_AllWeekdays" 1 "HeaterTimerRecurrence_Daily" 0 "HeaterTimerRecurrence_None" ;
VAL_ 2566356800 PHTimerTGWEvCmd_Timer2Recur_ISig 15 "HeaterTimerRecurrence_NotAvailable" 14 "HeaterTimerRecurrence_Error" 13 "HeaterTimerRecurrence_Spare_3" 12 "HeaterTimerRecurrence_Spare_2" 11 "HeaterTimerRecurrence_Spare_1" 10 "HeaterTimerRecurrence_Sundays" 9 "HeaterTimerRecurrence_Saturdays" 8 "HeaterTimerRecurrence_Fridays" 7 "HeaterTimerRecurrence_Thursdays" 6 "HeaterTimerRecurrence_Wednesdays" 5 "HeaterTimerRecurrence_Tuesdays" 4 "HeaterTimerRecurrence_Mondays" 3 "HeaterTimerRecurrence_Weekends" 2 "HeaterTimerRecurrence_AllWeekdays" 1 "HeaterTimerRecurrence_Daily" 0 "HeaterTimerRecurrence_None" ;
VAL_ 2566356800 PHTimerTGWEvCmd_PhTimer3_cmd_ISi 7 "PhTimer_cmd_NotAvailable" 6 "PhTimer_cmd_Error" 5 "PhTimer_cmd_Spare_02" 4 "PhTimer_cmd_Spare_01" 3 "PhTimer_cmd_TimerDeleted" 2 "PhTimer_cmd_TimerDisable" 1 "PhTimer_cmd_TimerEnable" 0 "PhTimer_cmd_NoAction" ;
VAL_ 2566356800 PHTimerTGWEvCmd_Timer3Temp_ISig_ 31 "TemperatureRqstIndication_cmd_NotAvailable" 30 "TemperatureRqstIndication_cmd_Error" 29 "TemperatureRqstIndication_cmd_Spare_01" 28 "TemperatureRqstIndication_cmd_Spare" 27 "TemperatureRqstIndication_cmd_Max" 26 "TemperatureRqstIndication_cmd_29C" 25 "TemperatureRqstIndication_cmd_28C" 24 "TemperatureRqstIndication_cmd_27C" 23 "TemperatureRqstIndication_cmd_26C" 22 "TemperatureRqstIndication_cmd_25_5C" 21 "TemperatureRqstIndication_cmd_25C" 20 "TemperatureRqstIndication_cmd_24_5C" 19 "TemperatureRqstIndication_cmd_24C" 18 "TemperatureRqstIndication_cmd_23_5C" 17 "TemperatureRqstIndication_cmd_23C" 16 "TemperatureRqstIndication_cmd_22_5C" 15 "TemperatureRqstIndication_cmd_22C" 14 "TemperatureRqstIndication_cmd_21_5C" 13 "TemperatureRqstIndication_cmd_21C" 12 "TemperatureRqstIndication_cmd_20_5C" 11 "TemperatureRqstIndication_cmd_20C" 10 "TemperatureRqstIndication_cmd_19_5C" 9 "TemperatureRqstIndication_cmd_19C" 8 "TemperatureRqstIndication_cmd_18_5C" 7 "TemperatureRqstIndication_cmd_18C" 6 "TemperatureRqstIndication_cmd_17_5C" 5 "TemperatureRqstIndication_cmd_17C" 4 "TemperatureRqstIndication_cmd_16_5C" 3 "TemperatureRqstIndication_cmd_16C" 2 "TemperatureRqstIndication_cmd_15C" 1 "TemperatureRqstIndication_cmd_Min" 0 "TemperatureRqstIndication_cmd_NoTempDisplayed" ;
VAL_ 2516128064 Trailer4LiftAxles_LiftAxle1Pos_I 3 "TrailerLiftAxlePos_NotAvailable" 2 "TrailerLiftAxlePos_Error" 1 "TrailerLiftAxlePos_AxleLifted" 0 "TrailerLiftAxlePos_AxleDown" ;
VAL_ 2516128064 Trailer2LiftAxles_LiftAxle1Pos_I 3 "TrailerLiftAxlePos_NotAvailable" 2 "TrailerLiftAxlePos_Error" 1 "TrailerLiftAxlePos_AxleLifted" 0 "TrailerLiftAxlePos_AxleDown" ;
VAL_ 2516128064 Trailer2LiftAxles_LiftAxle2Pos_I 3 "TrailerLiftAxlePos_NotAvailable" 2 "TrailerLiftAxlePos_Error" 1 "TrailerLiftAxlePos_AxleLifted" 0 "TrailerLiftAxlePos_AxleDown" ;
VAL_ 2516128064 Trailer4LiftAxles_LiftAxle2Pos_I 3 "TrailerLiftAxlePos_NotAvailable" 2 "TrailerLiftAxlePos_Error" 1 "TrailerLiftAxlePos_AxleLifted" 0 "TrailerLiftAxlePos_AxleDown" ;
VAL_ 2516128064 Trailer5LiftAxles_LiftAxle1Pos_I 3 "TrailerLiftAxlePos_NotAvailable" 2 "TrailerLiftAxlePos_Error" 1 "TrailerLiftAxlePos_AxleLifted" 0 "TrailerLiftAxlePos_AxleDown" ;
VAL_ 2516128064 Trailer3LiftAxles_LiftAxle1Pos_I 3 "TrailerLiftAxlePos_NotAvailable" 2 "TrailerLiftAxlePos_Error" 1 "TrailerLiftAxlePos_AxleLifted" 0 "TrailerLiftAxlePos_AxleDown" ;
VAL_ 2516128064 Trailer1LiftAxles_LiftAxle2Pos_I 3 "TrailerLiftAxlePos_NotAvailable" 2 "TrailerLiftAxlePos_Error" 1 "TrailerLiftAxlePos_AxleLifted" 0 "TrailerLiftAxlePos_AxleDown" ;
VAL_ 2516128064 Trailer5LiftAxles_LiftAxle2Pos_I 3 "TrailerLiftAxlePos_NotAvailable" 2 "TrailerLiftAxlePos_Error" 1 "TrailerLiftAxlePos_AxleLifted" 0 "TrailerLiftAxlePos_AxleDown" ;
VAL_ 2516128064 Trailer1LiftAxles_LiftAxle1Pos_I 3 "TrailerLiftAxlePos_NotAvailable" 2 "TrailerLiftAxlePos_Error" 1 "TrailerLiftAxlePos_AxleLifted" 0 "TrailerLiftAxlePos_AxleDown" ;
VAL_ 2516128064 Trailer3LiftAxles_LiftAxle2Pos_I 3 "TrailerLiftAxlePos_NotAvailable" 2 "TrailerLiftAxlePos_Error" 1 "TrailerLiftAxlePos_AxleLifted" 0 "TrailerLiftAxlePos_AxleDown" ;
VAL_ 2499679296 AudioMuteStat_ISig_5 7 "AudioMute_NotAvailable" 6 "AudioMute_ErrorIndication" 5 "AudioMute_Spare_03" 4 "AudioMute_Spare_02" 3 "AudioMute_Spare_01" 2 "AudioMute_Spare" 1 "AudioMute_Mute" 0 "AudioMute_Off" ;
VAL_ 2499679296 LoadDistributionSelected_ISig_5 15 "LoadDistributionSelected_NotAvailable" 14 "LoadDistributionSelected_Error" 13 "LoadDistributionSelected_Reserved_05" 12 "LoadDistributionSelected_Reserved_04" 11 "LoadDistributionSelected_Reserved_03" 10 "LoadDistributionSelected_TractionHelp2" 9 "LoadDistributionSelected_StartingHelp2" 8 "LoadDistributionSelected_VariableAxleLoad" 7 "LoadDistributionSelected_NoLoadDistribution" 6 "LoadDistributionSelected_TractionHelpInterDiff" 5 "LoadDistributionSelected_StartingHelpInterDiff" 4 "LoadDistributionSelected_AlternativeLoad" 3 "LoadDistributionSelected_TractionHelp" 2 "LoadDistributionSelected_StartingHelp" 1 "LoadDistributionSelected_OptimisedTraction" 0 "LoadDistributionSelected_NormalLoad" ;
VAL_ 2499679296 PHTimerRqstAck_DayOfWeekRq_ISig_ 15 "DayOfWeekRq_NotAvailable" 14 "DayOfWeekRq_Error" 13 "DayOfWeekRq_Spare_7" 12 "DayOfWeekRq_Spare_6" 11 "DayOfWeekRq_Spare_5" 10 "DayOfWeekRq_Spare_4" 9 "DayOfWeekRq_Spare_3" 8 "DayOfWeekRq_Spare_2" 7 "DayOfWeekRq_NoDay" 6 "DayOfWeekRq_Sunday" 5 "DayOfWeekRq_Saturday" 4 "DayOfWeekRq_Friday" 3 "DayOfWeekRq_Thursday" 2 "DayOfWeekRq_Wednesday" 1 "DayOfWeekRq_Tuesday" 0 "DayOfWeekRq_Monday" ;
VAL_ 2499679296 LiftAxle1PositionStatus_ISig_5 7 "LiftAxlePositionStatus_NotAvailable" 6 "LiftAxlePositionStatus_Error" 5 "LiftAxlePositionStatus_Reserved_01" 4 "LiftAxlePositionStatus_Reserved" 3 "LiftAxlePositionStatus_Lifting" 2 "LiftAxlePositionStatus_Lowering" 1 "LiftAxlePositionStatus_Lifted" 0 "LiftAxlePositionStatus_Lowered" ;
VAL_ 2499679296 PHTimerRqstAck_CurrentOp_ISig_5 3 "CurrentOp_NotAvailable" 2 "CurrentOp_Disabled" 1 "CurrentOp_TemporaryStopped" 0 "CurrentOp_Running" ;
VAL_ 2499679296 LiftAxle2PositionStatus_ISig_5 7 "LiftAxlePositionStatus_NotAvailable" 6 "LiftAxlePositionStatus_Error" 5 "LiftAxlePositionStatus_Reserved_01" 4 "LiftAxlePositionStatus_Reserved" 3 "LiftAxlePositionStatus_Lifting" 2 "LiftAxlePositionStatus_Lowering" 1 "LiftAxlePositionStatus_Lifted" 0 "LiftAxlePositionStatus_Lowered" ;
VAL_ 2499679296 ParkingBrake_stat_ISig_5 3 "ParkingBrake_stat_NotAvailable" 2 "ParkingBrake_stat_Error" 1 "ParkingBrake_stat_ParkingBrakeActivated" 0 "ParkingBrake_stat_ParkingBrakeReleased" ;
VAL_ 2549186373 AudioSourceStatus2_ISig_5 15 "AudioSource_stat4bit_NotAvailable" 14 "AudioSource_stat4bit_Error" 13 "AudioSource_stat4bit_Spare7" 12 "AudioSource_stat4bit_Spare6" 11 "AudioSource_stat4bit_Spare5" 10 "AudioSource_stat4bit_Spare4" 9 "AudioSource_stat4bit_Spare3" 8 "AudioSource_stat4bit_Spare2" 7 "AudioSource_stat4bit_Spare1" 6 "AudioSource_stat4bit_BtStream" 5 "AudioSource_stat4bit_AUX1" 4 "AudioSource_stat4bit_IPOD" 3 "AudioSource_stat4bit_AUX2" 2 "AudioSource_stat4bit_USB" 1 "AudioSource_stat4bit_CD" 0 "AudioSource_stat4bit_Radio" ;
VAL_ 2549186373 RemoteParkingClimateRqst_ISig_5 7 "RemoteParkingClimateRqst_NotAvailable" 6 "RemoteParkingClimateRqst_Error" 5 "RemoteParkingClimateRqst_Spare_03" 4 "RemoteParkingClimateRqst_Spare_02" 3 "RemoteParkingClimateRqst_Spare_01" 2 "RemoteParkingClimateRqst_DisableRequest" 1 "RemoteParkingClimateRqst_EnableRequest" 0 "RemoteParkingClimateRqst_NoAction" ;
VAL_ 2549186373 AudioSourceUsbAvailable_ISig_5 3 "FalseTrue_NotAvaiable" 2 "FalseTrue_Error" 1 "FalseTrue_True" 0 "FalseTrue_False" ;
VAL_ 2549186373 AudioSourceBtStreamAvailable_ISi 3 "FalseTrue_NotAvaiable" 2 "FalseTrue_Error" 1 "FalseTrue_True" 0 "FalseTrue_False" ;
VAL_ 2549186373 AudioSourceIpodAvailable_ISig_5 3 "FalseTrue_NotAvaiable" 2 "FalseTrue_Error" 1 "FalseTrue_True" 0 "FalseTrue_False" ;
VAL_ 2549186373 AudioSourceCdAvailable_ISig_5 3 "FalseTrue_NotAvaiable" 2 "FalseTrue_Error" 1 "FalseTrue_True" 0 "FalseTrue_False" ;
VAL_ 2566809599 Trailer5Type_ISig_5 7 "TrailerType_NotAvailable" 6 "TrailerType_Error" 5 "TrailerType_NotConnected" 4 "TrailerType_Unknown" 3 "TrailerType_Dolly" 2 "TrailerType_DrawbarTrailer" 1 "TrailerType_CentreAxleTrailer" 0 "TrailerType_SemiTrailer" ;
VAL_ 2566809599 Trailer2Type_ISig_5 7 "TrailerType_NotAvailable" 6 "TrailerType_Error" 5 "TrailerType_NotConnected" 4 "TrailerType_Unknown" 3 "TrailerType_Dolly" 2 "TrailerType_DrawbarTrailer" 1 "TrailerType_CentreAxleTrailer" 0 "TrailerType_SemiTrailer" ;
VAL_ 2566809599 Trailer4Type_ISig_5 7 "TrailerType_NotAvailable" 6 "TrailerType_Error" 5 "TrailerType_NotConnected" 4 "TrailerType_Unknown" 3 "TrailerType_Dolly" 2 "TrailerType_DrawbarTrailer" 1 "TrailerType_CentreAxleTrailer" 0 "TrailerType_SemiTrailer" ;
VAL_ 2566809599 Trailer1Type_ISig_5 7 "TrailerType_NotAvailable" 6 "TrailerType_Error" 5 "TrailerType_NotConnected" 4 "TrailerType_Unknown" 3 "TrailerType_Dolly" 2 "TrailerType_DrawbarTrailer" 1 "TrailerType_CentreAxleTrailer" 0 "TrailerType_SemiTrailer" ;
VAL_ 2566809599 Trailer3Type_ISig_5 7 "TrailerType_NotAvailable" 6 "TrailerType_Error" 5 "TrailerType_NotConnected" 4 "TrailerType_Unknown" 3 "TrailerType_Dolly" 2 "TrailerType_DrawbarTrailer" 1 "TrailerType_CentreAxleTrailer" 0 "TrailerType_SemiTrailer" ;
VAL_ 2565904383 AlarmClockAlarms_stat_Mode_ISig_ 3 "AlarmClkMode_Spare" 2 "AlarmClkMode_Timer" 1 "AlarmClkMode_Recurrent" 0 "AlarmClkMode_OneTime" ;
VAL_ 2565904383 AlarmClockAlarms_stat_ID_ISig_5 127 "AlarmClkID_NotAvailable" 126 "AlarmClkID_Error" 10 "AlarmClkID_Alarm10" 9 "AlarmClkID_Alarm9" 8 "AlarmClkID_Alarm8" 7 "AlarmClkID_Alarm7" 6 "AlarmClkID_Alarm6" 5 "AlarmClkID_Alarm5" 4 "AlarmClkID_Alarm4" 3 "AlarmClkID_Alarm3" 2 "AlarmClkID_Alarm2" 1 "AlarmClkID_Alarm1" 0 "AlarmClkID_NotUsed" ;
VAL_ 2565904383 AlarmClockNotification_Stat_ISig 3 "AlarmClkStat_Spare" 2 "AlarmClkStat_NoUsed" 1 "AlarmClkStat_Active" 0 "AlarmClkStat_Inactive" ;
VAL_ 2565904383 AlarmClockNotification_Type_ISig 7 "AlarmClkType_NotAvailable" 6 "AlarmClkType_Error" 5 "AlarmClkType_Reserved_02" 4 "AlarmClkType_Reserved_01" 3 "AlarmClkType_Reserved" 2 "AlarmClkType_Radio" 1 "AlarmClkType_Buzzer" 0 "AlarmClkType_NoAudibleNotification" ;
VAL_ 2565904383 ESCReqESC_CtrlTrimReq_ISig_5 7 "CtrlTrimReq_NotAvailable" 6 "CtrlTrimReq_Error" 5 "CtrlTrimReq_Spare_02" 4 "CtrlTrimReq_Spare_01" 3 "CtrlTrimReq_Spare" 2 "CtrlTrimReq_TrimRampDown" 1 "CtrlTrimReq_TrimRampUp" 0 "CtrlTrimReq_NoRamp" ;
VAL_ 2565904383 AlarmClockAlarms_stat_Stat_ISig_ 3 "AlarmClkStat2_Snoozed" 2 "AlarmClkStat2_Ringing" 1 "AlarmClkStat2_Active" 0 "AlarmClkStat2_Inactive" ;
VAL_ 2565904383 ESCReqESC_CtrlTrimMode_ISig_5 15 "CtrlTrimMode_NotAvailable" 14 "CtrlTrimMode_Error" 13 "CtrlTrimMode_Spare_08" 12 "CtrlTrimMode_Spare_07" 11 "CtrlTrimMode_Spare_06" 10 "CtrlTrimMode_Spare_05" 9 "CtrlTrimMode_Spare_04" 8 "CtrlTrimMode_Spare_03" 7 "CtrlTrimMode_Spare_02" 6 "CtrlTrimMode_Spare_01" 5 "CtrlTrimMode_Spare" 4 "CtrlTrimMode_MuddySiteEngineSpeedControl" 3 "CtrlTrimMode_AirManagementEngineSpeedControl" 2 "CtrlTrimMode_IdleAdjust" 1 "CtrlTrimMode_PTOEngineSpeedControl" 0 "CtrlTrimMode_NoRequest" ;
VAL_ 2565904383 ESCReqESC_CtrlTrimStat_ISig_5 7 "CtrlTrimStat_NotAvailable" 6 "CtrlTrimStat_Error" 5 "CtrlTrimStat_Spare_02" 4 "CtrlTrimStat_Spare_01" 3 "CtrlTrimStat_Spare" 2 "CtrlTrimStat_TrimActive" 1 "CtrlTrimStat_ControlActive" 0 "CtrlTrimStat_NoRequestActive" ;
VAL_ 2565904383 AlarmClockAlarms_stat_Type_ISig_ 7 "AlarmClkType_NotAvailable" 6 "AlarmClkType_Error" 5 "AlarmClkType_Reserved_02" 4 "AlarmClkType_Reserved_01" 3 "AlarmClkType_Reserved" 2 "AlarmClkType_Radio" 1 "AlarmClkType_Buzzer" 0 "AlarmClkType_NoAudibleNotification" ;
VAL_ 2565904383 AlarmClockNotification_ID_ISig_5 127 "AlarmClkID_NotAvailable" 126 "AlarmClkID_Error" 10 "AlarmClkID_Alarm10" 9 "AlarmClkID_Alarm9" 8 "AlarmClkID_Alarm8" 7 "AlarmClkID_Alarm7" 6 "AlarmClkID_Alarm6" 5 "AlarmClkID_Alarm5" 4 "AlarmClkID_Alarm4" 3 "AlarmClkID_Alarm3" 2 "AlarmClkID_Alarm2" 1 "AlarmClkID_Alarm1" 0 "AlarmClkID_NotUsed" ;
VAL_ 2499755967 FdEquipmentStatus2_ISig_5 3 "InactiveActive_NotAvailable" 2 "InactiveActive_Error" 1 "InactiveActive_Active" 0 "InactiveActive_Inactive" ;
VAL_ 2499755967 RideHeightStatus_ISig_5 15 "RideHeightStatus_NotAvailable" 14 "RideHeightStatus_ErrorIndicator" 13 "RideHeightStatus_NotDefined_03" 12 "RideHeightStatus_NotDefined_02" 11 "RideHeightStatus_NotDefined_01" 10 "RideHeightStatus_NotDefined" 9 "RideHeightStatus_AlternativeDrivePosition2" 8 "RideHeightStatus_AlternativeDrivePosition1" 7 "RideHeightStatus_AlternativeDrivePosition" 6 "RideHeightStatus_HighDrivePosition" 5 "RideHeightStatus_LowDrivePosition" 4 "RideHeightStatus_SpeedDependentDrivePositionHighSpeed" 3 "RideHeightStatus_SpeedDependentDrivePositionLowSpeed" 2 "RideHeightStatus_StandardUserDrivePosition" 1 "RideHeightStatus_StandardFactoryDrivePosition" 0 "RideHeightStatus_Inactive" ;
VAL_ 2499755967 FdEquipmentStatus4_ISig_5 3 "InactiveActive_NotAvailable" 2 "InactiveActive_Error" 1 "InactiveActive_Active" 0 "InactiveActive_Inactive" ;
VAL_ 2499755967 RideHeightOutsideTargetRange_ISi 7 "HeightOutsideTargetRange_NotAvailable" 6 "HeightOutsideTargetRange_Error" 5 "HeightOutsideTargetRange_NotDefined_02" 4 "HeightOutsideTargetRange_NotDefined_01" 3 "HeightOutsideTargetRange_NotDefined" 2 "HeightOutsideTargetRange_ToHigh" 1 "HeightOutsideTargetRange_ToLow" 0 "HeightOutsideTargetRange_Inactive" ;
VAL_ 2499755967 FdEquipmentStatus1_ISig_5 3 "InactiveActive_NotAvailable" 2 "InactiveActive_Error" 1 "InactiveActive_Active" 0 "InactiveActive_Inactive" ;
VAL_ 2499755967 FdEquipmentStatus5_ISig_5 3 "InactiveActive_NotAvailable" 2 "InactiveActive_Error" 1 "InactiveActive_Active" 0 "InactiveActive_Inactive" ;
VAL_ 2499755967 RideHeightFunctionStatus_ISig_5 15 "RideHeightFunction_NotAvailable" 14 "RideHeightFunction_ErrorIndicator" 13 "RideHeightFunction_NotDefined_05" 12 "RideHeightFunction_NotDefined_04" 11 "RideHeightFunction_NotDefined_03" 10 "RideHeightFunction_NotDefined_02" 9 "RideHeightFunction_NotDefined_01" 8 "RideHeightFunction_NotDefined" 7 "RideHeightFunction_AlternativeDrivePosition2" 6 "RideHeightFunction_AlternativeDrivePosition1" 5 "RideHeightFunction_LowDrivePosition" 4 "RideHeightFunction_HighDrivePosition" 3 "RideHeightFunction_SpeedDependentDrivePosition" 2 "RideHeightFunction_AlternativeDrivePosition" 1 "RideHeightFunction_StandardDrivePosition" 0 "RideHeightFunction_Inactive" ;
VAL_ 2499755967 FdEquipmentStatus3_ISig_5 3 "InactiveActive_NotAvailable" 2 "InactiveActive_Error" 1 "InactiveActive_Active" 0 "InactiveActive_Inactive" ;
VAL_ 2499755967 FrontEndPositionStatus_ISig_5 7 "EndPositionStatus_NotAvailable" 6 "EndPositionStatus_Error" 5 "EndPositionStatus_Reserved_01" 4 "EndPositionStatus_Reserved" 3 "EndPositionStatus_LiftingAndLoweringNotAllowed" 2 "EndPositionStatus_MinEndLevelReached" 1 "EndPositionStatus_MaxEndLevelReached" 0 "EndPositionStatus_NoEndLevelReached" ;
VAL_ 2499755967 RollEndPositionStatus_ISig_5 7 "RollEndPositionStatus_NotAvailable" 6 "RollEndPositionStatus_Error" 5 "RollEndPositionStatus_Reserved_01" 4 "RollEndPositionStatus_Reserved" 3 "RollEndPositionStatus_NoRollingAllowed" 2 "RollEndPositionStatus_CounterClockwiseEndLevelReached" 1 "RollEndPositionStatus_ClockwiseEndLevelReached" 0 "RollEndPositionStatus_NoEndLevelReached" ;
VAL_ 2499755967 RampLevelStatus_ISig_5 15 "RampLevelStatus_NotAvaiable" 14 "RampLevelStatus_ErrorIndicator" 13 "RampLevelStatus_NotDefined_05" 12 "RampLevelStatus_NotDefined_04" 11 "RampLevelStatus_NotDefined_03" 10 "RampLevelStatus_NotDefined_02" 9 "RampLevelStatus_NotDefined_01" 8 "RampLevelStatus_NotDefined" 7 "RampLevelStatus_RampLevelM7" 6 "RampLevelStatus_RampLevelM6" 5 "RampLevelStatus_RampLevelM5" 4 "RampLevelStatus_RampLevelM4" 3 "RampLevelStatus_RampLevelM3" 2 "RampLevelStatus_RampLevelM2" 1 "RampLevelStatus_RampLevelM1" 0 "RampLevelStatus_Inactive" ;
VAL_ 2499755967 RampHeightOutsideTargetRange_ISi 7 "HeightOutsideTargetRange_NotAvailable" 6 "HeightOutsideTargetRange_Error" 5 "HeightOutsideTargetRange_NotDefined_02" 4 "HeightOutsideTargetRange_NotDefined_01" 3 "HeightOutsideTargetRange_NotDefined" 2 "HeightOutsideTargetRange_ToHigh" 1 "HeightOutsideTargetRange_ToLow" 0 "HeightOutsideTargetRange_Inactive" ;
VAL_ 2499755967 RearEndPositionStatus_ISig_5 7 "EndPositionStatus_NotAvailable" 6 "EndPositionStatus_Error" 5 "EndPositionStatus_Reserved_01" 4 "EndPositionStatus_Reserved" 3 "EndPositionStatus_LiftingAndLoweringNotAllowed" 2 "EndPositionStatus_MinEndLevelReached" 1 "EndPositionStatus_MaxEndLevelReached" 0 "EndPositionStatus_NoEndLevelReached" ;
VAL_ 2432687168 Pto1Status_ISig_5 3 "InactiveActive_NotAvailable" 2 "InactiveActive_Error" 1 "InactiveActive_Active" 0 "InactiveActive_Inactive" ;
VAL_ 2432687168 BodyOrCabWorkingLightFdbk_stat_I 3 "OffOn_NotAvailable" 2 "OffOn_Error" 1 "OffOn_On" 0 "OffOn_Off" ;
VAL_ 2432687168 ElectricalLoadReduction_rqst_ISi 7 "ElectricalLoadReduction_rqst_NotAvailable" 6 "ElectricalLoadReduction_rqst_Error" 5 "ElectricalLoadReduction_rqst_SpareValue_02" 4 "ElectricalLoadReduction_rqst_SpareValue_01" 3 "ElectricalLoadReduction_rqst_SpareValue" 2 "ElectricalLoadReduction_rqst_Level2Request" 1 "ElectricalLoadReduction_rqst_Level1Request" 0 "ElectricalLoadReduction_rqst_NoRequest" ;
VAL_ 2432687168 CabWrknLightChassisFdbk_stat_ISi 3 "OffOn_NotAvailable" 2 "OffOn_Error" 1 "OffOn_On" 0 "OffOn_Off" ;
VAL_ 2432687168 ExtraBBTailLiftStatus_ISig_5 3 "InactiveActive_NotAvailable" 2 "InactiveActive_Error" 1 "InactiveActive_Active" 0 "InactiveActive_Inactive" ;
VAL_ 2432687168 ExtraBBCraneStatus_ISig_5 7 "ExtraBBCraneStatus_NotAvailable" 6 "ExtraBBCraneStatus_Error" 5 "ExtraBBCraneStatus_Spare_02" 4 "ExtraBBCraneStatus_Spare_01" 3 "ExtraBBCraneStatus_Spare" 2 "ExtraBBCraneStatus_Active" 1 "ExtraBBCraneStatus_Enable" 0 "ExtraBBCraneStatus_Disable" ;
VAL_ 2432687168 Pto3Status_ISig_5 3 "InactiveActive_NotAvailable" 2 "InactiveActive_Error" 1 "InactiveActive_Active" 0 "InactiveActive_Inactive" ;
VAL_ 2432687168 CabExtraSideWrknLightFdbk_stat_I 3 "OffOn_NotAvailable" 2 "OffOn_Error" 1 "OffOn_On" 0 "OffOn_Off" ;
VAL_ 2432687168 Pto2Status_ISig_5 3 "InactiveActive_NotAvailable" 2 "InactiveActive_Error" 1 "InactiveActive_Active" 0 "InactiveActive_Inactive" ;
VAL_ 2432687168 CabBeaconLightFeedback_Status_IS 3 "OffOn_NotAvailable" 2 "OffOn_Error" 1 "OffOn_On" 0 "OffOn_Off" ;
VAL_ 2432687168 AudioSourceStatus_ISig_5 7 "AudioSourceStatus_NotAvailable" 6 "AudioSourceStatus_Error" 5 "AudioSourceStatus_AUX1" 4 "AudioSourceStatus_iPod" 3 "AudioSourceStatus_AUX2" 2 "AudioSourceStatus_USB" 1 "AudioSourceStatus_CD" 0 "AudioSourceStatus_Radio" ;
VAL_ 2432687168 Pto4Status_ISig_5 3 "InactiveActive_NotAvailable" 2 "InactiveActive_Error" 1 "InactiveActive_Active" 0 "InactiveActive_Inactive" ;
VAL_ 2550121792 BatterySOCAlertRawData_rqst_ISig 7 "BatterySOCAlert_rqst_NotAvailable" 6 "BatterySOCAlert_rqst_ErrorIndicator" 5 "BatterySOCAlert_rqst_SpareValue_02" 4 "BatterySOCAlert_rqst_SpareValue_01" 3 "BatterySOCAlert_rqst_SpareValue" 2 "BatterySOCAlert_rqst_CriticalAlert" 1 "BatterySOCAlert_rqst_PreAlert" 0 "BatterySOCAlert_rqst_NoAlertRequested" ;
VAL_ 2432669248 AuxSwitchBbLoad2_Status_ISig_5 3 "InactiveActive_NotAvailable" 2 "InactiveActive_Error" 1 "InactiveActive_Active" 0 "InactiveActive_Inactive" ;
VAL_ 2432669248 DoorLock_stat_ISig_5 15 "DoorLock_stat_NotAvailable" 14 "DoorLock_stat_Error" 4 "DoorLock_stat_BothDoorsAreLocked" 3 "DoorLock_stat_PassengerDoorIsUnlocked" 2 "DoorLock_stat_DriverDoorIsUnlocked" 1 "DoorLock_stat_BothDoorsAreUnlocked" 0 "DoorLock_stat_Idle" ;
VAL_ 2432669248 MirrorHeatNormalModeInd_cmd_2_IS 3 "DeviceIndication_SpareValue" 2 "DeviceIndication_Blink" 1 "DeviceIndication_On" 0 "DeviceIndication_Off" ;
VAL_ 2432669248 PSWindowPosition_ISig_5 7 "WindowPosition_NotAvailable" 6 "WindowPosition_Error" 5 "WindowPosition_Spare" 4 "WindowPosition_UnknownPosition" 3 "WindowPosition_Open_70_100Percent" 2 "WindowPosition_Open_30_70Percent" 1 "WindowPosition_Open_0_30Percent" 0 "WindowPosition_Closed" ;
VAL_ 2432669248 AuxSwitchBbLoad1_Status_ISig_5 3 "InactiveActive_NotAvailable" 2 "InactiveActive_Error" 1 "InactiveActive_Active" 0 "InactiveActive_Inactive" ;
VAL_ 2432669248 ReducedLoadMode_stat_ISig_5 3 "ReducedLoadMode_stat_NotAvailable" 2 "ReducedLoadMode_stat_Error" 1 "ReducedLoadMode_stat_ReducedLoadMode" 0 "ReducedLoadMode_stat_NormalMode" ;
VAL_ 2432669248 DriverDoorAjar_stat_ISig_5 7 "DoorAjar_stat_NotAvailable" 6 "DoorAjar_stat_Error" 2 "DoorAjar_stat_DoorOpen" 1 "DoorAjar_stat_DoorClosed" 0 "DoorAjar_stat_Idle" ;
VAL_ 2432669248 AuxSwitchBbLoad6_Status_ISig_5 3 "InactiveActive_NotAvailable" 2 "InactiveActive_Error" 1 "InactiveActive_Active" 0 "InactiveActive_Inactive" ;
VAL_ 2432669248 BunkBacklightCmd_ISig_5 31 "BacklightCmd_NotAvailable" 30 "BacklightCmd_Error" 16 "BacklightCmd_BacklightLevel16" 15 "BacklightCmd_BacklightLevel15" 14 "BacklightCmd_BacklightLevel14" 13 "BacklightCmd_BacklightLevel13" 12 "BacklightCmd_BacklightLevel12" 11 "BacklightCmd_BacklightLevel11" 10 "BacklightCmd_BacklightLevel10" 9 "BacklightCmd_BacklightLevel9" 8 "BacklightCmd_BacklightLevel8" 7 "BacklightCmd_BacklightLevel7" 6 "BacklightCmd_BacklightLevel6" 5 "BacklightCmd_BacklightLevel5" 4 "BacklightCmd_BacklightLevel4" 3 "BacklightCmd_BacklightLevel3" 2 "BacklightCmd_BacklightLevel2" 1 "BacklightCmd_BacklightLevel1" 0 "BacklightCmd_BacklightOff" ;
VAL_ 2432669248 AuxSwitchBbLoad4_Status_ISig_5 3 "InactiveActive_NotAvailable" 2 "InactiveActive_Error" 1 "InactiveActive_Active" 0 "InactiveActive_Inactive" ;
VAL_ 2432669248 DSWindowPosition_ISig_5 7 "WindowPosition_NotAvailable" 6 "WindowPosition_Error" 5 "WindowPosition_Spare" 4 "WindowPosition_UnknownPosition" 3 "WindowPosition_Open_70_100Percent" 2 "WindowPosition_Open_30_70Percent" 1 "WindowPosition_Open_0_30Percent" 0 "WindowPosition_Closed" ;
VAL_ 2432669248 SelectedLanguage_stat_ISig_5 63 "Language_NotAvailable" 62 "Language_Error" 61 "Language_Spare_26" 60 "Language_Spare_25" 59 "Language_Spare_24" 58 "Language_Spare_23" 57 "Language_Spare_22" 56 "Language_Spare_21" 55 "Language_Spare_20" 54 "Language_Spare_19" 53 "Language_Spare_18" 52 "Language_Spare_17" 51 "Language_Spare_16" 50 "Language_Spare_15" 49 "Language_Spare_14" 48 "Language_Spare_13" 47 "Language_Spare_12" 46 "Language_Spare_11" 45 "Language_Spare_10" 44 "Language_Spare_09" 43 "Language_Spare_08" 42 "Language_Spare_07" 41 "Language_Spare_06" 40 "Language_Spare_05" 39 "Language_Spare_04" 38 "Language_Malay_Indonesian" 37 "Language_Ukrainian" 36 "Language_Bosnian" 35 "Language_Croatian" 34 "Language_Numeric" 33 "Language_Japanese" 32 "Language_Korean" 31 "Language_Chinese" 30 "Language_Thai" 29 "Language_Arabic" 28 "Language_Farsi" 27 "Language_Hebrew" 26 "Language_Turkish" 25 "Language_Hungarian" 24 "Language_Slovak" 23 "Language_Czech" 22 "Language_Slovenian" 21 "Language_Serbian" 20 "Language_Greek" 19 "Language_Bulgarian" 18 "Language_Italian" 17 "Language_Dutch" 16 "Language_Rumanian" 15 "Language_BrazilianPortugese" 14 "Language_Portugese" 13 "Language_Spanish" 12 "Language_French" 11 "Language_German" 10 "Language_Polish" 9 "Language_Lituanian" 8 "Language_Latvian" 7 "Language_Estonian" 6 "Language_Russian" 5 "Language_Finish" 4 "Language_Icelandic" 3 "Language_Norwegian" 2 "Language_Danish" 1 "Language_Swedish" 0 "Language_English" ;
VAL_ 2432669248 PassengerDoorAjar_stat_ISig_5 7 "DoorAjar_stat_NotAvailable" 6 "DoorAjar_stat_Error" 2 "DoorAjar_stat_DoorOpen" 1 "DoorAjar_stat_DoorClosed" 0 "DoorAjar_stat_Idle" ;
VAL_ 2432669248 BunkB1ParkHeaterTempSw_stat 7 "A3PosSwitchStatus_NotAvailable" 6 "A3PosSwitchStatus_Error" 5 "A3PosSwitchStatus_Spare_02" 4 "A3PosSwitchStatus_Spare_01" 3 "A3PosSwitchStatus_Spare" 2 "A3PosSwitchStatus_Upper" 1 "A3PosSwitchStatus_Lower" 0 "A3PosSwitchStatus_Middle" ;
VAL_ 2432669248 AuxSwitchBbLoad5_Status_ISig_5 3 "InactiveActive_NotAvailable" 2 "InactiveActive_Error" 1 "InactiveActive_Active" 0 "InactiveActive_Inactive" ;
VAL_ 2432669248 AuxSwitchBbLoad3_Status_ISig_5 3 "InactiveActive_NotAvailable" 2 "InactiveActive_Error" 1 "InactiveActive_Active" 0 "InactiveActive_Inactive" ;
VAL_ 2432669248 BunkH2TempInc_ButtonStatus 3 "PushButtonStatus_NotAvailable" 2 "PushButtonStatus_Error" 1 "PushButtonStatus_Pushed" 0 "PushButtonStatus_Neutral" ;
VAL_ 2432669248 DayOfWeek_stat_ISig_5 15 "DayOfWeek_NotAvailable" 14 "DayOfWeek_Error" 13 "DayOfWeek_Spare_7" 12 "DayOfWeek_Spare_6" 11 "DayOfWeek_Spare_5" 10 "DayOfWeek_Spare_4" 9 "DayOfWeek_Spare_3" 8 "DayOfWeek_Spare_2" 7 "DayOfWeek_Spare_1" 6 "DayOfWeek_Sunday" 5 "DayOfWeek_Saturday" 4 "DayOfWeek_Friday" 3 "DayOfWeek_Thursday" 2 "DayOfWeek_Wednesday" 1 "DayOfWeek_Tuesday" 0 "DayOfWeek_Monday" ;
SIG_GROUP_ 2566356800 PHTimerTGWEvCmd_sg_ISig_5 1 : PHTimerTGWEvCmd_Timer3Recur_ISig PHTimerTGWEvCmd_PhTimer1_cmd_ISi PHTimerTGWEvCmd_Timer2Minutes_IS PHTimerTGWEvCmd_Timer2Hours_ISig PHTimerTGWEvCmd_Timer1Hours_ISig PHTimerTGWEvCmd_Timer3StartDay_I PHTimerTGWEvCmd_Timer1Temp_ISig_ PHTimerTGWEvCmd_Timer1Minutes_IS PHTimerTGWEvCmd_Timer2StartDay_I PHTimerTGWEvCmd_PhTimer2_cmd_ISi PHTimerTGWEvCmd_Timer2Temp_ISig_ PHTimerTGWEvCmd_Timer1Duration_I PHTimerTGWEvCmd_Timer3Minutes_IS PHTimerTGWEvCmd_Timer1StartDay_I PHTimerTGWEvCmd_Timer1Recur_ISig PHTimerTGWEvCmd_Timer2Recur_ISig PHTimerTGWEvCmd_PhTimer3_cmd_ISi PHTimerTGWEvCmd_Timer3Temp_ISig_ PHTimerTGWEvCmd_Timer3Hours_ISig;
SIG_GROUP_ 2516128064 Trailer2LiftAxles_sg_ISig_5 1 : Trailer2LiftAxles_LiftAxle1Pos_I Trailer2LiftAxles_LiftAxle2Id_IS Trailer2LiftAxles_LiftAxle2Pos_I Trailer2LiftAxles_LiftAxle1Id_IS;
SIG_GROUP_ 2516128064 Trailer4LiftAxles_sg_ISig_5 1 : Trailer4LiftAxles_LiftAxle1Pos_I Trailer4LiftAxles_LiftAxle2Pos_I Trailer4LiftAxles_LiftAxle1Id_IS Trailer4LiftAxles_LiftAxle2Id_IS;
SIG_GROUP_ 2516128064 Trailer1LiftAxles_sg_ISig_5 1 : Trailer1LiftAxles_LiftAxle2Id_IS Trailer1LiftAxles_LiftAxle1Id_IS Trailer1LiftAxles_LiftAxle2Pos_I Trailer1LiftAxles_LiftAxle1Pos_I;
SIG_GROUP_ 2516128064 Trailer3LiftAxles_sg_ISig_5 1 : Trailer3LiftAxles_LiftAxle2Id_IS Trailer3LiftAxles_LiftAxle1Pos_I Trailer3LiftAxles_LiftAxle1Id_IS Trailer3LiftAxles_LiftAxle2Pos_I;
SIG_GROUP_ 2516128064 Trailer5LiftAxles_sg_ISig_5 1 : Trailer5LiftAxles_LiftAxle2Id_IS Trailer5LiftAxles_LiftAxle1Pos_I Trailer5LiftAxles_LiftAxle1Id_IS Trailer5LiftAxles_LiftAxle2Pos_I;
SIG_GROUP_ 2499679296 PHTimerRqstAck_sg_ISig_5 1 : PHTimerRqstAck_Hours_ISig_5 PHTimerRqstAck_DayOfWeekRq_ISig_ PHTimerRqstAck_Minutes_ISig_5 PHTimerRqstAck_CurrentOp_ISig_5;
SIG_GROUP_ 2566670335 Trailer5CalAxleLoad_sg_ISig_5 1 : Trailer5CalAxleLoad_AxleLoad_ISi Trailer5CalAxleLoad_AxleId_ISig_;
SIG_GROUP_ 2566531071 Trailer4CalAxleLoad_sg_ISig_5 1 : Trailer4CalAxleLoad_AxleId_ISig_ Trailer4CalAxleLoad_AxleLoad_ISi;
SIG_GROUP_ 2566391807 Trailer3CalAxleLoad_sg_ISig_5 1 : Trailer3CalAxleLoad_AxleLoad_ISi Trailer3CalAxleLoad_AxleId_ISig_;
SIG_GROUP_ 2566252543 Trailer2CalAxleLoad_sg_ISig_5 1 : Trailer2CalAxleLoad_AxleId_ISig_ Trailer2CalAxleLoad_AxleLoad_ISi;
SIG_GROUP_ 2566113279 Trailer1CalAxleLoad_sg_ISig_5 1 : Trailer1CalAxleLoad_AxleId_ISig_ Trailer1CalAxleLoad_AxleLoad_ISi;
SIG_GROUP_ 2565904383 AlarmClockAlarms_stat_sg_ISig_5 1 : AlarmClockAlarms_stat_SetMin_ISi AlarmClockAlarms_stat_Mode_ISig_ AlarmClockAlarms_stat_SetHr_ISig AlarmClockAlarms_stat_ID_ISig_5 AlarmClockAlarms_stat_DaySet_ISi AlarmClockAlarms_stat_Stat_ISig_ AlarmClockAlarms_stat_Type_ISig_;
SIG_GROUP_ 2565904383 ESCReqESC_sg_ISig_5 1 : ESCReqESC_CtrlTrimValue_ISig_5 ESCReqESC_CtrlTrimReq_ISig_5 ESCReqESC_CtrlTrimMode_ISig_5 ESCReqESC_CtrlTrimStat_ISig_5;
SIG_GROUP_ 2565904383 AlarmClockNotification_sg_ISig_5 1 : AlarmClockNotification_Stat_ISig AlarmClockNotification_Type_ISig AlarmClockNotification_ID_ISig_5;
